VERSION "HNNBNNNYNNNNNNNNNNNNNNNNNNNNNNNNNNNNNNNNNN/4/%%%/4/'%**4NNN///"

NS_ :

BS_:

BU_: BAP_Tester BCM1 Gateway Gateway_PAG Klima_MSB Lift_VA VAS_L VAS_R

BO_ 1648 Motor_18: 8 Gateway
 SG_ MO_max_Ladedruck : 0|6@1+ (0.1,0) [0.0|6.3] "Unit_Bar"  Vector__XXX
 SG_ MO_ANC_Kennfeld_Anf : 6|2@1+ (1.0,0.0) [0.0|3] ""  Vector__XXX
 SG_ MO_Bremslicht_Reku : 8|1@1+ (1.0,0.0) [0.0|1] ""  Vector__XXX
 SG_ MO_StartStopp_PopUp : 9|2@1+ (1.0,0.0) [0.0|3] ""  Vector__XXX
 SG_ MO1_Sperr_Info_WFS : 11|1@1+ (1.0,0.0) [0.0|1] ""  Vector__XXX
 SG_ MO1_Freigabe_Info_WFS : 12|1@1+ (1.0,0.0) [0.0|1] ""  Vector__XXX
 SG_ MO_EPCL : 13|3@1+ (1.0,0.0) [0.0|7] ""  Vector__XXX
 SG_ MO_Zylabsch_Texte_02 : 16|4@1+ (1.0,0.0) [0.0|15] ""  Vector__XXX
 SG_ MO_Fahrzeugtyp : 20|3@1+ (1.0,0.0) [0.0|7] ""  Vector__XXX
 SG_ MO_NMAX_Schaltanzeige : 23|9@1+ (25,0) [0|12775] "Unit_MinutInver"  Vector__XXX
 SG_ MO_Abstellzeit : 32|8@1+ (8,0) [0|2024] "Unit_Minut"  BCM1,Klima_MSB
 SG_ MO_Abstellzeit_Status : 40|2@1+ (1.0,0.0) [0.0|3] ""  BCM1,Klima_MSB
 SG_ MO1_Freigabe_Verfallsinfo_WFS : 42|1@1+ (1.0,0.0) [0.0|1] ""  Vector__XXX
 SG_ MO_Hybrid_StartStopp_LED : 43|2@1+ (1.0,0.0) [0.0|3] ""  BCM1
 SG_ MO_Fehler_Zylabsch : 45|2@1+ (1.0,0.0) [0.0|3] ""  Vector__XXX
 SG_ MO_Anzahl_Abgesch_Zyl : 47|3@1+ (1.0,0.0) [0.0|7] ""  Vector__XXX
 SG_ MO_Zylabsch_Texte : 50|2@1+ (1.0,0.0) [0.0|3] ""  Vector__XXX
 SG_ MO_Ethanol_BS_Texte : 52|3@1+ (1.0,0.0) [0.0|7] ""  Vector__XXX
 SG_ MO_Drehzahl_Warnung : 55|1@1+ (1.0,0.0) [0.0|1] ""  Vector__XXX
 SG_ MO_obere_Drehzahlgrenze : 56|8@1+ (50,0) [50|12750] "Unit_MinutInver"  Vector__XXX

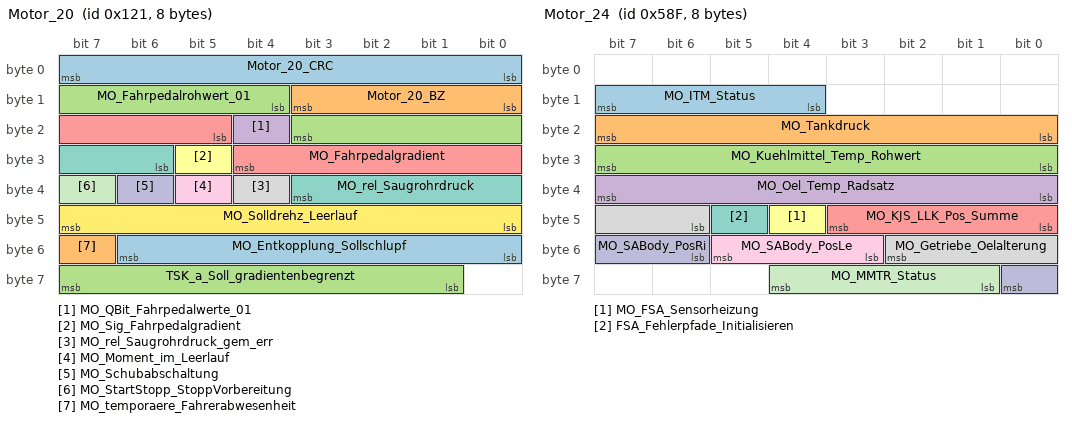
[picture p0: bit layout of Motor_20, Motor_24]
BO_ 289 Motor_20: 8 Gateway
 SG_ Motor_20_CRC : 0|8@1+ (1,0) [0|255] ""  Vector__XXX
 SG_ Motor_20_BZ : 8|4@1+ (1,0) [0|15] ""  Vector__XXX
 SG_ MO_Fahrpedalrohwert_01 : 12|8@1+ (0.4,0) [0.0|101.6] "Unit_PerCent"  BCM1
 SG_ MO_QBit_Fahrpedalwerte_01 : 20|1@1+ (1.0,0.0) [0.0|1] ""  Vector__XXX
 SG_ MO_Fahrpedalgradient : 21|8@1+ (25,0) [0|6350] "Unit_PerCentPerSecon"  Vector__XXX
 SG_ MO_Sig_Fahrpedalgradient : 29|1@1+ (1.0,0.0) [0.0|1] ""  Vector__XXX
 SG_ MO_rel_Saugrohrdruck : 30|6@1+ (18,0) [0|1116] "Unit_MilliBar"  Vector__XXX
 SG_ MO_rel_Saugrohrdruck_gem_err : 36|1@1+ (1.0,0.0) [0.0|1] ""  Vector__XXX
 SG_ MO_Moment_im_Leerlauf : 37|1@1+ (1.0,0.0) [0.0|1] ""  Vector__XXX
 SG_ MO_Schubabschaltung : 38|1@1+ (1.0,0.0) [0.0|1] ""  Vector__XXX
 SG_ MO_StartStopp_StoppVorbereitung : 39|1@1+ (1.0,0.0) [0.0|1] ""  Vector__XXX
 SG_ MO_Solldrehz_Leerlauf : 40|8@1+ (10,0) [0|2540] "Unit_MinutInver"  Vector__XXX
 SG_ MO_Entkopplung_Sollschlupf : 48|7@1+ (20,0) [0|2480] "Unit_MinutInver"  Vector__XXX
 SG_ MO_temporaere_Fahrerabwesenheit : 55|1@1+ (1.0,0.0) [0.0|1] ""  Vector__XXX
 SG_ TSK_a_Soll_gradientenbegrenzt : 57|7@1+ (0.1,-7.2) [-7.2|5.4] "Unit_MeterPerSeconSquar"  Vector__XXX

BO_ 1423 Motor_24: 8 Gateway
 SG_ MO_ITM_Status : 12|4@1+ (1.0,0.0) [0.0|15] ""  BCM1,Klima_MSB
 SG_ MO_Tankdruck : 16|8@1+ (2,-250) [-250|256] "Unit_MilliBar"  Vector__XXX
 SG_ MO_Kuehlmittel_Temp_Rohwert : 24|8@1+ (0.75,-48) [-48.00|141.75] "Unit_DegreCelsi"  Vector__XXX
 SG_ MO_Oel_Temp_Radsatz : 32|8@1+ (1,-60) [-60|193] "Unit_DegreCelsi"  Vector__XXX
 SG_ MO_KJS_LLK_Pos_Summe : 40|4@1+ (10,0) [0|100] "Unit_PerCent"  Vector__XXX
 SG_ MO_FSA_Sensorheizung : 44|1@1+ (1.0,0.0) [0.0|1] ""  BCM1
 SG_ FSA_Fehlerpfade_Initialisieren : 45|1@1+ (1.0,0.0) [0.0|1] ""  BCM1
 SG_ MO_Getriebe_Oelalterung : 46|5@1+ (5,0) [0|100] "Unit_PerCent"  Vector__XXX
 SG_ MO_SABody_PosLe : 51|3@1+ (20,-20) [0|100] "Unit_PerCent"  Vector__XXX
 SG_ MO_SABody_PosRi : 54|3@1+ (20,-20) [0|100] "Unit_PerCent"  Vector__XXX
 SG_ MO_MMTR_Status : 57|4@1+ (1.0,0.0) [0.0|15] ""  Klima_MSB

BO_ 967 Motor_26: 8 Gateway
 SG_ MO_Kuehlerluefter_MUX M  : 0|1@1+ (1.0,0.0) [0.0|1] ""  BCM1,Klima_MSB
 SG_ MO_Kuehlerluefter_1 m0  : 1|7@1+ (1,0) [0|100] "Unit_PerCent"  BCM1,Klima_MSB
 SG_ MO_Kuehlerluefter_2 m1  : 1|7@1+ (1,0) [0|100] "Unit_PerCent"  BCM1,Klima_MSB
 SG_ MO_EFLEX_Lampe : 8|2@1+ (1.0,0.0) [0.0|3] ""  Vector__XXX
 SG_ MO_KJS_nicht_bereit : 10|1@1+ (1.0,0.0) [0.0|1] ""  Vector__XXX
 SG_ MO_ITM_Warnung_Pumpe : 11|1@1+ (1.0,0.0) [0.0|1] ""  Vector__XXX
 SG_ WIV_Anzeige_aktiv : 12|1@1+ (1.0,0.0) [0.0|1] ""  Vector__XXX
 SG_ WIV_Oelmin_Warn : 13|1@1+ (1.0,0.0) [0.0|1] ""  Vector__XXX
 SG_ WIV_Sensorfehler : 14|1@1+ (1.0,0.0) [0.0|1] ""  Vector__XXX
 SG_ WIV_Schieflage : 15|1@1+ (1.0,0.0) [0.0|1] ""  Vector__XXX
 SG_ WIV_Oelstand : 16|4@1+ (12.5,0) [0.0|100.0] "Unit_PerCent"  Vector__XXX
 SG_ MO_Zustand_HWP : 20|2@1+ (1.0,0.0) [0.0|3] ""  Vector__XXX
 SG_ OLEV_Systemstoerung : 22|1@1+ (1.0,0.0) [0.0|1] ""  Vector__XXX
 SG_ MO_Oelwarnung_max : 23|1@1+ (1.0,0.0) [0.0|1] ""  Vector__XXX
 SG_ WIV_Oelsystem_aktiv : 24|1@1+ (1.0,0.0) [0.0|1] ""  Vector__XXX
 SG_ WIV_nicht_betriebswarm : 25|1@1+ (1.0,0.0) [0.0|1] ""  Vector__XXX
 SG_ WIV_Ueberfuell_Warn : 26|1@1+ (1.0,0.0) [0.0|1] ""  Vector__XXX
 SG_ WIV_laufender_Motor : 27|1@1+ (1.0,0.0) [0.0|1] ""  Vector__XXX
 SG_ MO_E_Warnungen : 28|4@1+ (1.0,0.0) [0.0|15] ""  Vector__XXX
 SG_ MO_Text_Motorstart : 32|4@1+ (1.0,0.0) [0.0|15] ""  Vector__XXX
 SG_ MO_E_Texte : 36|4@1+ (1.0,0.0) [0.0|15] ""  Vector__XXX
 SG_ WIV_Oeldyn_avl : 40|1@1+ (1.0,0.0) [0.0|1] ""  Vector__XXX
 SG_ MO_Text_Partikelfil_Reg : 41|1@1+ (1,0) [0|1] ""  Vector__XXX
 SG_ OLEV_Oelstand_nicht_vorhanden : 42|1@1+ (1.0,0.0) [0.0|1] ""  Vector__XXX
 SG_ WIV_Oelmenge : 43|5@1+ (125,0) [0|3875] "Unit_MilliLiter"  Vector__XXX
 SG_ MO_Systemlampe : 48|1@1+ (1.0,0.0) [0.0|1] ""  Vector__XXX
 SG_ MO_OBD2_Lampe : 49|1@1+ (1.0,0.0) [0.0|1] ""  Vector__XXX
 SG_ MO_Heissleuchte : 50|1@1+ (1.0,0.0) [0.0|1] ""  Vector__XXX
 SG_ MO_Partikel_Lampe : 51|1@1+ (1.0,0.0) [0.0|1] ""  Vector__XXX
 SG_ MO_RedFahrleistung_Lampe : 52|1@1+ (1.0,0.0) [0.0|1] ""  Vector__XXX
 SG_ WIV_Oelstand_nicht_vorhanden : 53|1@1+ (1.0,0.0) [0.0|1] ""  Vector__XXX
 SG_ WIV_nachfuellanzeige_ein : 54|1@1+ (1.0,0.0) [0.0|1] ""  Vector__XXX
 SG_ WIV_Ueberfuell_deaktiv : 55|1@1+ (1.0,0.0) [0.0|1] ""  Vector__XXX
 SG_ WIV_Unterfuell_Warn : 56|1@1+ (1.0,0.0) [0.0|1] ""  Vector__XXX
 SG_ MO_Tankdeckel_Lampe : 57|1@1+ (1.0,0.0) [0.0|1] ""  Vector__XXX
 SG_ MO_Text_Tankdeckelwarn : 58|1@1+ (1.0,0.0) [0.0|1] ""  Vector__XXX
 SG_ MO_Vorglueh_Lampe : 59|1@1+ (1.0,0.0) [0.0|1] ""  Vector__XXX
 SG_ WIV_Oeldr_Warn_Motor : 60|1@1+ (1.0,0.0) [0.0|1] ""  Vector__XXX
 SG_ MO_E_Mode : 61|3@1+ (1.0,0.0) [0.0|7] ""  Vector__XXX

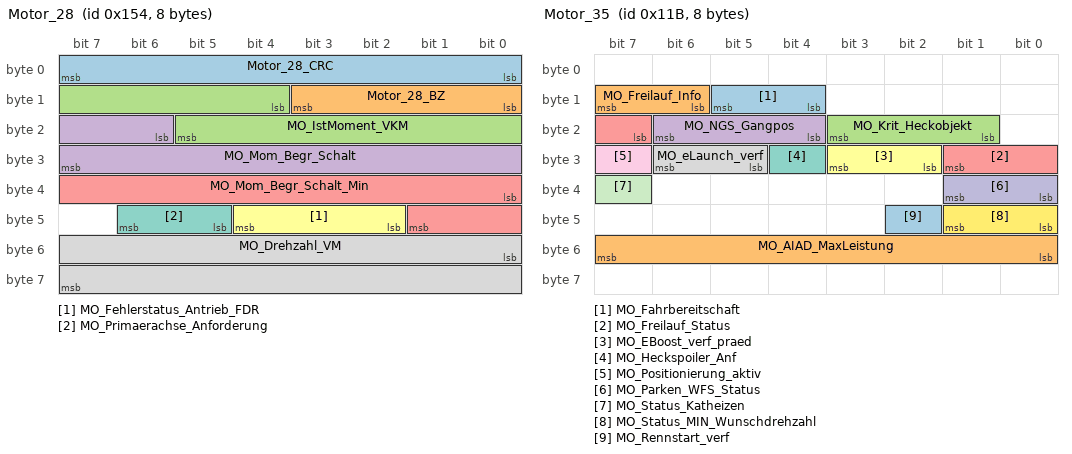
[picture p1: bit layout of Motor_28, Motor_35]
BO_ 340 Motor_28: 8 Gateway
 SG_ Motor_28_CRC : 0|8@1+ (1,0) [0|255] ""  Vector__XXX
 SG_ Motor_28_BZ : 8|4@1+ (1,0) [0|15] ""  Vector__XXX
 SG_ MO_IstMoment_VKM : 12|10@1+ (1,-509) [-509|509] ""  Vector__XXX
 SG_ MO_Mom_Begr_Schalt : 22|10@1+ (1,-509) [-509|509] ""  Vector__XXX
 SG_ MO_Mom_Begr_Schalt_Min : 32|10@1+ (1,-509) [-509|509] ""  Vector__XXX
 SG_ MO_Fehlerstatus_Antrieb_FDR : 42|3@1+ (1.0,0.0) [0.0|7] ""  Vector__XXX
 SG_ MO_Primaerachse_Anforderung : 45|2@1+ (1.0,0.0) [0.0|3] ""  Vector__XXX
 SG_ MO_Drehzahl_VM : 48|16@1+ (0.25,0) [0.00|16383.00] "Unit_MinutInver"  BCM1,Klima_MSB

BO_ 283 Motor_35: 8 Gateway
 SG_ MO_Fahrbereitschaft : 12|2@1+ (1.0,0.0) [0.0|3] ""  BCM1
 SG_ MO_Freilauf_Info : 14|2@1+ (1.0,0.0) [0.0|3] ""  Vector__XXX
 SG_ MO_Krit_Heckobjekt : 17|3@1+ (1.0,0.0) [0.0|7] ""  Vector__XXX
 SG_ MO_NGS_Gangpos : 20|3@1+ (1.0,0.0) [0.0|7] ""  Vector__XXX
 SG_ MO_Freilauf_Status : 23|3@1+ (1.0,0.0) [0.0|7] ""  Vector__XXX
 SG_ MO_EBoost_verf_praed : 26|2@1+ (1.0,0.0) [0.0|3] ""  Vector__XXX
 SG_ MO_Heckspoiler_Anf : 28|1@1+ (1.0,0.0) [0.0|1] ""  Vector__XXX
 SG_ MO_eLaunch_verf : 29|2@1+ (1.0,0.0) [0.0|3] ""  Vector__XXX
 SG_ MO_Positionierung_aktiv : 31|1@1+ (1.0,0.0) [0.0|1] ""  Vector__XXX
 SG_ MO_Parken_WFS_Status : 32|2@1+ (1.0,0.0) [0.0|3] ""  Vector__XXX
 SG_ MO_Status_Katheizen : 39|1@1+ (1.0,0.0) [0.0|1] ""  Vector__XXX
 SG_ MO_Status_MIN_Wunschdrehzahl : 40|2@1+ (1.0,0.0) [0.0|3] ""  Vector__XXX
 SG_ MO_Rennstart_verf : 42|1@1+ (1.0,0.0) [0.0|1] ""  Vector__XXX
 SG_ MO_AIAD_MaxLeistung : 48|8@1+ (100,0) [0|25400] "Unit_Watt"  Vector__XXX

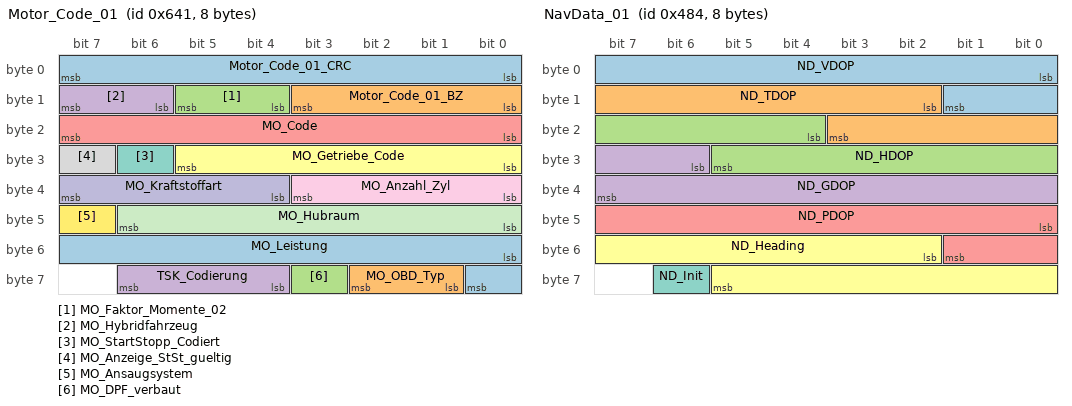
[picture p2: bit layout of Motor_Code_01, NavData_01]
BO_ 1601 Motor_Code_01: 8 Gateway
 SG_ Motor_Code_01_CRC : 0|8@1+ (1,0) [0|255] ""  BCM1
 SG_ Motor_Code_01_BZ : 8|4@1+ (1,0) [0|15] ""  BCM1
 SG_ MO_Faktor_Momente_02 : 12|2@1+ (1,0) [1|3] "Unit_NewtoMeter"  BCM1
 SG_ MO_Hybridfahrzeug : 14|2@1+ (1.0,0.0) [0.0|3] ""  BCM1
 SG_ MO_Code : 16|8@1+ (1,0) [0|255] ""  BCM1,Klima_MSB
 SG_ MO_Getriebe_Code : 24|6@1+ (1.0,0.0) [0.0|63] ""  BCM1,Klima_MSB
 SG_ MO_StartStopp_Codiert : 30|1@1+ (1.0,0.0) [0.0|1] ""  Lift_VA
 SG_ MO_Anzeige_StSt_gueltig : 31|1@1+ (1.0,0.0) [0.0|1] ""  Vector__XXX
 SG_ MO_Anzahl_Zyl : 32|4@1+ (1.0,0.0) [0.0|15] ""  Vector__XXX
 SG_ MO_Kraftstoffart : 36|4@1+ (1.0,0.0) [0.0|15] ""  BCM1
 SG_ MO_Hubraum : 40|7@1+ (0.1,0) [0.0|12.7] "Unit_Liter"  Vector__XXX
 SG_ MO_Ansaugsystem : 47|1@1+ (1.0,0.0) [0.0|1] ""  Vector__XXX
 SG_ MO_Leistung : 48|9@1+ (1,0) [0|511] "Unit_KiloWatt"  Vector__XXX
 SG_ MO_OBD_Typ : 57|2@1+ (1.0,0.0) [0.0|3] ""  BCM1
 SG_ MO_DPF_verbaut : 59|1@1+ (1.0,0.0) [0.0|1] ""  Vector__XXX
 SG_ TSK_Codierung : 60|3@1+ (1.0,0.0) [0.0|7] ""  Vector__XXX

BO_ 394 Motor_Hybrid_11: 8 Gateway
 SG_ MO_Ablaufstatus : 12|4@1+ (1.0,0.0) [0.0|15] ""  Vector__XXX
 SG_ MO_Ablaufstrg_Betriebszustand : 16|3@1+ (1.0,0.0) [0.0|7] ""  Vector__XXX
 SG_ MO_Ablaufstrg_Zustand_VKM_Ist : 19|1@1+ (1.0,0.0) [0.0|1] ""  Vector__XXX
 SG_ MO_Ablaufstrg_Kraftschluss_Ist : 20|1@1+ (1.0,0.0) [0.0|1] ""  Vector__XXX
 SG_ MO_Ablaufstrg_Zustand_K0_Ist : 21|1@1+ (1.0,0.0) [0.0|1] ""  Vector__XXX
 SG_ MO_Ablaufstrg_Kraftschluss2_Ist : 22|1@1+ (1.0,0.0) [0.0|1] ""  Vector__XXX
 SG_ MO_HYB_LowSpeedModus : 23|1@1+ (1.0,0.0) [0.0|1] ""  Vector__XXX
 SG_ MO_Ablaufstrg_Zustand_VKM_Ziel : 24|1@1+ (1.0,0.0) [0.0|1] ""  Vector__XXX
 SG_ MO_Ablaufstrg_Kraftschluss_Ziel : 25|1@1+ (1.0,0.0) [0.0|1] ""  Vector__XXX
 SG_ MO_Ablaufstrg_Zustand_K0_Ziel : 26|1@1+ (1.0,0.0) [0.0|1] ""  Vector__XXX
 SG_ MO_Ablaufstrg_Kraftschluss2_Ziel : 27|1@1+ (1.0,0.0) [0.0|1] ""  Vector__XXX
 SG_ MO_HYB_Stoppmodus : 28|1@1+ (1.0,0.0) [0.0|1] ""  Vector__XXX
 SG_ MO_Auth_Aufforderung_WFS : 29|1@1+ (1.0,0.0) [0.0|1] ""  Vector__XXX
 SG_ MO_Start_Dynamik : 30|3@1+ (1.0,0.0) [0.0|7] ""  Vector__XXX
 SG_ MO_Start_Art : 33|3@1+ (1.0,0.0) [0.0|7] ""  BCM1,Klima_MSB
 SG_ MO_Abstellposition_02 : 36|8@1+ (2,0) [0|508] "Unit_DegreOfArc"  Vector__XXX
 SG_ MO_Mom_Freiheit_Sekundaerachse : 44|1@1+ (1.0,0.0) [0.0|1] ""  Vector__XXX
 SG_ MO_Nachlaufzeit_Kuehlerluefter : 45|6@1+ (15,0) [0|945] "Unit_Secon"  Vector__XXX
 SG_ MO_Tankklappensteuerung : 51|2@1+ (1.0,0.0) [0.0|3] ""  Vector__XXX
 SG_ MO_HYB_E_Faktor : 53|4@1+ (1.0,0.0) [0.0|15] ""  Vector__XXX
 SG_ MO_HYB_EMode_Info : 57|2@1+ (1.0,0.0) [0.0|3] ""  Vector__XXX
 SG_ MO_HYB_Adaption_aktiv : 59|1@1+ (1.0,0.0) [0.0|1] ""  Vector__XXX

BO_ 1156 NavData_01: 8 Gateway
 SG_ ND_VDOP : 0|10@1+ (0.025,0) [0.000|25.000] ""  Vector__XXX
 SG_ ND_TDOP : 10|10@1+ (0.025,0) [0.000|25.000] ""  Vector__XXX
 SG_ ND_HDOP : 20|10@1+ (0.025,0) [0.000|25.000] ""  Vector__XXX
 SG_ ND_GDOP : 30|10@1+ (0.025,0) [0.000|25.000] ""  Vector__XXX
 SG_ ND_PDOP : 40|10@1+ (0.025,0) [0.000|25.000] ""  Vector__XXX
 SG_ ND_Heading : 50|12@1+ (0.1,0) [0.0|359.9] "Unit_DegreOfArc"  BCM1,Klima_MSB
 SG_ ND_Init : 62|1@1+ (1.0,0.0) [0.0|1] ""  BCM1

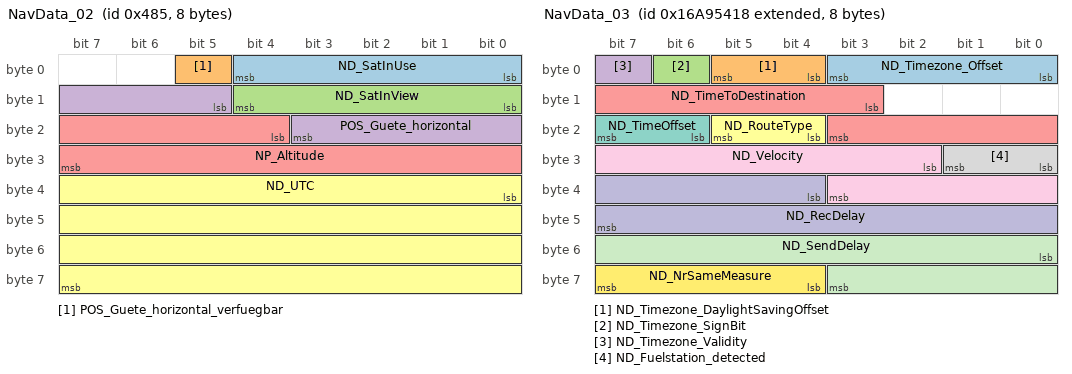
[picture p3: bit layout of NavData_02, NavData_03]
BO_ 1157 NavData_02: 8 Gateway
 SG_ ND_SatInUse : 0|5@1+ (1,0) [0|29] ""  Vector__XXX
 SG_ POS_Guete_horizontal_verfuegbar : 5|1@1+ (1.0,0.0) [0.0|1] ""  Vector__XXX
 SG_ ND_SatInView : 8|5@1+ (1,0) [0|29] ""  Vector__XXX
 SG_ POS_Guete_horizontal : 13|7@1+ (2,0) [0|246] "Unit_Meter"  Vector__XXX
 SG_ NP_Altitude : 20|12@1+ (2,-500) [-500|7686] "Unit_Meter"  BCM1,Klima_MSB
 SG_ ND_UTC : 32|32@1+ (1,0) [0|4294967293] "Unit_Secon"  BCM1

BO_ 2527679512 NavData_03: 8 Gateway
 SG_ ND_Timezone_Offset : 0|4@1+ (1,0) [0|12] "Unit_Hours"  Klima_MSB
 SG_ ND_Timezone_DaylightSavingOffset : 4|2@1+ (30,0) [0|60] "Unit_Minut"  Klima_MSB
 SG_ ND_Timezone_SignBit : 6|1@1+ (1.0,0.0) [0.0|1] ""  Klima_MSB
 SG_ ND_Timezone_Validity : 7|1@1+ (1.0,0.0) [0.0|1] ""  Klima_MSB
 SG_ ND_TimeToDestination : 11|9@1+ (1,0) [0|509] "Unit_Minut"  Vector__XXX
 SG_ ND_RouteType : 20|2@1+ (1.0,0.0) [0.0|3] ""  Vector__XXX
 SG_ ND_TimeOffset : 22|2@1+ (1.0,0.0) [0.0|3] ""  Vector__XXX
 SG_ ND_Fuelstation_detected : 24|2@1+ (1.0,0.0) [0.0|3] ""  Vector__XXX
 SG_ ND_Velocity : 26|10@1+ (0.1,0) [0.0|102.1] "Unit_MeterPerSecon"  Vector__XXX
 SG_ ND_RecDelay : 36|12@1+ (1,0) [0|4093] "Unit_MilliSecon"  Vector__XXX
 SG_ ND_SendDelay : 48|12@1+ (1,0) [0|4093] "Unit_MilliSecon"  Vector__XXX
 SG_ ND_NrSameMeasure : 60|4@1+ (1,0) [0|8] ""  Vector__XXX

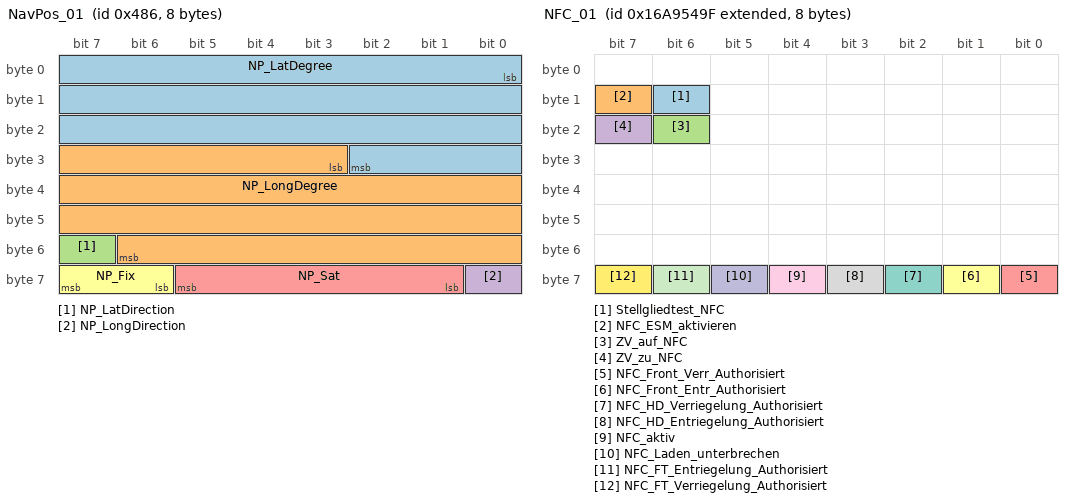
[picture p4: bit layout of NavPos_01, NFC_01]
BO_ 1158 NavPos_01: 8 Gateway
 SG_ NP_LatDegree : 0|27@1+ (0.000001,0) [0.000000|90.000000] "Unit_DegreOfArc"  BCM1,Klima_MSB
 SG_ NP_LongDegree : 27|28@1+ (0.000001,0) [0.000000|180.000000] "Unit_DegreOfArc"  BCM1,Klima_MSB
 SG_ NP_LatDirection : 55|1@1+ (1.0,0.0) [0.0|1] ""  BCM1,Klima_MSB
 SG_ NP_LongDirection : 56|1@1+ (1.0,0.0) [0.0|1] ""  BCM1,Klima_MSB
 SG_ NP_Sat : 57|5@1+ (1,0) [0|29] ""  Vector__XXX
 SG_ NP_Fix : 62|2@1+ (1.0,0.0) [0.0|3] ""  Vector__XXX

BO_ 2589283496 NavPos_02_Map_Matched: 8 Gateway
 SG_ POS_MUX M  : 0|2@1+ (1.0,0.0) [0.0|3] ""  Klima_MSB
 SG_ POS_ODD_EVEN : 2|1@1+ (1.0,0.0) [0.0|1] ""  Vector__XXX
 SG_ POS_PosStati m0  : 3|4@1+ (1.0,0.0) [0.0|15] ""  Klima_MSB
 SG_ POS_Heading m1  : 4|12@1+ (0.1,0) [0.0|409.5] "Unit_DegreOfArc"  Klima_MSB
 SG_ POS_LatDirection m0  : 7|1@1+ (1.0,0.0) [0.0|1] ""  Klima_MSB
 SG_ POS_LatDegree m0  : 8|27@1+ (0.000001,0) [0.000000|90.000000] "Unit_DegreOfArc"  Klima_MSB
 SG_ POS_Last_GPS_Sync m1  : 16|14@1+ (1,0) [0|16383] "Unit_Secon"  Vector__XXX
 SG_ POS_Heading_Trust m1  : 30|2@1+ (1.0,0.0) [0.0|3] ""  Klima_MSB
 SG_ POS_UTC_REF m1  : 32|32@1+ (1,0) [0|4294967295] "Unit_Secon"  Klima_MSB
 SG_ POS_LongDirection m0  : 35|1@1+ (1.0,0.0) [0.0|1] ""  Klima_MSB
 SG_ POS_LongDegree m0  : 36|28@1+ (0.000001,0) [0.000000|180.000000] "Unit_DegreOfArc"  Klima_MSB

BO_ 2527679647 NFC_01: 8 Gateway
 SG_ Stellgliedtest_NFC : 14|1@1+ (1.0,0.0) [0.0|1] ""  Vector__XXX
 SG_ NFC_ESM_aktivieren : 15|1@1+ (1.0,0.0) [0.0|1] ""  Vector__XXX
 SG_ ZV_auf_NFC : 22|1@1+ (1.0,0.0) [0.0|1] ""  BCM1
 SG_ ZV_zu_NFC : 23|1@1+ (1.0,0.0) [0.0|1] ""  BCM1
 SG_ NFC_Front_Verr_Authorisiert : 56|1@1+ (1.0,0.0) [0.0|1] ""  BCM1
 SG_ NFC_Front_Entr_Authorisiert : 57|1@1+ (1.0,0.0) [0.0|1] ""  BCM1
 SG_ NFC_HD_Verriegelung_Authorisiert : 58|1@1+ (1.0,0.0) [0.0|1] ""  Vector__XXX
 SG_ NFC_HD_Entriegelung_Authorisiert : 59|1@1+ (1.0,0.0) [0.0|1] ""  Vector__XXX
 SG_ NFC_aktiv : 60|1@1+ (1.0,0.0) [0.0|1] ""  Vector__XXX
 SG_ NFC_Laden_unterbrechen : 61|1@1+ (1.0,0.0) [0.0|1] ""  Vector__XXX
 SG_ NFC_FT_Entriegelung_Authorisiert : 62|1@1+ (1.0,0.0) [0.0|1] ""  Vector__XXX
 SG_ NFC_FT_Verriegelung_Authorisiert : 63|1@1+ (1.0,0.0) [0.0|1] ""  Vector__XXX

BO_ 1696 NightVision_01: 8 Gateway
 SG_ NV_aktiv : 12|1@1+ (1.0,0.0) [0.0|1] ""  Vector__XXX
 SG_ NV_Texte : 13|3@1+ (1.0,0.0) [0.0|7] ""  Vector__XXX
 SG_ NV_Gong : 16|2@1+ (1.0,0.0) [0.0|3] ""  Vector__XXX
 SG_ NV_Symbol : 18|1@1+ (1.0,0.0) [0.0|1] ""  BCM1
 SG_ NV_Hinweise : 19|2@1+ (1.0,0.0) [0.0|3] ""  Vector__XXX
 SG_ NV_Piktogramm_aktiv : 21|1@1+ (1.0,0.0) [0.0|1] ""  Vector__XXX
 SG_ NV_Akustik_deaktiviert_Icon : 22|1@1+ (1.0,0.0) [0.0|1] ""  Vector__XXX
 SG_ NV_FGM_deaktiviert_Icon : 23|1@1+ (1.0,0.0) [0.0|1] ""  Vector__XXX
 SG_ NV_Markierungslicht_links : 24|1@1+ (1.0,0.0) [0.0|1] ""  Vector__XXX
 SG_ NV_Markierungslicht_rechts : 25|1@1+ (1.0,0.0) [0.0|1] ""  Vector__XXX
 SG_ NV_Symbol_Tierwarnung : 26|1@1+ (1.0,0.0) [0.0|1] ""  BCM1
 SG_ NV_Anf_Prefill : 27|1@1+ (1.0,0.0) [0.0|1] ""  Vector__XXX
 SG_ NV_HBA_Parameter : 28|2@1+ (1.0,0.0) [0.0|3] ""  Vector__XXX
 SG_ NV_LED_Leiste : 30|2@1+ (1.0,0.0) [0.0|3] ""  Vector__XXX
 SG_ NV_PreSense_Status : 32|2@1+ (1.0,0.0) [0.0|3] ""  Vector__XXX
 SG_ NV_PreSense_Modus_System : 34|1@1+ (1.0,0.0) [0.0|1] ""  Vector__XXX
 SG_ NV_PreSense_Modus_Warnung : 35|3@1+ (1.0,0.0) [0.0|7] ""  Vector__XXX
 SG_ NV_FAS_Fkt_Status : 38|2@1+ (1.0,0.0) [0.0|3] ""  Vector__XXX
 SG_ NV_Akt_Status_MMI : 40|2@1+ (1.0,0.0) [0.0|3] ""  Vector__XXX
 SG_ NV_AnforderungBildaufschaltung : 42|1@1+ (1.0,0.0) [0.0|1] ""  Vector__XXX

BO_ 2600468494 NMH_BCM1: 8 BCM1
 SG_ NM_BCM1_SNI : 0|8@1+ (1.0,0.0) [0.0|255] ""  Gateway,Gateway_PAG,Klima_MSB,Lift_VA,VAS_L,VAS_R
 SG_ NM_BCM1_CBV_AWB : 12|1@1+ (1.0,0.0) [0.0|1] ""  Gateway,Gateway_PAG
 SG_ NM_BCM1_CBV_CRI : 14|1@1+ (1.0,0.0) [0.0|1] ""  Gateway,Gateway_PAG,Klima_MSB,Lift_VA,VAS_L,VAS_R
 SG_ NM_BCM1_NM_State : 16|6@1+ (1.0,0.0) [0.0|63] ""  Vector__XXX
 SG_ NM_BCM1_Car_Wakeup : 22|1@1+ (1.0,0.0) [0.0|1] ""  Gateway,Gateway_PAG
 SG_ NM_BCM1_UDS_CC : 23|1@1+ (1.0,0.0) [0.0|1] ""  Vector__XXX
 SG_ NM_BCM1_NM_aktiv_KL15 : 24|1@1+ (1.0,0.0) [0.0|1] ""  Vector__XXX
 SG_ NM_BCM1_NM_aktiv_Diagnose : 25|1@1+ (1.0,0.0) [0.0|1] ""  Vector__XXX
 SG_ NM_BCM1_NM_aktiv_Tmin : 26|1@1+ (1.0,0.0) [0.0|1] ""  Vector__XXX
 SG_ NM_BCM1_NM_aktiv_Notlaufblinken : 27|1@1+ (1.0,0.0) [0.0|1] ""  Vector__XXX
 SG_ NM_BCM1_NM_aktiv_ComingHome : 28|1@1+ (1.0,0.0) [0.0|1] ""  Vector__XXX
 SG_ NM_BCM1_NM_aktiv_LeavingHome : 29|1@1+ (1.0,0.0) [0.0|1] ""  Vector__XXX
 SG_ NM_BCM1_NM_aktiv_Taster_Schalter : 30|1@1+ (1.0,0.0) [0.0|1] ""  Vector__XXX
 SG_ NM_BCM1_NM_aktiv_LIM : 31|1@1+ (1.0,0.0) [0.0|1] ""  Vector__XXX
 SG_ NM_BCM1_NM_aktiv_Innenlicht_Dim : 32|1@1+ (1.0,0.0) [0.0|1] ""  Vector__XXX
 SG_ NM_BCM1_NM_aktiv_Aussenlicht : 33|1@1+ (1.0,0.0) [0.0|1] ""  Vector__XXX
 SG_ NM_BCM1_NM_aktiv_Klimatisierung : 34|1@1+ (1.0,0.0) [0.0|1] ""  Vector__XXX
 SG_ NM_BCM1_CAB : 40|24@1+ (1.0,0.0) [0.0|16777215] ""  Gateway,Gateway_PAG,Klima_MSB,Lift_VA,VAS_L,VAS_R

BO_ 2600468496 NMH_Gateway: 8 Gateway
 SG_ NM_Gateway_SNI : 0|8@1+ (1.0,0.0) [0.0|255] ""  BCM1,Klima_MSB,Lift_VA,VAS_L,VAS_R
 SG_ NM_Gateway_CBV_AWB : 12|1@1+ (1.0,0.0) [0.0|1] ""  Vector__XXX
 SG_ NM_Gateway_CBV_CRI : 14|1@1+ (1.0,0.0) [0.0|1] ""  BCM1,Klima_MSB,Lift_VA,VAS_L,VAS_R
 SG_ NM_Gateway_NM_State : 16|6@1+ (1.0,0.0) [0.0|63] ""  Vector__XXX
 SG_ NM_Gateway_Car_Wakeup : 22|1@1+ (1.0,0.0) [0.0|1] ""  Vector__XXX
 SG_ NM_Gateway_UDS_CC : 23|1@1+ (1.0,0.0) [0.0|1] ""  Vector__XXX
 SG_ NM_Gateway_NM_aktiv_KL15 : 24|1@1+ (1.0,0.0) [0.0|1] ""  Vector__XXX
 SG_ NM_Gateway_NM_aktiv_Diagnose : 25|1@1+ (1.0,0.0) [0.0|1] ""  Vector__XXX
 SG_ NM_Gateway_NM_aktiv_Tmin : 26|1@1+ (1.0,0.0) [0.0|1] ""  Vector__XXX
 SG_ NM_Gateway_NM_aktiv_CWU : 27|1@1+ (1.0,0.0) [0.0|1] ""  Vector__XXX
 SG_ NM_Gateway_NM_aktiv_FC : 28|1@1+ (1.0,0.0) [0.0|1] ""  Vector__XXX
 SG_ NM_Gateway_NM_aktiv_Connect : 29|1@1+ (1.0,0.0) [0.0|1] ""  Vector__XXX
 SG_ NM_Gateway_NM_aktiv_EM : 30|1@1+ (1.0,0.0) [0.0|1] ""  Vector__XXX
 SG_ NM_Gateway_NM_aktiv_OBDC : 31|1@1+ (1.0,0.0) [0.0|1] ""  Vector__XXX
 SG_ NM_Gateway_NM_aktiv_Buskopplung : 32|1@1+ (1.0,0.0) [0.0|1] ""  Vector__XXX
 SG_ NM_Gateway_NM_aktiv_LIN2 : 33|1@1+ (1.0,0.0) [0.0|1] ""  Vector__XXX
 SG_ NM_Gateway_NM_aktiv_Fremdladung : 34|1@1+ (1.0,0.0) [0.0|1] ""  Vector__XXX
 SG_ NM_Gateway_CAB : 40|24@1+ (1.0,0.0) [0.0|16777215] ""  BCM1,Klima_MSB,Lift_VA,VAS_L,VAS_R

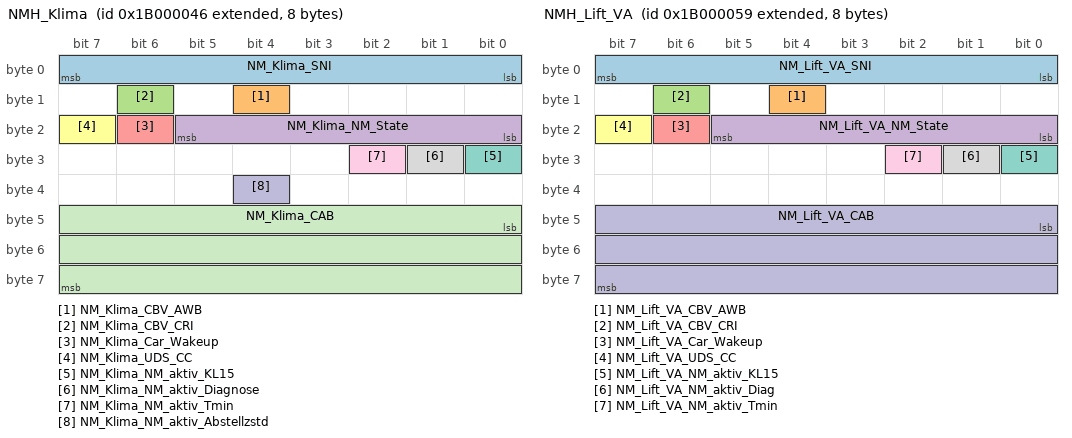
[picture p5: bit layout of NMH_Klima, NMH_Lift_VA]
BO_ 2600468550 NMH_Klima: 8 Klima_MSB
 SG_ NM_Klima_SNI : 0|8@1+ (1.0,0.0) [0.0|255] ""  BCM1,Gateway,Gateway_PAG,Klima_MSB,Lift_VA,VAS_L,VAS_R
 SG_ NM_Klima_CBV_AWB : 12|1@1+ (1.0,0.0) [0.0|1] ""  Gateway,Gateway_PAG
 SG_ NM_Klima_CBV_CRI : 14|1@1+ (1.0,0.0) [0.0|1] ""  BCM1,Gateway,Gateway_PAG,Klima_MSB,Lift_VA,VAS_L,VAS_R
 SG_ NM_Klima_NM_State : 16|6@1+ (1.0,0.0) [0.0|63] ""  Vector__XXX
 SG_ NM_Klima_Car_Wakeup : 22|1@1+ (1.0,0.0) [0.0|1] ""  Gateway,Gateway_PAG
 SG_ NM_Klima_UDS_CC : 23|1@1+ (1.0,0.0) [0.0|1] ""  Vector__XXX
 SG_ NM_Klima_NM_aktiv_KL15 : 24|1@1+ (1.0,0.0) [0.0|1] ""  Vector__XXX
 SG_ NM_Klima_NM_aktiv_Diagnose : 25|1@1+ (1.0,0.0) [0.0|1] ""  Vector__XXX
 SG_ NM_Klima_NM_aktiv_Tmin : 26|1@1+ (1.0,0.0) [0.0|1] ""  Vector__XXX
 SG_ NM_Klima_NM_aktiv_Abstellzstd : 36|1@1+ (1.0,0.0) [0.0|1] ""  Vector__XXX
 SG_ NM_Klima_CAB : 40|24@1+ (1.0,0.0) [0.0|16777215] ""  BCM1,Gateway,Gateway_PAG,Klima_MSB,Lift_VA,VAS_L,VAS_R

BO_ 2600468569 NMH_Lift_VA: 8 Lift_VA
 SG_ NM_Lift_VA_SNI : 0|8@1+ (1.0,0.0) [0.0|255] ""  BCM1,Gateway,Gateway_PAG,Klima_MSB,VAS_L,VAS_R
 SG_ NM_Lift_VA_CBV_AWB : 12|1@1+ (1.0,0.0) [0.0|1] ""  Vector__XXX
 SG_ NM_Lift_VA_CBV_CRI : 14|1@1+ (1.0,0.0) [0.0|1] ""  BCM1,Gateway,Gateway_PAG,Klima_MSB,VAS_L,VAS_R
 SG_ NM_Lift_VA_NM_State : 16|6@1+ (1.0,0.0) [0.0|63] ""  Vector__XXX
 SG_ NM_Lift_VA_Car_Wakeup : 22|1@1+ (1.0,0.0) [0.0|1] ""  Vector__XXX
 SG_ NM_Lift_VA_UDS_CC : 23|1@1+ (1.0,0.0) [0.0|1] ""  Vector__XXX
 SG_ NM_Lift_VA_NM_aktiv_KL15 : 24|1@1+ (1.0,0.0) [0.0|1] ""  Vector__XXX
 SG_ NM_Lift_VA_NM_aktiv_Diag : 25|1@1+ (1.0,0.0) [0.0|1] ""  Vector__XXX
 SG_ NM_Lift_VA_NM_aktiv_Tmin : 26|1@1+ (1.0,0.0) [0.0|1] ""  Vector__XXX
 SG_ NM_Lift_VA_CAB : 40|24@1+ (1.0,0.0) [0.0|16777215] ""  BCM1,Gateway,Gateway_PAG,Klima_MSB,VAS_L,VAS_R

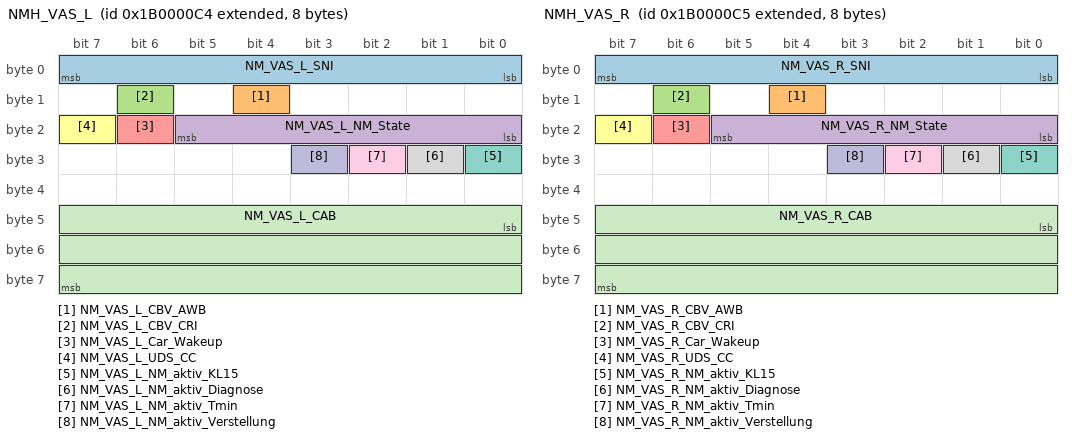
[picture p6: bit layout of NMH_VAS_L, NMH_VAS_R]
BO_ 2600468676 NMH_VAS_L: 8 VAS_L
 SG_ NM_VAS_L_SNI : 0|8@1+ (1.0,0.0) [0.0|255] ""  BCM1,Gateway,Gateway_PAG,Klima_MSB,Lift_VA,VAS_R
 SG_ NM_VAS_L_CBV_AWB : 12|1@1+ (1.0,0.0) [0.0|1] ""  Gateway,Gateway_PAG
 SG_ NM_VAS_L_CBV_CRI : 14|1@1+ (1.0,0.0) [0.0|1] ""  BCM1,Gateway,Gateway_PAG,Klima_MSB,Lift_VA,VAS_R
 SG_ NM_VAS_L_NM_State : 16|6@1+ (1.0,0.0) [0.0|63] ""  Vector__XXX
 SG_ NM_VAS_L_Car_Wakeup : 22|1@1+ (1.0,0.0) [0.0|1] ""  Gateway,Gateway_PAG
 SG_ NM_VAS_L_UDS_CC : 23|1@1+ (1.0,0.0) [0.0|1] ""  Vector__XXX
 SG_ NM_VAS_L_NM_aktiv_KL15 : 24|1@1+ (1.0,0.0) [0.0|1] ""  Vector__XXX
 SG_ NM_VAS_L_NM_aktiv_Diagnose : 25|1@1+ (1.0,0.0) [0.0|1] ""  Vector__XXX
 SG_ NM_VAS_L_NM_aktiv_Tmin : 26|1@1+ (1.0,0.0) [0.0|1] ""  Vector__XXX
 SG_ NM_VAS_L_NM_aktiv_Verstellung : 27|1@1+ (1.0,0.0) [0.0|1] ""  Vector__XXX
 SG_ NM_VAS_L_CAB : 40|24@1+ (1.0,0.0) [0.0|16777215] ""  BCM1,Gateway,Gateway_PAG,Klima_MSB,Lift_VA,VAS_R

BO_ 2600468677 NMH_VAS_R: 8 VAS_R
 SG_ NM_VAS_R_SNI : 0|8@1+ (1.0,0.0) [0.0|255] ""  BCM1,Gateway,Gateway_PAG,Klima_MSB,Lift_VA,VAS_L
 SG_ NM_VAS_R_CBV_AWB : 12|1@1+ (1.0,0.0) [0.0|1] ""  Gateway,Gateway_PAG
 SG_ NM_VAS_R_CBV_CRI : 14|1@1+ (1.0,0.0) [0.0|1] ""  BCM1,Gateway,Gateway_PAG,Klima_MSB,Lift_VA,VAS_L
 SG_ NM_VAS_R_NM_State : 16|6@1+ (1.0,0.0) [0.0|63] ""  Vector__XXX
 SG_ NM_VAS_R_Car_Wakeup : 22|1@1+ (1.0,0.0) [0.0|1] ""  Gateway,Gateway_PAG
 SG_ NM_VAS_R_UDS_CC : 23|1@1+ (1.0,0.0) [0.0|1] ""  Vector__XXX
 SG_ NM_VAS_R_NM_aktiv_KL15 : 24|1@1+ (1.0,0.0) [0.0|1] ""  Vector__XXX
 SG_ NM_VAS_R_NM_aktiv_Diagnose : 25|1@1+ (1.0,0.0) [0.0|1] ""  Vector__XXX
 SG_ NM_VAS_R_NM_aktiv_Tmin : 26|1@1+ (1.0,0.0) [0.0|1] ""  Vector__XXX
 SG_ NM_VAS_R_NM_aktiv_Verstellung : 27|1@1+ (1.0,0.0) [0.0|1] ""  Vector__XXX
 SG_ NM_VAS_R_CAB : 40|24@1+ (1.0,0.0) [0.0|16777215] ""  BCM1,Gateway,Gateway_PAG,Klima_MSB,Lift_VA,VAS_L

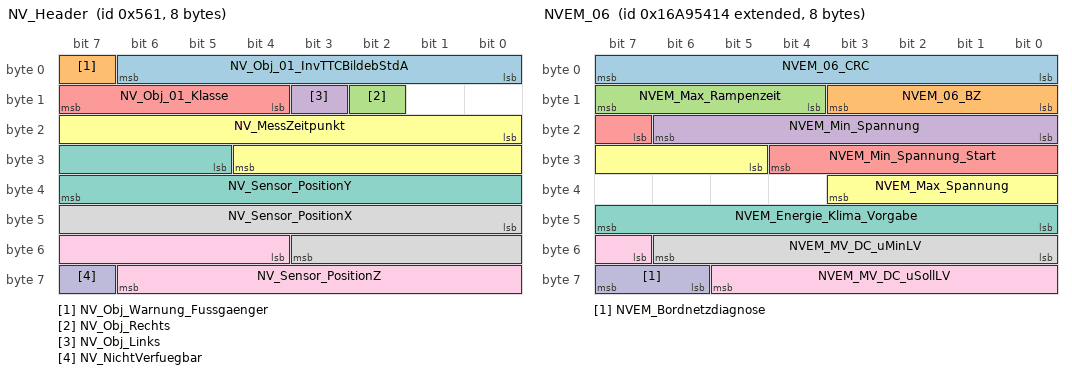
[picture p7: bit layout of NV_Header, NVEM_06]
BO_ 1377 NV_Header: 8 Gateway
 SG_ NV_Obj_01_InvTTCBildebStdA : 0|7@1+ (0.0625,0) [0.0000|7.8750] "Unit_Hertz"  Vector__XXX
 SG_ NV_Obj_Warnung_Fussgaenger : 7|1@1+ (1.0,0.0) [0.0|1] ""  Vector__XXX
 SG_ NV_Obj_Rechts : 10|1@1+ (1.0,0.0) [0.0|1] ""  BCM1
 SG_ NV_Obj_Links : 11|1@1+ (1.0,0.0) [0.0|1] ""  BCM1
 SG_ NV_Obj_01_Klasse : 12|4@1+ (1.0,0.0) [0.0|15] ""  BCM1
 SG_ NV_MessZeitpunkt : 16|13@1+ (0.001,0) [0.000|8.190] "Unit_Secon"  Vector__XXX
 SG_ NV_Sensor_PositionY : 29|11@1+ (0.001,-1) [-1.000|1.046] "Unit_Meter"  Vector__XXX
 SG_ NV_Sensor_PositionX : 40|12@1+ (0.001,1) [1.000|5.094] "Unit_Meter"  Vector__XXX
 SG_ NV_Sensor_PositionZ : 52|11@1+ (0.001,0) [0.000|2.046] "Unit_Meter"  Vector__XXX
 SG_ NV_NichtVerfuegbar : 63|1@1+ (1.0,0.0) [0.0|1] ""  Vector__XXX

BO_ 1635 NVEM_02: 8 Gateway
 SG_ BEM_02_Abschaltstufen : 0|3@1+ (1.0,0.0) [0.0|7] ""  BCM1,Klima_MSB,Lift_VA,VAS_L,VAS_R
 SG_ BEM_STH_Zielzeit : 3|4@1+ (5,0) [0|60] "Unit_Minut"  BCM1,Klima_MSB
 SG_ BEM_MMI_Vorwarnung : 7|1@1+ (1.0,0.0) [0.0|1] ""  Vector__XXX
 SG_ NVEM_Anf_SD_schalten : 15|1@1+ (1.0,0.0) [0.0|1] ""  BCM1
 SG_ BEM_Generatordiagnose : 16|2@1+ (1.0,0.0) [0.0|3] ""  Vector__XXX
 SG_ BEM_Red_Innengeblaese : 18|2@1+ (1.0,0.0) [0.0|3] ""  BCM1,Klima_MSB
 SG_ BEM_STH_Einschaltverbot : 20|1@1+ (1.0,0.0) [0.0|1] ""  BCM1,Klima_MSB
 SG_ BEM_HL_Regelung_Status : 21|3@1+ (1.0,0.0) [0.0|7] ""  BCM1,Klima_MSB,Lift_VA
 SG_ BEM_Ladezustand : 24|4@1+ (10,0) [0|100] "Unit_PerCent"  Vector__XXX
 SG_ BEM_Batteriediagnose : 28|3@1+ (1.0,0.0) [0.0|7] ""  Vector__XXX
 SG_ MIB_Stromsparmodus : 31|1@1+ (1.0,0.0) [0.0|1] ""  Vector__XXX
 SG_ BEM_REK_aktiv : 37|1@1+ (1.0,0.0) [0.0|1] ""  Vector__XXX
 SG_ NVEM_Last_Anf : 38|2@1+ (1.0,0.0) [0.0|3] ""  Vector__XXX
 SG_ BEM_UBDM : 40|8@1+ (0.05,5) [5.05|17.70] "Unit_Volt"  Klima_MSB
 SG_ BEM_UGenSoll : 48|6@1+ (0.1,10.6) [10.6|16.0] "Unit_Volt"  Vector__XXX
 SG_ BEM_Anf_KL15_schalten : 54|2@1+ (1.0,0.0) [0.0|3] ""  Vector__XXX
 SG_ NVEM_Batterie_Service : 56|2@1+ (1.0,0.0) [0.0|3] ""  Vector__XXX
 SG_ NVEM_Freigabe_OnlineUpdate : 58|1@1+ (1.0,0.0) [0.0|1] ""  Vector__XXX
 SG_ NVEM_Freigabe_ORU4 : 59|2@1+ (1.0,0.0) [0.0|3] ""  Vector__XXX

BO_ 2527679508 NVEM_06: 8 Gateway
 SG_ NVEM_06_CRC : 0|8@1+ (1,0) [0|255] ""  Vector__XXX
 SG_ NVEM_06_BZ : 8|4@1+ (1,0) [0|15] ""  Vector__XXX
 SG_ NVEM_Max_Rampenzeit : 12|4@1+ (1.0,0.0) [0.0|15] ""  Vector__XXX
 SG_ NVEM_Min_Spannung : 16|7@1+ (0.05,10.6) [10.60|16.00] "Unit_Volt"  Vector__XXX
 SG_ NVEM_Min_Spannung_Start : 23|6@1+ (0.1,7) [7.0|13.1] "Unit_Volt"  Vector__XXX
 SG_ NVEM_Max_Spannung : 29|7@1+ (0.05,10.6) [10.60|16.00] "Unit_Volt"  Vector__XXX
 SG_ NVEM_Energie_Klima_Vorgabe : 40|8@1+ (10,0) [0|2530] "Unit_WattHour"  BCM1,Klima_MSB
 SG_ NVEM_MV_DC_uMinLV : 48|7@1+ (0.1,3.5) [3.5|16.0] "Unit_Volt"  Vector__XXX
 SG_ NVEM_MV_DC_uSollLV : 55|7@1+ (0.05,10.6) [10.60|16.00] "Unit_Volt"  Vector__XXX
 SG_ NVEM_Bordnetzdiagnose : 62|2@1+ (1.0,0.0) [0.0|3] ""  Vector__XXX

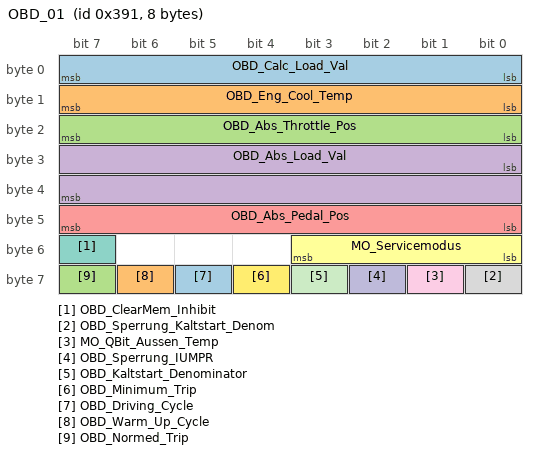
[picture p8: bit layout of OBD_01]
BO_ 913 OBD_01: 8 Gateway
 SG_ OBD_Calc_Load_Val : 0|8@1+ (0.39215686274509803,0) [0E-17|99.99999999999999765] "Unit_PerCent"  Vector__XXX
 SG_ OBD_Eng_Cool_Temp : 8|8@1+ (1,-40) [-40|215] "Unit_DegreCelsi"  Vector__XXX
 SG_ OBD_Abs_Throttle_Pos : 16|8@1+ (0.39215686274509803,0) [0E-17|99.99999999999999765] "Unit_PerCent"  Vector__XXX
 SG_ OBD_Abs_Load_Val : 24|16@1+ (0.39215686274509803,0) [0E-17|25699.99999999999939605] "Unit_PerCent"  Vector__XXX
 SG_ OBD_Abs_Pedal_Pos : 40|8@1+ (0.39215686274509803,0) [0E-17|99.99999999999999765] "Unit_PerCent"  Vector__XXX
 SG_ MO_Servicemodus : 48|4@1+ (1.0,0.0) [0.0|15] ""  Vector__XXX
 SG_ OBD_ClearMem_Inhibit : 55|1@1+ (1.0,0.0) [0.0|1] ""  Vector__XXX
 SG_ OBD_Sperrung_Kaltstart_Denom : 56|1@1+ (1.0,0.0) [0.0|1] ""  Vector__XXX
 SG_ MO_QBit_Aussen_Temp : 57|1@1+ (1.0,0.0) [0.0|1] ""  Vector__XXX
 SG_ OBD_Sperrung_IUMPR : 58|1@1+ (1.0,0.0) [0.0|1] ""  Vector__XXX
 SG_ OBD_Kaltstart_Denominator : 59|1@1+ (1.0,0.0) [0.0|1] ""  Vector__XXX
 SG_ OBD_Minimum_Trip : 60|1@1+ (1.0,0.0) [0.0|1] ""  Vector__XXX
 SG_ OBD_Driving_Cycle : 61|1@1+ (1.0,0.0) [0.0|1] ""  Vector__XXX
 SG_ OBD_Warm_Up_Cycle : 62|1@1+ (1.0,0.0) [0.0|1] ""  Lift_VA
 SG_ OBD_Normed_Trip : 63|1@1+ (1.0,0.0) [0.0|1] ""  Vector__XXX

BO_ 2549875214 OBDC_BCM1_Req: 8 Gateway
 SG_ OBDC_BCM1_Req_Data : 0|64@1+ (1.0,0.0) [0.0|18446744073709551615] ""  BCM1

BO_ 2550006286 OBDC_BCM1_Resp: 8 BCM1
 SG_ OBDC_BCM1_Resp_Data : 0|64@1+ (1.0,0.0) [0.0|18446744073709551615] ""  Gateway,Gateway_PAG

BO_ 2549875352 OBDC_DMD_L_Req: 8 Gateway
 SG_ OBDC_DMD_L_Req_Data : 0|64@1+ (1.0,0.0) [0.0|18446744073709551615] ""  BCM1

BO_ 2550006424 OBDC_DMD_L_Resp: 8 BCM1
 SG_ OBDC_DMD_L_Resp_Data : 0|64@1+ (1.0,0.0) [0.0|18446744073709551615] ""  Gateway

BO_ 2549875353 OBDC_DMD_R_Req: 8 Gateway
 SG_ OBDC_DMD_R_Req_Data : 0|64@1+ (1.0,0.0) [0.0|18446744073709551615] ""  BCM1

BO_ 2550006425 OBDC_DMD_R_Resp: 8 BCM1
 SG_ OBDC_DMD_R_Resp_Data : 0|64@1+ (1.0,0.0) [0.0|18446744073709551615] ""  Gateway

BO_ 2549940736 OBDC_Funktionaler_Req_All: 8 Gateway
 SG_ OBDC_Funktionaler_Req_All_Data : 0|64@1+ (1.0,0.0) [0.0|18446744073709551615] ""  BCM1,Klima_MSB,Lift_VA,VAS_L,VAS_R

BO_ 2549875270 OBDC_Klima_Req: 8 Gateway
 SG_ OBDC_Klima_Req_Data : 0|64@1+ (1.0,0.0) [0.0|18446744073709551615] ""  Klima_MSB

BO_ 2550006342 OBDC_Klima_Resp: 8 Klima_MSB
 SG_ OBDC_Klima_Resp_Data : 0|64@1+ (1.0,0.0) [0.0|18446744073709551615] ""  Gateway,Gateway_PAG

BO_ 2549875330 OBDC_LCM_L_Req: 8 Gateway
 SG_ OBDC_LCM_L_Req_Data : 0|64@1+ (1.0,0.0) [0.0|18446744073709551615] ""  BCM1

BO_ 2550006402 OBDC_LCM_L_Resp: 8 BCM1
 SG_ OBDC_LCM_L_Resp_Data : 0|64@1+ (1.0,0.0) [0.0|18446744073709551615] ""  Gateway,Gateway_PAG

BO_ 2549875331 OBDC_LCM_R_Req: 8 Gateway
 SG_ OBDC_LCM_R_Req_Data : 0|64@1+ (1.0,0.0) [0.0|18446744073709551615] ""  BCM1

BO_ 2550006403 OBDC_LCM_R_Resp: 8 BCM1
 SG_ OBDC_LCM_R_Resp_Data : 0|64@1+ (1.0,0.0) [0.0|18446744073709551615] ""  Gateway,Gateway_PAG

BO_TX_BU_ 1648 :Gateway,Gateway_PAG;
BO_TX_BU_ 289 :Gateway,Gateway_PAG;
BO_TX_BU_ 1423 :Gateway,Gateway_PAG;
BO_TX_BU_ 967 :Gateway,Gateway_PAG;
BO_TX_BU_ 340 :Gateway,Gateway_PAG;
BO_TX_BU_ 283 :Gateway,Gateway_PAG;
BO_TX_BU_ 1601 :Gateway,Gateway_PAG;
BO_TX_BU_ 394 :Gateway,Gateway_PAG;
BO_TX_BU_ 1156 :Gateway,Gateway_PAG;
BO_TX_BU_ 1157 :Gateway,Gateway_PAG;
BO_TX_BU_ 2527679512 :Gateway,Gateway_PAG;
BO_TX_BU_ 1158 :Gateway,Gateway_PAG;
BO_TX_BU_ 2589283496 :Gateway,Gateway_PAG;
BO_TX_BU_ 2527679647 :Gateway,Gateway_PAG;
BO_TX_BU_ 1696 :Gateway,Gateway_PAG;
BO_TX_BU_ 2600468496 :Gateway,Gateway_PAG;
BO_TX_BU_ 1377 :Gateway,Gateway_PAG;
BO_TX_BU_ 1635 :Gateway,Gateway_PAG;
BO_TX_BU_ 2527679508 :Gateway,Gateway_PAG;
BO_TX_BU_ 913 :Gateway,Gateway_PAG;
BO_TX_BU_ 2549875214 :Gateway,Gateway_PAG;
BO_TX_BU_ 2549940736 :Gateway,Gateway_PAG;
BO_TX_BU_ 2549875270 :Gateway,Gateway_PAG;
BO_TX_BU_ 2549875330 :Gateway,Gateway_PAG;
BO_TX_BU_ 2549875331 :Gateway,Gateway_PAG;
CM_ BO_ 1648 "Kombischnittstelle";
CM_ BO_ 1423 "CAN-Botschaft";
CM_ BO_ 967 "MQB - vorher Motor_06 / Umbenennung wg. ID-Wechsel";
CM_ BO_ 1601 "ab MQB mit CRC-8";
CM_ BO_ 1696 "MLBevo ohne KD-Bit";
CM_ BO_ 1635 "DLC=8 ab D4 gültig";
CM_ BO_ 2549940736 "VDC funktionaler Request auf CANHS";

CM_ SG_ 1648 MO1_Freigabe_Info_WFS "WFS-Freigabeinformation";
CM_ SG_ 1648 MO1_Freigabe_Verfallsinfo_WFS "WFS-Freigabeverfallsinformation";
CM_ SG_ 1648 MO1_Sperr_Info_WFS "WFS-Sperrinformation";
CM_ SG_ 1648 MO_Abstellzeit "Abstelldauer nach letztem KL15 aus

Hinweis: 
Ehemaliger Fehlerwert 0xFF wird senderseitig nicht unterstützt. 
Diesen Wert aus Kompatibilitätsgründen nicht neu belegen!";
CM_ SG_ 1648 MO_Abstellzeit_Status "Statusinformation zur Abstellzeit
0: Die dem Status zugeordnete Variable konnte noch nicht berechnet werden. 
1: Die dem Status zugehörige Variable wurde korrekt berechnet. 
2: Der Wert der zugehörigen Variablen ist nur ein Minimalwert. 
3: Der Wert d";
CM_ SG_ 1648 MO_ANC_Kennfeld_Anf "Anforderung ANC Kennfeldumschaltung";
CM_ SG_ 1648 MO_Anzahl_Abgesch_Zyl "Gibt die Anzahl der abgeschalteten Zylinder an. In Übergangszuständen wird der Zielbetriebszustand angezeigt.";
CM_ SG_ 1648 MO_Bremslicht_Reku "Bremslicht (ggf. bei Rekuperation durch E-Motor) wird angesteuert";
CM_ SG_ 1648 MO_Drehzahl_Warnung "Warnhinweis zum Kombi im Fall einer fehlerbehafteten Drehzahlbegrenzung";
CM_ SG_ 1648 MO_EPCL "Die Anforderung der EPC-Lampe vom MSG ans Kombi soll durch das Bus-Signal MO_EPCL gemäß folgender Logik erfolgen:
MO_EPCL = 0 dez -> EPC Lampe aus, kein Text
MO_EPCL = 1 dez -> gelbe EPC-Symbolik, Text „Antrieb: Störung! Bitte Service aufsuchen“
MO_EPC";
CM_ SG_ 1648 MO_Ethanol_BS_Texte "Ethanol Brennstoff-Texte im Kombi

0 = kein Text
1 = E85 Warm_Up
2 = FlexFuel Warnung 3.Stufe (Too cold for ethanol)
3 = Warmfahrempfehlung MQB / FlexFuel Warnung 1.Stufe (Refuel with gasoline)
4 = FlexFuel Warnung 2. Stufe (Refuel with gasoline)
5";
CM_ SG_ 1648 MO_Fahrzeugtyp "Unterscheidet die Fahrzeugtypen bzgl. der Antriebsart";
CM_ SG_ 1648 MO_Fehler_Zylabsch "Fehlerstatus der Funktion Zylinderabschaltung ";
CM_ SG_ 1648 MO_Hybrid_StartStopp_LED "Ansteuerung der Funktions-LED der Hybrid Taste bzw. Start/Stop Deaktivierungstaste.
Der Start/Stopp-Master (derzeit im MSG) (oder ein künftiger Hybrid-Master) soll die Ansteuerung senden.";
CM_ SG_ 1648 MO_max_Ladedruck "maximal möglicher Ladedruck (zur Anpassung des Anzeigebereichs bei absoluter Ladedruckanzeige)";
CM_ SG_ 1648 MO_NMAX_Schaltanzeige "Maximaldrehzahl für Schaltanzeige";
CM_ SG_ 1648 MO_obere_Drehzahlgrenze "obere Drehzahlgrenze des Motors";
CM_ SG_ 1648 MO_StartStopp_PopUp "Das Signal zeigt an, ob der StSt-Status mittels Deaktivierungstaster geändert wurde. Ein Wechsel auf die Werte 01 oder 10 löst im Kombi ein entsprechendes PopUp aus. Bei einem Statuswechsel durch andere Signalquellen (z.B. Charisma, fehlerbedingte Abschal";
CM_ SG_ 1648 MO_Zylabsch_Texte "Zylinderabschaltung mode in Kombi, fuer Zylinderabschaltung";
CM_ SG_ 1648 MO_Zylabsch_Texte_02 "ZAS-Anzeige für den Fahrer im Kombi
0: kein ZAS (generell keinerlei ZAS-Anzeigen)  (Init für nicht ZAS-Motor)
1: ZAS im Vollmotorbetrieb  (Init für ZAS-Motor)
2: ZAS im Abschaltbetrieb: 1 Zyl aktiv
3: ZAS im Abschaltbetrieb: 2 Zyl aktiv
4: ZAS im Abs";

CM_ SG_ 289 MO_Entkopplung_Sollschlupf "MSG fordert von GSG an, das Anfahrelement (Fahr-/Wandlerkupplung) zu entkoppeln; das GSG soll die gesendete Drehzahl als Schlupf einstellen und ggf. die Regler-Parameter umschalten, damit Rucke aus dem Antrieb nicht im Fahrzeug spürbar werden; nutzbar z.B";
CM_ SG_ 289 MO_Fahrpedalgradient "Das Motorsteuergerät besitzt 2 analoge Fahrpedalsignale. Das Signal des ersten Kanals wird alle 4ms abgetastet. Um Bitschwankungen des A/D-Wandler herauszufiltern wird das Signal entjittert. Anschließend wird der Gradient berechnet. Entsprechend der Zyklu";
CM_ SG_ 289 MO_Fahrpedalrohwert_01 "AUDI D4: Zykluszeit: 10ms (siehe Zykluszeit schnell/Cycletime Fast)

Stellung des Fahrpedales (Rohwert, ohne Überlagerung durch GRA-Eingriffe etc.)

Die Funktionen zur Berechung des Fahrpedalrohwerts laufen im 10ms Raster. Der Fahrpedalwert berechnet ";
CM_ SG_ 289 MO_Moment_im_Leerlauf "Fahrerwunschmoment ist minimal: keine Momentenanforderung durch Fahrpedal, ACC oder GRA+; (Das Signal ist unabhängig von Momentenerhöhungen durch Leerlaufregler oder MSR).

AUDI D4: Zykluszeit: 10ms (siehe Zykluszeit schnell/Cycletime Fast)

Achtung:";
CM_ SG_ 289 MO_QBit_Fahrpedalwerte_01 "AUDI D4: Zykluszeit: 10ms (siehe Zykluszeit schnell/Cycletime Fast)

QBit für beide Fahrpedalwerte des Motors (Fahrpedalrohsignal für ESP, EPB, ACC; Fahrpedalwert für Getriebe)

Achtung:
Reduktion der Zykluszeit Motor_03 auf 10ms geplant.
Projektabh";
CM_ SG_ 289 MO_rel_Saugrohrdruck "Der Wert gibt an, um wieviel mbar der Saugrohrdruck unterhalb des Umgebungsdrucks liegt. Überdruck im Saugrohr wird nicht ausgegeben.
0: Saugrohrdruck=Umgebungsdruck";
CM_ SG_ 289 MO_rel_Saugrohrdruck_gem_err "0: mind. eine Modellrechnung wird zur Berechnung des relativen Saugdrucks herangezogen
1: Relativer Saugrohrdruck wird ausschließlich über Messgrößen bestimmt";
CM_ SG_ 289 MO_Schubabschaltung "ESP plausibilisiert Unterdrucksensor nur bei aktiver Schubabschaltung

MLBevo:
Signal wird nur in MLBevo Projekten mit PDKII Getriebe bedient. In allen anderen MLBevo Projekten wird das Signal mit '0' bedient
PDKII berücksichtigt Verzugszeiten, die in";
CM_ SG_ 289 MO_Sig_Fahrpedalgradient "Kennzeichnet das Vorzeichen des Signal 'Fahrpedalgradient'. Die Ausgabe erfolgt nur parallel statisch mit gesendetem Signal: 'Steuerungsbit Fahrpedalgradient' ";
CM_ SG_ 289 MO_Solldrehz_Leerlauf "Leerlaufsolldrehzahl, die im Motor eingestellt ist (Bei Parallelhybrid im E-Fahr-Betrieb Leerlaufsolldrehzahl der E-Maschine). Der Motor paßt aufgrund der Anforderung von anderen Steuergeräten seine Leerlaufsolldrehzahl an, bspw. Kat-Heizen, Anforderung v";
CM_ SG_ 289 MO_StartStopp_StoppVorbereitung "Zeigt allen aktiven Start-/Stoppteilnehmern einen möglichen Motorstopp im Anhaltevorgang an (Empfänger notwendige Vorbereitungen treffen)
Es liegen keine Vetos vor.";
CM_ SG_ 289 MO_temporaere_Fahrerabwesenheit "Das Signal dient zur Signalisierung einer temporären Abwesenheit des Fahrers. In dieser Zeit ist es ihm möglich, sich durch gewisse ¿ im Verlassenskonzept definierte ¿ Fahreraktionen im aktuellen Fahrzyklus zurückzumelden.
Das Signal wird gesetzt, sobald";
CM_ SG_ 289 Motor_20_BZ "Botschaft asynchron geroutet. Zählerwert kann springen.";
CM_ SG_ 289 Motor_20_CRC "Für MLB:
'Berechnung siehe Lastenheft 'Kommunikationsabsicherung für FlexRay und CAN''

Ab MQB und MLBevo:
'Berechnung siehe Lastenheft 'End-to-End Kommunikationsabsicherung'

Endwerte siehe Begleitdokument 'S-PDU Kennungsfolgen'";
CM_ SG_ 289 TSK_a_Soll_gradientenbegrenzt "TSK Sollbeschleunigung für Fahrerassistenzsysteme mit aktiver Längsführung (GRA, ACC, IPA...). Der Wert stellt den ruckbegrenzten Sollwert der TSK-Regelung dar und ist Basis der TSK-Antriebs- und Bremsmomentenvorsteuerung.";

CM_ SG_ 1423 FSA_Fehlerpfade_Initialisieren "Aktivierung der Fehlerpfad-Initialisierung  beim FSP Löschen ueber Mode04";
CM_ SG_ 1423 MO_FSA_Sensorheizung "Aktivierung Sensorheizung FSA";
CM_ SG_ 1423 MO_Getriebe_Oelalterung "Prozentualer Alterungswert Getriebeöl";
CM_ SG_ 1423 MO_ITM_Status "Statusinformationen an TME-Steuergerät bzgl. Thermomanagement";
CM_ SG_ 1423 MO_KJS_LLK_Pos_Summe "Aerodynamisch wirksamer Gesamtöffnungswinkel aller Kühlerlüfter- und LLK-Jalousiesteller.

Pos_Frontendverschl_ungenau = 15 zeigt eine Fehlfunktion bzw. unbekannte Position einer oder mehrere Jalousiesteller an.";
CM_ SG_ 1423 MO_Kuehlmittel_Temp_Rohwert "Rohwert Kuehlmitteltemperatur
Das Signal wird derzeit von Diesel-Projekten nicht bedient.";
CM_ SG_ 1423 MO_MMTR_Status "Status des Antriebs zur Funktion Make me track ready";
CM_ SG_ 1423 MO_Oel_Temp_Radsatz "Öltemperatur in PDK Radsatz ";
CM_ SG_ 1423 MO_SABody_PosLe "Öffnungswinkel der Linke Front Diffusor 
(0%= geschlossen, 100% =volle Kühlung)";
CM_ SG_ 1423 MO_SABody_PosRi "Öffnungswinkel der Rechte Front Diffusor 
(0%= geschlossen, 100% =volle Kühlung)";
CM_ SG_ 1423 MO_Tankdruck "Tank Über-/Unterdruck wird für Ansteuerintensität der Treibstoffpumpe der Standheizung benötigt.";

CM_ SG_ 967 MO_E_Mode "Anforderung der E-Mode Statusanzeige";
CM_ SG_ 967 MO_E_Texte "Anforderung von Hinweistexten des E-Systems separat für HEV/BEV bzw. erweiterbar für PHEV";
CM_ SG_ 967 MO_E_Warnungen "Anforderung von Warnanzeigen des E-Systems separat für HEV/BEV bzw. erweiterbar für PHEV";
CM_ SG_ 967 MO_EFLEX_Lampe "Um ein Starten mit E100 zu ermöglichen, wird Kraftstoff ggf. vorgeheizt. Das Signal dient der Anzeige des Heizungsstatus.

Heizung aus -> Lampe aus
Heizung ein -> Lampe ein
Heizung ein und Startversuch -> Lampe blinkend
Heizung nicht möglich -> Lampe";
CM_ SG_ 967 MO_Heissleuchte "Ansteuerung der Kühlwassertemperatur-Heißleuchte (Sensor nur noch am Motorsteuergerät): Temperaturschaltschwellen mit Hysterese (bei VW D1/Colorado Kombi derzeit noch nicht genutzt).";
CM_ SG_ 967 MO_ITM_Warnung_Pumpe "Textanzeige: 'Motor sofort abstellen, geschaltete Wasserpumpe defekt / klemmt'";
CM_ SG_ 967 MO_KJS_nicht_bereit "Dieses Signal zeigen einen Fehler der Kühlerjalousie mit unbekannter Stellung der Lamellen. ";
CM_ SG_ 967 MO_Kuehlerluefter_1 "Ansteuertastverhaeltnis (PWM) der Kuehlerluefterendstufe 1";
CM_ SG_ 967 MO_Kuehlerluefter_2 "Ansteuertastverhaeltnis (PWM) der Kuehlerluefterendstufe 2";
CM_ SG_ 967 MO_Kuehlerluefter_MUX "Multiplexer für das Signal 'MO_Kuehlerlüfter'";
CM_ SG_ 967 MO_OBD2_Lampe "OBD bzw. MIL-Lampe wird vom Motorsteuergerät angesteuert, die Information im Signal GE_OBD_Status wird vom Motorsteuergerät an das Kombi weitergereicht";
CM_ SG_ 967 MO_Oelwarnung_max "Ölstandswarnung mit der Aufforderung zum Ölwechsel.
Hintergrund: Bei Kraftstoffeintrag (B20) ins Öl verbleibt der RME-Anteil irreversibel im Öl.";
CM_ SG_ 967 MO_Partikel_Lampe "Partikelfilter-Lampe wird eingeschaltet";
CM_ SG_ 967 MO_RedFahrleistung_Lampe "Ansteuerung der Turtle-Mode Lampe für E-Traktion Fahrzeuge";
CM_ SG_ 967 MO_Systemlampe "EGas Systemlampe (EPC) oder Vorglühlampe im Kombi, Kombi steuert immer gleiche
LED an, nur über Ziffernblatt wird die EPC von der Vorglühlampe differenziert";
CM_ SG_ 967 MO_Tankdeckel_Lampe "Ansteuerung Tankdeckel-Warnlampe Kombiinstrument (nur Ottomotoren) z.Zt. Vorhalt VW";
CM_ SG_ 967 MO_Text_Motorstart "Anzeigetexte für Start/Stopp und Motor-Start
0xB Fehler_Kupplungsschalter nur für PAG-MLB";
CM_ SG_ 967 MO_Text_Partikelfil_Reg "Über dieses Bit im Kombi wird ein Klartextanzeige erzeugt werden: 'Partikelfilter benötigt Regeneration'.
";
CM_ SG_ 967 MO_Text_Tankdeckelwarn "Textbit der Tankdeckelwarnung, z.Zt. Vorhalt VW";
CM_ SG_ 967 MO_Vorglueh_Lampe "Vorglühlampe im Kombi, Kombi steuert immer gleiche LED an. 
Mit Einführung des Einheits-Kombis sind getrennte Signalwege für Vorglühlampe und EPCL notwendig.";
CM_ SG_ 967 MO_Zustand_HWP "Rückmeldung des  Ansteuerzustand der Hauptwasserpumpe an das Klima-SG .
Der Zustand 'HWP fördert' wird übermittelt, wenn die Schaufeln der Hauptwasserpumpe frei drehen können und die Motordrehzahl und damit die Wasserpumpendrehzahl größer als Null ist. B";
CM_ SG_ 967 OLEV_Oelstand_nicht_vorhanden "Kein aktueller Ölstand vorhanden";
CM_ SG_ 967 OLEV_Systemstoerung "Systemstörung im Ölsystem";
CM_ SG_ 967 WIV_Anzeige_aktiv "Peilstabsanzeigefunktion aktiv";
CM_ SG_ 967 WIV_laufender_Motor "Messung bei laufendem Motor nicht möglich";
CM_ SG_ 967 WIV_nachfuellanzeige_ein "Steuert das Aufblenden der Nachfüllanzeige im Kombi, nach Klemme 15 ein und geöffneter Motorhaube";
CM_ SG_ 967 WIV_nicht_betriebswarm "Motor nicht betriebswarm, Messung ungenau";
CM_ SG_ 967 WIV_Oeldr_Warn_Motor "Löst im Kombiinstrument die rote Prio1-Öldruckwarnung (inkl. 3xBeep) aus.
nur MLB: die Warnauslösung erfolgt nur bei gleichzeitig gesetztem 'WIV_Enable_Oeldr_Motor'";
CM_ SG_ 967 WIV_Oeldyn_avl "Ölstand aus dynamischer Messung vorhanden";
CM_ SG_ 967 WIV_Oelmenge "Ölmenge zwischen Min und Max";
CM_ SG_ 967 WIV_Oelmin_Warn "Signal gibt an wenn der Ölstand die Min-Schwelle unterschritten hat";
CM_ SG_ 967 WIV_Oelstand "8 Segmente zur Balkenanzeige des Ölstands";
CM_ SG_ 967 WIV_Oelstand_nicht_vorhanden "Kein aktueller Ölstand vorhanden";
CM_ SG_ 967 WIV_Oelsystem_aktiv "Gesamtölsystem aktiv (entspricht Ölsensor verbaut) und das Ölstand-Untermenu im MMI aktiv";
CM_ SG_ 967 WIV_Schieflage "Fahrzeug steht nicht waagerecht, Messung ungenau";
CM_ SG_ 967 WIV_Sensorfehler "Ölstand/Öltemperatursensor (TOG) defekt";
CM_ SG_ 967 WIV_Ueberfuell_deaktiv "Unterdrückung der Warnung im Kombi die durch Signal WIV_Ueberfuel_Warn ausgelöst wird";
CM_ SG_ 967 WIV_Ueberfuell_Warn "Ölstand hat die Überfüllschwelle überschritten";
CM_ SG_ 967 WIV_Unterfuell_Warn "Ölstand hat die Unterfüllschwelle unterschritten";

CM_ SG_ 340 MO_Drehzahl_VM "Motordrehzahl des Verbrennungsmotors

für OBD freeze frame

Hinweis: 
Ehemaliger Fehlerwert 0xFFFF wird senderseitig nicht unterstützt. 
Diesen Wert aus Kompatibilitätsgründen nicht neu belegen!";
CM_ SG_ 340 MO_Fehlerstatus_Antrieb_FDR "Fehlerstatus Antrieb - FDR";
CM_ SG_ 340 MO_IstMoment_VKM "Ist-Moment des Verbrennungsmotors

einheitenloser Wert! MO_Faktor_Momente_02 in Motor_Code_01 berücksichtigen!";
CM_ SG_ 340 MO_Mom_Begr_Schalt "Einheitenloser Wert! Faktor in MO_Faktor_Momente (CAN V6.x) bzw. MO_Faktor_Momente_02 (CAN V7.x/8.x) in Motor_Code_01 beachten!

Bei aktueller Drehzahl kurzfristig (ca. 100..200 ms) für momentenerhöhende Getriebeeingriffe max. zur Verfügung stehendes Ge";
CM_ SG_ 340 MO_Mom_Begr_Schalt_Min "Bei aktueller Drehzahl im nächsten Task (im VKM Umsetzung zur nächsten möglichen Verbrennung) minmal stellbares Moment (Summe aus Verbrennungsmotor und E-Motor) aufgrund Momenten-Reduzierungs-Anforderung durch reduzierenden Getriebeeingriff.
Berücksichti";
CM_ SG_ 340 MO_Primaerachse_Anforderung "Das Signal dient der Steuerung der Primärachse. 

Anforderung zum Öffnen/Schließen der Getriebekupplungen und damit An-/Abkuppeln der Primärachse. 
Wird in MHEV-Projekten keine explizite Anforderung gesendet (Wert 0), ist die Freilaufsteuerung aus 'MO_";
CM_ SG_ 340 Motor_28_BZ "Botschaft asynchron geroutet. Zählerwert kann springen.";
CM_ SG_ 340 Motor_28_CRC "Für MLB:
'Berechnung siehe Lastenheft 'Kommunikationsabsicherung für FlexRay und CAN''

Ab MQB und MLBevo:
'Berechnung siehe Lastenheft 'End-to-End Kommunikationsabsicherung''

Endwerte siehe Begleitdokument 'S-PDU Kennungsfolgen'";

CM_ SG_ 283 MO_AIAD_MaxLeistung "Maximal zulässige Leistung, die das PDCC einzustellen hat.";
CM_ SG_ 283 MO_EBoost_verf_praed "Zeigt an, ob für eine im Projekt definierte Zeit (max. 10s) E-Boost in Höhe von EM1_maxPred_Moment verfügbar sein wird.

0 - Init_oder_nicht_verfügbar
1 - EBoost_kurzzeit_verfügbar (~3Sek.)
2 - EBoost_langzeit_verfügbar (~10Sek)";
CM_ SG_ 283 MO_eLaunch_verf "Zeigt an, ob aus Antriebssicht E-Launch verfügbar ist.";
CM_ SG_ 283 MO_Fahrbereitschaft "Das Signal MO_Fahrbereitschaft zeigt in mehreren Stufen an, ob der Motor in einem anfahrbereiten Zustand ist.";
CM_ SG_ 283 MO_Freilauf_Info "Freilauf Informationssignal vom Motorsteuergerät zum Getriebesteuergerät. Das Motorsteuergerät kann über dieses Signal den Freilauf freigeben, verhindern bzw. explizit anfordern.";
CM_ SG_ 283 MO_Freilauf_Status "Freilauf-Status-Signal vom Frailauf-Master an aktive Freilauf-Teilnehmer. In diesem Signal zeigt der Freilauf-Master an, welchen aktuellen Status die Freilauf-Betriebsstrategie hat.";
CM_ SG_ 283 MO_Heckspoiler_Anf "Anforderung den Heckspoiler zur Ladeluft- bzw. Motorraumkühlung auszufahren.";
CM_ SG_ 283 MO_Krit_Heckobjekt "Beschreibt die Kritikalität des hinter einem in der Spur fahrenden Fahrzeuges";
CM_ SG_ 283 MO_NGS_Gangpos "Gang- bzw. Neutralinformation des erweiterten Neutralgangsensors. Bedingt durch den eingeschränkten Erfassungssbereich des Sensors sind die Ganginformationen als eingelegt bzw. fast eingelegt/vorausgewählt zu interpretieren (nur Handschalter)";
CM_ SG_ 283 MO_Parken_WFS_Status "Gesammelte Rückmeldung des Limitierungsstatus aller EM in einem vom ZFAS angeforderten Parkvorgang.";
CM_ SG_ 283 MO_Positionierung_aktiv "Zeigt an, dass die Motorpositionierung mit Hilfe des Riemenstartergenerator momentan aktiv ist.";
CM_ SG_ 283 MO_Rennstart_verf "Zeigt an, ob aus Antriebssicht ein Rennstart verfügbar ist.";
CM_ SG_ 283 MO_Status_Katheizen "Status des Katheizen.

0 = Katheizen nicht aktiv
1 = Katheizen aktiv";
CM_ SG_ 283 MO_Status_MIN_Wunschdrehzahl "In 2.0 TFSI Motorprojekten EA888 Gen3 und EA888 EVO4 im MLBevo (AU536 und AU49x, in allen anderen Projekten ist das Signal nicht zu implementieren) wird das Bus Signal MO_MIN_Wunschdrehzahl verwendet, um durch eine damit angepasste Gangwahl des Getriebes ";

CM_ SG_ 1601 MO_Ansaugsystem "Art des Ansaugsystems des Verbrennungsmotors";
CM_ SG_ 1601 MO_Anzahl_Zyl "Zylinderzahl des Verbrennungsmotors";
CM_ SG_ 1601 MO_Anzeige_StSt_gueltig "Zeigt die Gültigkeit der neuen StSt-Anzeigesignale an, MO_Anzeige_StSt_Text und  MO_Anzeige_Symbol. Mo_Text_Motorstart 1..5 sind zu ignorieren.";
CM_ SG_ 1601 MO_Code "Motorcodierinformation Version 16 (Details siehe Anhang)";
CM_ SG_ 1601 MO_DPF_verbaut "Verbauinformation Diesel-Partikel-Filter
";
CM_ SG_ 1601 MO_Faktor_Momente_02 "Dieses Signal schaltet den Wertebereich aller Momente vom Motor, Getriebe, TSK, Bremse ... um! Die Momente besitzen somit einen variablen Wertebereich, weil sich durch den Faktor die Momente sowohl in Auflösung als auch Maximalwerten ändert.

0x0 nicht ";
CM_ SG_ 1601 MO_Getriebe_Code "Getriebecodierung des Motors";
CM_ SG_ 1601 MO_Hubraum "Hubraum des Verbrennungsmotors";
CM_ SG_ 1601 MO_Hybridfahrzeug "Anhand dieses Signals plausibilisiert die Lenkhilfe das Bit Fahrbereitschaft.

Im Projekt Cayenne PHEV (und ggf. auch VW526 PHEV) ist aus Gründen der Abwärtskompatibilität der Wert '2' zu senden.";
CM_ SG_ 1601 MO_Kraftstoffart "Primärkraftstoff zum Antrieb des Fahrzeugs";
CM_ SG_ 1601 MO_Leistung "Nennleistung des Verbrennungsmotors

Im reinen E-Fahrzeug (BEV): Ausgabe der elektrischen Systemleistung";
CM_ SG_ 1601 MO_OBD_Typ "Abgastyp OBD
Hinweis: In Fahrzeugen mit dem Zielmarkt China und einer Zertifizierung ab China 6 muss auf dem Signal 'MO_OBD_Typ' der Wert 'US_OBD' gesendet werden.";
CM_ SG_ 1601 MO_StartStopp_Codiert "Funktion StartStopp im aktuellen Klemmenzyklus verbaut";
CM_ SG_ 1601 Motor_Code_01_CRC "Für MLB:
'Berechnung siehe Lastenheft 'Kommunikationsabsicherung für FlexRay und CAN''

Ab MQB und MLBevo:
'Berechnung siehe Lastenheft 'End-to-End Kommunikationsabsicherung''

Endwerte siehe Begleitdokument 'S-PDU Kennungsfolgen'";
CM_ SG_ 1601 TSK_Codierung "Information über den plausibilisierten Codierungszustand des Triebstrangskoordinators auf ACC oder GRA.";

CM_ SG_ 394 MO_Ablaufstatus "aktueller Status bezüglich der Ausführung des Sollzustand

detaillierte Beschreibung der einzelnen Übergänge ist in der aktuellsten Version des Lastenhefts 'Funktionslastenheft Betriebsartenkoordination bei elektrifizierten Fahrzeugen_Vxx' zu entnehmen";
CM_ SG_ 394 MO_Ablaufstrg_Betriebszustand "Istzustand Betriebsbereitschaft

1 = Betriebsbereitschaft bedeutet: Alle Komponenten sind betriebsbereit. Fahrzeug kann kein Vortriebsmoment erzeugen.

2 = Fahrbetrieb bedeutet: Fahrzeug kann Vortriebsmoment erzeugen.";
CM_ SG_ 394 MO_Ablaufstrg_Kraftschluss2_Ist "Istzustand des Kraftschlusses der Sekundärachse in der Hybridablaufsteuerung (z.B. el. Hinterachse im B9 eQuattro).
Dieses Signal entspricht nicht einem physikalischen Zustand, sondern den Istzustand der Ablaufsteuerung.

Das Signal darf nur ausgwertet";
CM_ SG_ 394 MO_Ablaufstrg_Kraftschluss2_Ziel "Zielstatus des Kraftschlusses der Sekundärachse in der Hybridablaufsteuerung (z.B. el. Hinterachse im B9 eQuattro).
Mit dem Bit soll das Getriebe Kraftschluss herstellen oder den Kraftschluss unterbrechen.

Das Signal darf nur ausgwertet werden, wenn '";
CM_ SG_ 394 MO_Ablaufstrg_Kraftschluss_Ist "Istzustand des Kraftschlusses in der Hybridablaufsteuerung.
Dieses Signal entspricht nicht einem physikalischen Zustand, sondern den Istzustand der Ablaufsteuerung.

Das Signal darf nur ausgwertet werden, wenn 'MO_Ablaufstrg_Betriebszustand' eine Betri";
CM_ SG_ 394 MO_Ablaufstrg_Kraftschluss_Ziel "Zielstatus des Kraftschlusses in der Hybridablaufsteuerung.
Mit dem Bit soll das Getriebe Kraftschluss herstellen oder den Kraftschluss unterbrechen.

Das Signal darf nur ausgwertet werden, wenn 'MO_Ablaufstrg_Betriebszustand' eine Betriebsbereitschaft";
CM_ SG_ 394 MO_Ablaufstrg_Zustand_K0_Ist "Iststatus der K0 Kupplung in der Hybridablaufsteuerung.
Dieses Signal entspricht nicht einem physikalischen Zustand, sondern den Istzustand der Ablaufsteuerung.

Das Signal darf nur ausgwertet werden, wenn 'MO_Ablaufstrg_Betriebszustand' eine Betriebsb";
CM_ SG_ 394 MO_Ablaufstrg_Zustand_K0_Ziel "Zielstatus der K0 Kupplung in der Hybridablaufsteuerung
K0 Steuerung im Motorsteuergerät:
- Infobit an das Getriebe, dass K0 jetzt geschlossen wird
K0 Steuerung durch anderes Steuergerät:
- Bit um dem anderen SG mitzuteilen, dass dieses die K0 schlies";
CM_ SG_ 394 MO_Ablaufstrg_Zustand_VKM_Ist "Istzustand VKM
Dieses Signal entspricht nicht einem physikalischen Zustand, sondern den Istzustand der Ablaufsteuerung.

Das Signal darf nur ausgewertet werden, wenn 'MO_Ablaufstrg_Betriebszustand' eine Betriebsbereitschaft signalisiert.";
CM_ SG_ 394 MO_Ablaufstrg_Zustand_VKM_Ziel "Zielzustand VKM
Dieses Signal entspricht nicht einem physikalischen Zustand, sondern den Zielzustand der Ablaufsteuerung.

Das Signal darf nur ausgewertet werden, wenn 'MO_Ablaufstrg_Betriebszustand' eine Betriebsbereitschaft signalisiert.";
CM_ SG_ 394 MO_Abstellposition_02 "Winkelabstand (in °KW) des sog. Zielzylinders von seinem ZOT (bspw. nötig um Startmoment bei Schleppstart zu berechnen)

255 = Abstellposition kann nicht genau bestimmt werden (bspw. Rückdrehen des Motors)";
CM_ SG_ 394 MO_Auth_Aufforderung_WFS "WFS-Anforderung für Hybridumfänge";
CM_ SG_ 394 MO_HYB_Adaption_aktiv "Motor fordert Sondermaßnahmen vom Getriebe PDK2 (gültig nur für Hybridprojekte)
Das Signal wird im PDKII dazu verwendet, die Fahrkupplungen bei einem Momentenadaptionswunsch der K0-Trennkupplung nicht zu befüllen";
CM_ SG_ 394 MO_HYB_E_Faktor "Signed Nibble, verwendet vom GSG zur Interpolation zwischen VMKennfeld und dem Rekuperations-Grenzkennfeld (negative Werte des E-Faktors) bzw. dem Boost-Grenzkennfeld (positive Werte des E-Faktors).
0000 = VM-Kennfeld (keine Interpolation)
0001..0111 = ";
CM_ SG_ 394 MO_HYB_EMode_Info "Hybrid-Mode der Motorsteuerung zur Beeinflussung der Schaltkennfelder im Getriebe. Nicht-Hybridfahrzeuge senden den Initwert.";
CM_ SG_ 394 MO_HYB_LowSpeedModus "MSG legt fest:
0 = klassisches Ausrollen/Anfahren mit N_mot >= N_Leerlauf_VM
1 = elektr. Ausrollen/Anfahren mit geschl. Triebstrang mit N_mot < N_Leerlauf_VM";
CM_ SG_ 394 MO_HYB_Stoppmodus "Hybridsteuerung zeigt an, auf welche Weise gestoppt werden soll.";
CM_ SG_ 394 MO_Mom_Freiheit_Sekundaerachse "Signalisiert die Momentenfreiheit der Sekundärachse und ist damit Voraussetzung für das Abkoppeln.";
CM_ SG_ 394 MO_Nachlaufzeit_Kuehlerluefter "Nachlaufzeit Kühlerlüfter MSG für Verwendung im TME SG";
CM_ SG_ 394 MO_Start_Art "Beschreibt Art des Starts näher 

Schlupfstart kann entweder Momentenvorhalt oder Impulsstart sein oder eine Kombination aus beidem.";
CM_ SG_ 394 MO_Start_Dynamik "Zeigt die Start-Variante bzw. Start-Dynamik eines VKM-Starts an";
CM_ SG_ 394 MO_Tankklappensteuerung "Ansteuerungsanforderung der Tankklappe";

CM_ SG_ 1156 ND_GDOP "geometric dilution of precision (Gesamtgenauigkeit, 3D und Zeit) 
";
CM_ SG_ 1156 ND_HDOP "horizontal dilution of precision (Horizontalrichtung, 2D)
";
CM_ SG_ 1156 ND_Heading "Fahrtrichtung";
CM_ SG_ 1156 ND_Init "Initialisierung";
CM_ SG_ 1156 ND_PDOP "positional dilution of precision (Positionsgenauigkeit, 3D) 
";
CM_ SG_ 1156 ND_TDOP "time dilution of precision (Zeitgenauigkeit)
";
CM_ SG_ 1156 ND_VDOP "vertical dilution of precision (Vertikalrichtung, 1D)
";

CM_ SG_ 1157 ND_SatInUse "Anzahl der zur Berechnung verwendeten Satelliten";
CM_ SG_ 1157 ND_SatInView "Anzahl der sichtbaren Satelliten";
CM_ SG_ 1157 ND_UTC "UTC-Zeit, verstrichene Sekunden seit 01.01.1970 00:00
0xFFFFFFFE = Init
0xFFFFFFFF = Fehler bei Berechnung der UTC-Time";
CM_ SG_ 1157 NP_Altitude "Hoehe ueber NN
0xFFF = Fehler bei der Berechnung der Höhe über NN";
CM_ SG_ 1157 POS_Guete_horizontal "Horizontale Genauigkeit der Position in der Botschaft NavPos_02_MapMatched (Signale
POS_LatDegree, POS_LongDegree)

Abhängig vom Signal
POS_Guete_horizontal_verfuegbar";
CM_ SG_ 1157 POS_Guete_horizontal_verfuegbar "Bei gesetztem Bit wird das Signal POS_Guete_horizontal befüllt und ist verfügbar.";

CM_ SG_ 2527679512 ND_Fuelstation_detected "Signal gibt an ob eine Tankstelle erkannt wurde";
CM_ SG_ 2527679512 ND_NrSameMeasure "GPS Anzahl der gleichen Messungen";
CM_ SG_ 2527679512 ND_RecDelay "Für MLBevo:
Zeit in ms zwischen zwei Interruptauslösungen des GPS Receiver.

Für MLBevoGen2:
Zeit in ms zwischen UTC-Sekunde und Messzeitpunkt des GPS Receiver.";
CM_ SG_ 2527679512 ND_RouteType "Routentyp.";
CM_ SG_ 2527679512 ND_SendDelay "Zeit in ms zwischen Interruptauslösung GPS Receiver (Beginn der Messung) und Senden auf den CAN Bus.";
CM_ SG_ 2527679512 ND_TimeOffset "Offset zu ND_TimeToDestination.";
CM_ SG_ 2527679512 ND_TimeToDestination "Zeit in min bis zum Erreichen des Ziel. Wird ausgegeben bei aktiver Routenführung oder bei gelernter Route (MPR).";
CM_ SG_ 2527679512 ND_Timezone_DaylightSavingOffset "Offest der Sommerzeit/Winterzeit
 
0 = kein Offset ; 
1 = 0,5h;  
2 = 1h";
CM_ SG_ 2527679512 ND_Timezone_Offset "Aktuelle Zeitzonen-Offset des Fahrzeugs.
Vorzeichen und Gültigkeit beachten";
CM_ SG_ 2527679512 ND_Timezone_SignBit "Vorzeichen des Zeitzonenoffsets.";
CM_ SG_ 2527679512 ND_Timezone_Validity "Gültigkeit des Zeitzonensignals.";
CM_ SG_ 2527679512 ND_Velocity "GPS Geschwindigkeit";

CM_ SG_ 1158 NP_LatDegree "Latitude (Nord-Süd Wert)";
CM_ SG_ 1158 NP_LatDirection "Hemisphäre Nord/Süd";
CM_ SG_ 1158 NP_LongDegree "Longitude (Ost-West Wert)";
CM_ SG_ 1158 NP_LongDirection "Hemisphäre Ost/West";
CM_ SG_ 1158 NP_Sat "Nummer der verwendeten Sateliten beim letzten Fix";

CM_ SG_ 2589283496 POS_Heading "Heading of current position
MUX(1)";
CM_ SG_ 2589283496 POS_Heading_Trust "Vertrauenswert Heading 
MUX(1) ";
CM_ SG_ 2589283496 POS_Last_GPS_Sync "Letztes bekannte GPS Sync in [s]
MUX(1)";
CM_ SG_ 2589283496 POS_LatDegree "latitude - position data of navigation
MUX(0)";
CM_ SG_ 2589283496 POS_LatDirection "latitude direction nav position
MUX(0)";
CM_ SG_ 2589283496 POS_LongDegree "long - position data of navigation
MUX(0)";
CM_ SG_ 2589283496 POS_LongDirection "longitude direction nav position
MUX(0)";
CM_ SG_ 2589283496 POS_MUX "Multiplex-Signal zum schalten des Signals der Positionen von der Navigation.
MUX(0/1)";
CM_ SG_ 2589283496 POS_ODD_EVEN "Synchronisation der MUX Pos Signale
MUX(0/1)";
CM_ SG_ 2589283496 POS_PosStati "Aktueller Status der Navgation:
MUX(0)
0   init
1   no nav available (ready_4_nav)
2   no map available (sd_removed, not_enabled)
3   nav booting
4   nav error
5   nav calibrating
6   nav no gps resync since 1h
7   nav offroad  parkgarage ramp of";
CM_ SG_ 2589283496 POS_UTC_REF "Zeitstempel der Nav
MUX(1)

UTC-Zeit, verstrichene Sekunden seit 01.01.1970 00:00
0xFFFFFFFE = Init
0xFFFFFFFF = Fehler bei Berechnung der UTC-Time

Signal wird nur bei aktiver Navigation-Funktion zyklisch gesendet.";

CM_ SG_ 2527679647 NFC_aktiv "NFC-Gerät erkannt";
CM_ SG_ 2527679647 NFC_ESM_aktivieren "Energiesparmodus aktivieren, da z.B. Batterie kritisch";
CM_ SG_ 2527679647 NFC_Front_Entr_Authorisiert "Erkennung / Authorisierung NFC-Handy Front";
CM_ SG_ 2527679647 NFC_Front_Verr_Authorisiert "Erkennung / Authorisierung NFC-Handy Front";
CM_ SG_ 2527679647 NFC_FT_Entriegelung_Authorisiert "Erkennung / Authorisierung NFC-Handy FT";
CM_ SG_ 2527679647 NFC_FT_Verriegelung_Authorisiert "Authorisierung Verriegelungssensor NFC-Handy FT";
CM_ SG_ 2527679647 NFC_HD_Entriegelung_Authorisiert "Erkennung / Authorisierung NFC-Handy Heck";
CM_ SG_ 2527679647 NFC_HD_Verriegelung_Authorisiert "Autorisierung der Schließanforderung über NFC-Handy";
CM_ SG_ 2527679647 NFC_Laden_unterbrechen "Kommunikation zur Phonebox, das Laden zu unterbrechen";
CM_ SG_ 2527679647 Stellgliedtest_NFC "Applikationssignal um NFC Stellgliedtest abzubilden";
CM_ SG_ 2527679647 ZV_auf_NFC "ZV Schliessstelle";
CM_ SG_ 2527679647 ZV_zu_NFC "ZV Schliessstelle";

CM_ SG_ 1696 NV_Akt_Status_MMI "Zustand des Nightvison Systems im MMI: Warnalgo & NV-Reiter Ein/Aus

";
CM_ SG_ 1696 NV_aktiv "Nightvision aktiviert (liefert Bild)";
CM_ SG_ 1696 NV_Akustik_deaktiviert_Icon "Ansteuerungssignal für das  Akustik-deaktiviert-Icon";
CM_ SG_ 1696 NV_Anf_Prefill "Anforderung an ESP, dass die Prefill-Funktion aktiviert werden soll.";
CM_ SG_ 1696 NV_AnforderungBildaufschaltung "Automatische Bildaufschaltung im Warnfall";
CM_ SG_ 1696 NV_FAS_Fkt_Status "Signal für FAS Profile-Master";
CM_ SG_ 1696 NV_FGM_deaktiviert_Icon "Ansteuerungssignal für das  Fussgängermarkierung-deaktiviert-Icon";
CM_ SG_ 1696 NV_Gong "Das Signal löst einen Gong des NightVision-Systems im Kombidisplay aus";
CM_ SG_ 1696 NV_HBA_Parameter "Anforderung an ESP, welcher HBA-Parametersatz verwendet werden soll. Die Festlegung der Empfindlichkeitsschwellen der verschiedenen Parametersätze erfolgt mit der Applikation des Gesamtsystems ESP/ACC bzw. des HBA.
Nur Audi B8: Umsetzung der Anforderung ";
CM_ SG_ 1696 NV_Hinweise "Das Signal dient dazu Hinweistexte in das NightVision Bild im Kombiinstrument einzublenden.Die Anzeigedauer der Hinweistexte ist Signalgesteuert. D.h., sie werden angezeigt bis das CAN-Signal s_NV_Texte seinen Wert ändert.";
CM_ SG_ 1696 NV_LED_Leiste "Ansteuerung_LED_Warnleiste";
CM_ SG_ 1696 NV_Markierungslicht_links "Das Signal steuert die Aktivierung des Markierungslicht links bei Fußgängerwarnung";
CM_ SG_ 1696 NV_Markierungslicht_rechts "Das Signal steuert die Aktivierung des Markierungslicht rechts bei Fußgängerwarnung";
CM_ SG_ 1696 NV_Piktogramm_aktiv "Signal sagt, dass das Piktogramm im NightVision-Reiter geändert werden soll";
CM_ SG_ 1696 NV_PreSense_Modus_System "Signal zur Realisierung der BAP-Kommunikation für PreSense";
CM_ SG_ 1696 NV_PreSense_Modus_Warnung "Signal zur Realisierung der BAP-Kommunikation für PreSense";
CM_ SG_ 1696 NV_PreSense_Status "Signal zur Realisierung der BAP-Kommunikation für PreSense";
CM_ SG_ 1696 NV_Symbol "Wenn das NV-System einen Fußgänger findet, fordert es mit dem Signal das HUD auf, ein Symbol zu zeigen";
CM_ SG_ 1696 NV_Symbol_Tierwarnung "Signal zur Anforderung einer Symbolanzeige für Tierwarnung.";
CM_ SG_ 1696 NV_Texte "Angeforderte Textmeldung";

CM_ SG_ 2600468494 NM_BCM1_CAB "CAB = Clusteraktivbits";
CM_ SG_ 2600468494 NM_BCM1_Car_Wakeup "Car Wakeup (Gateway wertet aus)

MQB: 
-Kl.58xd, Kl.58xs, Kl.58xt eingeschaltet oder ausgeschaltet oder Dimmungssignal wurde vom Kunden geändert (nicht vom Fototransistor)
-S-Kontakt wurde ein- oder ausgeschaltet
-Remotestartbetrieb
-Tankklappe wurd";
CM_ SG_ 2600468494 NM_BCM1_CBV_AWB "Das Signal ist zu setzen, wenn das SG aktiv den Bus geweckt hat
0 = Passiver_WakeUp = SG hat das Netzwerk nicht aktiv geweckt
1 = Akitiver_WakeUp = SG hat das Netzwerk aktiv geweckt";
CM_ SG_ 2600468494 NM_BCM1_CBV_CRI "Das Signal ist dauerhaft gesetzt, wenn das NM-Layout Cluster- Anforderungen enthält";
CM_ SG_ 2600468494 NM_BCM1_NM_aktiv_Aussenlicht "Funktionsnachlauf Außenlicht (inkl. Blinken, Warnblinken, Lichthupe)";
CM_ SG_ 2600468494 NM_BCM1_NM_aktiv_ComingHome "ComingHome aktiv, max. 120s";
CM_ SG_ 2600468494 NM_BCM1_NM_aktiv_Diagnose "Diagnose befindet sich nach VW80124 in einer NonDefaultDiagnostic-Session, z.B. ExtendedDiagnostic-Session";
CM_ SG_ 2600468494 NM_BCM1_NM_aktiv_Innenlicht_Dim "Innenlicht, 58xst_xt_xd, 58xt_Ende, Vers.Kl.30G";
CM_ SG_ 2600468494 NM_BCM1_NM_aktiv_KL15 "Steuergerät hat KL15-EIN erkannt";
CM_ SG_ 2600468494 NM_BCM1_NM_aktiv_Klimatisierung "Aktiv aufgrund Klimatisierung";
CM_ SG_ 2600468494 NM_BCM1_NM_aktiv_LeavingHome "LeavingHome aktiv, max. 60s
Annaeherungslicht";
CM_ SG_ 2600468494 NM_BCM1_NM_aktiv_LIM "Aktiv aufgrund Lichtinnenmodul";
CM_ SG_ 2600468494 NM_BCM1_NM_aktiv_Notlaufblinken "Notlaufblinken bei Ausfall BCM2";
CM_ SG_ 2600468494 NM_BCM1_NM_aktiv_Taster_Schalter "Warnblink-Taster, Scheinwerferdiebstahlueberwachung, Display-Taster, Valet-Taster, Motorhaubenkontakt, SPR";
CM_ SG_ 2600468494 NM_BCM1_NM_aktiv_Tmin "Mindestaktivzeit ist noch nicht abgelaufen (bei jedem Weckereignis wird die Mindestaktivzeit neu gestartet)";
CM_ SG_ 2600468494 NM_BCM1_NM_State "1 = Zustand Repeat Message (<-- Bus-Sleep Mode)
2 = Zustand Repeat Message (<-- Prepare Bus-Sleep Mode)
4 = Zustand Normal Operation (<-- Repeat Message)
8 = Zustand Normal Operation (<-- Ready Sleep)";
CM_ SG_ 2600468494 NM_BCM1_SNI "Source Node-Identifier (SNI) identifiziert den Sender der NM-Botschaft (Knotenadresse) eindeutig im Fahrzeug";
CM_ SG_ 2600468494 NM_BCM1_UDS_CC "Funktionseinschränkung aufgrund aktivem UDS-Communication Control, siehe VW80124";

CM_ SG_ 2600468496 NM_Gateway_CAB "CAB = Clusteraktivbits";
CM_ SG_ 2600468496 NM_Gateway_Car_Wakeup "Car Wakeup (Subbusmaster wertet aus)

MQB: 
-Diagnose- oder Komponentenschutzmaster-Funktion weckt den schlafenden Subbus (z.B. MOST)

E3_Volumen:
- Diagnose aktiv -aktive Diagnosekommunikation am OBD-Stecker

MQBw_Baseline:
- Diagnose aktiv -akt";
CM_ SG_ 2600468496 NM_Gateway_CBV_AWB "Das Signal ist zu setzen, wenn das SG aktiv den Bus geweckt hat
0 = Passiver_WakeUp = SG hat das Netzwerk nicht aktiv geweckt
1 = Akitiver_WakeUp = SG hat das Netzwerk aktiv geweckt";
CM_ SG_ 2600468496 NM_Gateway_CBV_CRI "Das Signal ist dauerhaft gesetzt, wenn das NM-Layout Cluster- Anforderungen enthält";
CM_ SG_ 2600468496 NM_Gateway_NM_aktiv_Buskopplung "Nachlauf aufgrund Kopplung zweier Busse. z.B. K-CAN und K2-CAN";
CM_ SG_ 2600468496 NM_Gateway_NM_aktiv_Connect "Nachlauf aufgrund Connect";
CM_ SG_ 2600468496 NM_Gateway_NM_aktiv_CWU "Nachlauf aufgrund CWU Anforderung";
CM_ SG_ 2600468496 NM_Gateway_NM_aktiv_Diagnose "Diagnose befindet sich nach VW80124 in einer NonDefaultDiagnostic-Session, z.B. ExtendedDiagnostic-Session";
CM_ SG_ 2600468496 NM_Gateway_NM_aktiv_EM "Nachlauf aufgrund Energiemanagement";
CM_ SG_ 2600468496 NM_Gateway_NM_aktiv_FC "Nachlauf aufgrund Funktionscluster Anforderung";
CM_ SG_ 2600468496 NM_Gateway_NM_aktiv_Fremdladung "Nachlauf aufgrund Fremdladung";
CM_ SG_ 2600468496 NM_Gateway_NM_aktiv_KL15 "Steuergerät hat KL15-EIN erkannt";
CM_ SG_ 2600468496 NM_Gateway_NM_aktiv_LIN2 "Bus aktiv aufgrund aktivem LIN2 (Hupe betätigt)";
CM_ SG_ 2600468496 NM_Gateway_NM_aktiv_OBDC "Nachlauf aufgrund OBDC";
CM_ SG_ 2600468496 NM_Gateway_NM_aktiv_Tmin "Mindestaktivzeit ist noch nicht abgelaufen (bei jedem Weckereignis wird die Mindestaktivzeit neu gestartet)";
CM_ SG_ 2600468496 NM_Gateway_NM_State "1 = Zustand Repeat Message (<-- Bus-Sleep Mode)
2 = Zustand Repeat Message (<-- Prepare Bus-Sleep Mode)
4 = Zustand Normal Operation (<-- Repeat Message)
8 = Zustand Normal Operation (<-- Ready Sleep)";
CM_ SG_ 2600468496 NM_Gateway_SNI "Source Node-Identifier (SNI) identifiziert den Sender der NM-Botschaft (Knotenadresse) eindeutig im Fahrzeug";
CM_ SG_ 2600468496 NM_Gateway_UDS_CC "Funktionseinschränkung aufgrund aktivem UDS-Communication Control, siehe VW80124";

CM_ SG_ 2600468550 NM_Klima_CAB "CAB = Clusteraktivbits";
CM_ SG_ 2600468550 NM_Klima_Car_Wakeup "Car Wakeup (Gateway wertet aus)
MQB: STH einschalten (Zielzeitlogik), Standheizbetrieb angefordert (Sofortheiztaste gedrückt, Ein- und Ausschalten), Restwärmefunktion angefordert, Umentscheidung STL nach STH, Ablauf max Betriebsdauer

MLBevo: STH einsc";
CM_ SG_ 2600468550 NM_Klima_CBV_AWB "Das Signal ist zu setzen, wenn das SG aktiv den Bus geweckt hat";
CM_ SG_ 2600468550 NM_Klima_CBV_CRI "Das Signal ist dauerhaft gesetzt, wenn das NM-Layout dem neuen NM-Layout für Teilnetzbetrieb entspricht";
CM_ SG_ 2600468550 NM_Klima_NM_aktiv_Abstellzstd "Abstellzustand für Klima herstellen. Definierte Beendigung der Funktionen nach KL15 AUS";
CM_ SG_ 2600468550 NM_Klima_NM_aktiv_Diagnose "Diagnose befindet sich nach VW80124 in einer NonDefaultDiagnostic-Session, z.B. ExtendedDiagnostic-Session";
CM_ SG_ 2600468550 NM_Klima_NM_aktiv_KL15 "Steuergerät hat KL15-EIN erkannt";
CM_ SG_ 2600468550 NM_Klima_NM_aktiv_Tmin "Mindestaktivzeit ist noch nicht abgelaufen (bei jedem Weckereignis wird die Mindestaktivzeit neu gestartet)";
CM_ SG_ 2600468550 NM_Klima_NM_State "1 = Zustand Repeat Message (<-- Bus-Sleep Mode)
2 = Zustand Repeat Message (<-- Prepare Bus-Sleep Mode)
4 = Zustand Normal Operation (<-- Repeat Message)
8 = Zustand Normal Operation (<-- Ready Sleep)";
CM_ SG_ 2600468550 NM_Klima_SNI "Source Node-Identifier (SNI) identifiziert den Sender der NM-Botschaft (Knotenadresse) eindeutig im Fahrzeug";
CM_ SG_ 2600468550 NM_Klima_UDS_CC "Funktionseinschränkung aufgrund aktivem UDS-Communication Control; siehe VW80124";

CM_ SG_ 2600468569 NM_Lift_VA_CAB "CAB = Clusteraktivbits";
CM_ SG_ 2600468569 NM_Lift_VA_Car_Wakeup "Car Wakeup (Gateway wertet aus)
MQB: Kl.58xd, Kl.58xs, Kl.58xt eingeschaltet oder ausgeschaltet oder Dimmungssignal wurde vom Kunden geändert (nicht vom Fototransistor); S-Kontakt wurde ein- oder ausgeschaltet; Remotestartbetrieb; Tankklappe wurde geschl";
CM_ SG_ 2600468569 NM_Lift_VA_CBV_AWB "Das Signal ist zu setzen, wenn das SG aktiv den Bus geweckt hat";
CM_ SG_ 2600468569 NM_Lift_VA_CBV_CRI "Das Signal ist dauerhaft gesetzt, wenn das NM-Layout dem neuen NM-Layout für Teilnetzbetrieb entspricht";
CM_ SG_ 2600468569 NM_Lift_VA_NM_aktiv_Diag "Diagnose befindet sich nach VW80124 in einer NonDefaultDiagnostic-Session, z.B. ExtendedDiagnostic-Session";
CM_ SG_ 2600468569 NM_Lift_VA_NM_aktiv_KL15 "Steuergerät hat KL15-EIN erkannt";
CM_ SG_ 2600468569 NM_Lift_VA_NM_aktiv_Tmin "Mindestaktivzeit ist noch nicht abgelaufen (bei jedem Weckereignis wird die Mindestaktivzeit neu gestartet)";
CM_ SG_ 2600468569 NM_Lift_VA_NM_State "1 = Zustand Repeat Message (<-- Bus-Sleep Mode)
2 = Zustand Repeat Message (<-- Prepare Bus-Sleep Mode)
4 = Zustand Normal Operation (<-- Repeat Message)
8 = Zustand Normal Operation (<-- Ready Sleep)";
CM_ SG_ 2600468569 NM_Lift_VA_SNI "Source Node-Identifier (SNI) identifiziert den Sender der NM-Botschaft (Knotenadresse) eindeutig im Fahrzeug";
CM_ SG_ 2600468569 NM_Lift_VA_UDS_CC "Funktionseinschränkung aufgrund aktivem UDS-Communication Control; siehe VW80124";

CM_ SG_ 2600468676 NM_VAS_L_CAB "CAB = Clusteraktivbits";
CM_ SG_ 2600468676 NM_VAS_L_Car_Wakeup "Car Wakeup (Gateway wertet aus)";
CM_ SG_ 2600468676 NM_VAS_L_CBV_AWB "Das Signal ist zu setzen, wenn das SG aktiv den Bus geweckt hat
0 = Passiver_WakeUp = SG hat das Netzwerk nicht aktiv geweckt
1 = Akitiver_WakeUp = SG hat das Netzwerk aktiv geweckt";
CM_ SG_ 2600468676 NM_VAS_L_CBV_CRI "Das Signal ist dauerhaft gesetzt, wenn das NM-Layout dem neuen NM-Layout für Teilnetzbetrieb entspricht";
CM_ SG_ 2600468676 NM_VAS_L_NM_aktiv_Diagnose "Diagnose befindet sich nach VW80124 in einer NonDefaultDiagnostic-Session, z.B. ExtendedDiagnostic-Session";
CM_ SG_ 2600468676 NM_VAS_L_NM_aktiv_KL15 "Steuergerät hat KL15-EIN erkannt";
CM_ SG_ 2600468676 NM_VAS_L_NM_aktiv_Tmin "Mindestaktivzeit ist noch nicht abgelaufen (bei jedem Weckereignis wird die Mindestaktivzeit neu gestartet)";
CM_ SG_ 2600468676 NM_VAS_L_NM_aktiv_Verstellung "Verstellung im Display des VAS";
CM_ SG_ 2600468676 NM_VAS_L_NM_State "1 = Zustand Repeat Message (<-- Bus-Sleep Mode) 
2 = Zustand Repeat Message (<-- Prepare Bus-Sleep Mode) 
4 = Zustand Normal Operation (<-- Repeat Message) 
8 = Zustand Normal Operation (<-- Ready Sleep) 
16 = Zustand Repeat Message (<-- Ready Sleep) ";
CM_ SG_ 2600468676 NM_VAS_L_SNI "Source Node-Identifier (SNI) identifiziert den Sender der NM-Botschaft (Knotenadresse) eindeutig im Fahrzeug";
CM_ SG_ 2600468676 NM_VAS_L_UDS_CC "Funktionseinschränkung aufgrund aktivem UDS-Communication Control; siehe VW80124";

CM_ SG_ 2600468677 NM_VAS_R_CAB "CAB = Clusteraktivbits";
CM_ SG_ 2600468677 NM_VAS_R_Car_Wakeup "Car Wakeup (Gateway wertet aus)";
CM_ SG_ 2600468677 NM_VAS_R_CBV_AWB "Das Signal ist zu setzen, wenn das SG aktiv den Bus geweckt hat
0 = Passiver_WakeUp = SG hat das Netzwerk nicht aktiv geweckt
1 = Akitiver_WakeUp = SG hat das Netzwerk aktiv geweckt";
CM_ SG_ 2600468677 NM_VAS_R_CBV_CRI "Das Signal ist dauerhaft gesetzt, wenn das NM-Layout dem neuen NM-Layout für Teilnetzbetrieb entspricht";
CM_ SG_ 2600468677 NM_VAS_R_NM_aktiv_Diagnose "Diagnose befindet sich nach VW80124 in einer NonDefaultDiagnostic-Session, z.B. ExtendedDiagnostic-Session";
CM_ SG_ 2600468677 NM_VAS_R_NM_aktiv_KL15 "Steuergerät hat KL15-EIN erkannt";
CM_ SG_ 2600468677 NM_VAS_R_NM_aktiv_Tmin "Mindestaktivzeit ist noch nicht abgelaufen (bei jedem Weckereignis wird die Mindestaktivzeit neu gestartet)";
CM_ SG_ 2600468677 NM_VAS_R_NM_aktiv_Verstellung "Verstellung im Display des VAS (nur Rechtslenker)";
CM_ SG_ 2600468677 NM_VAS_R_NM_State "1 = Zustand Repeat Message (<-- Bus-Sleep Mode) 
2 = Zustand Repeat Message (<-- Prepare Bus-Sleep Mode) 
4 = Zustand Normal Operation (<-- Repeat Message) 
8 = Zustand Normal Operation (<-- Ready Sleep) 
16 = Zustand Repeat Message (<-- Ready Sleep) ";
CM_ SG_ 2600468677 NM_VAS_R_SNI "Source Node-Identifier (SNI) identifiziert den Sender der NM-Botschaft (Knotenadresse) eindeutig im Fahrzeug";
CM_ SG_ 2600468677 NM_VAS_R_UDS_CC "Funktionseinschränkung aufgrund aktivem UDS-Communication Control; siehe VW80124";

CM_ SG_ 1377 NV_MessZeitpunkt "Messzeitpunkt der Objekte und der Ergebnisse anderer Wahrnehmungsmodule
Bei Nightvision: Aufnahmezeitpunkt des zugehörigen Bildes";
CM_ SG_ 1377 NV_NichtVerfuegbar "Verfuegbarkeit Nightvision";
CM_ SG_ 1377 NV_Obj_01_InvTTCBildebStdA "Standardabweichung zu NV_Obj_01_InvTTCBildeb";
CM_ SG_ 1377 NV_Obj_01_Klasse "Klasse des Objekts";
CM_ SG_ 1377 NV_Obj_Links "Objekt für Markierungslicht in Fahrtrichtung links";
CM_ SG_ 1377 NV_Obj_Rechts "Objekt für Markierungslicht in Fahrtrichtung rechts";
CM_ SG_ 1377 NV_Obj_Warnung_Fussgaenger "Warnung auf NV_Obj_01 im Fahrzeug signalisiert";
CM_ SG_ 1377 NV_Sensor_PositionX "Position der Kamera in USK-Koordinaten
x-Koordinate des Fokussierpunktes der Kamera-Optik";
CM_ SG_ 1377 NV_Sensor_PositionY "Position der Kamera in USK-Koordinaten
y-Koordinate des Fokussierpunktes der Kamera-Optik";
CM_ SG_ 1377 NV_Sensor_PositionZ "Position der Kamera in USK-Koordinaten
z-Koordinate des Fokussierpunktes der Kamera-Optik";

CM_ SG_ 1635 BEM_02_Abschaltstufen "Abschaltstufen des Ruhestrommanagements (Initialisierungswert aus EEprom)

Stufe 0 (keine Einschraenkungen)
Stufe 1 (Abschaltung Hochstromverbraucher)
Stufe 2 (Infotainmentabschaltung)
Stufe 3 (Wake-Up-Sperre)

Für den Transport- und Ruhestrommessm";
CM_ SG_ 1635 BEM_Anf_KL15_schalten "Abschaltempfehlung bzw. Verhinderung der automatischen Abschaltung Kl15 durch das BCM";
CM_ SG_ 1635 BEM_Batteriediagnose "Anzeige von Textwarnungen";
CM_ SG_ 1635 BEM_Generatordiagnose "Ansteuerung Generatorwarnleuchte im Kombi
";
CM_ SG_ 1635 BEM_HL_Regelung_Status "Status Regelung Heizleistung
";
CM_ SG_ 1635 BEM_Ladezustand "Ladezustand der Niedervoltbatterie
";
CM_ SG_ 1635 BEM_MMI_Vorwarnung "Anzeige Vorwarnung MMI-Abschaltung (Initialisierungswert aus EEprom)
";
CM_ SG_ 1635 BEM_Red_Innengeblaese "Reduzierung Innengebläse
";
CM_ SG_ 1635 BEM_REK_aktiv "Rekuperationsfreigabe vom Energiemanagement
0x0 = keine Rekuperationsfreigabe
0x1 = Rekuperationsfreigabe";
CM_ SG_ 1635 BEM_STH_Einschaltverbot "Einschränkung Standheizung/-lüftung durch BEM: Setzt der BEM das Bit, dann darf die Standheizung nicht mehr einschalten
(Die Standheizung muss aber nicht abschalten, sondern darf weiterbrennen)
(Initialisierungswert aus EEprom)
";
CM_ SG_ 1635 BEM_STH_Zielzeit "Maximal mögliche Zeit für den Standheizungsbetrieb, um die Startfähigkeit nicht zu gefährden";
CM_ SG_ 1635 BEM_UBDM "Batteriespannung, gemessen vom Batteriedatenmodul";
CM_ SG_ 1635 BEM_UGenSoll "Sollspannungsvorgabe an den Generator, beinhaltet temperaturoptimierte Batterieladung und Rekuperation";
CM_ SG_ 1635 MIB_Stromsparmodus "Signal beschreibt die Aktivierung für den Stromsparmodus beim MIB.
Bei AUS (= 0) gibt es keine weitere Anforderung an die MIB-Komponenten.
Bei EIN (= 1) werden alle MIB Komponenten in einen Stromsparmodus versetzt.";
CM_ SG_ 1635 NVEM_Anf_SD_schalten "Anforderung Nachlauf für den Steckdosenbetrieb
Initialisierungswert aus EEprom";
CM_ SG_ 1635 NVEM_Batterie_Service "Anforderung einer Batterie-Service - Anzeige / Anforderung an die Werkstatt über MOD";
CM_ SG_ 1635 NVEM_Freigabe_OnlineUpdate "Freigabe für Online-Update durch Energiemanagement";
CM_ SG_ 1635 NVEM_Freigabe_ORU4 "Bestätigung oder Ablehnung eines konkreten, angefragten Online Updates durch das Energiemanagements";
CM_ SG_ 1635 NVEM_Last_Anf "Das NVEM fordert für die Batteriediagnose einen Lastimpuls vom Fahrzeug an, der durch kontrollierte Verbraucherzuschaltungen (z. B. Aktivierung Heckscheibenheizung) generiert wird";

CM_ SG_ 2527679508 NVEM_06_BZ "4bit Botschaftszähler, wird mit jeder Sendebotschaft inkrementiert";
CM_ SG_ 2527679508 NVEM_06_CRC "Für MLB:
'Berechnung siehe Lastenheft 'Kommunikationsabsicherung für FlexRay und CAN''

Ab MQB und MLBevo:
'Berechnung siehe Lastenheft 'End-to-End Kommunikationsabsicherung''

Endwerte siehe Begleitdokument 'S-PDU Kennungsfolgen'";
CM_ SG_ 2527679508 NVEM_Bordnetzdiagnose "Wird vom NVEM im NV-Netz ein Bordnetz-Fehler erkannt, so soll dies zu einer mehrstufigen Anzeige führen.";
CM_ SG_ 2527679508 NVEM_Energie_Klima_Vorgabe "NVEM-Energievorgabe für Klima-Vorkonditionierung";
CM_ SG_ 2527679508 NVEM_Max_Rampenzeit "Vorgabe der max. Rampenzeit für den Generatorbetrieb des 12V-RSG (RSG-Ansteuerung durch Motor-SG)";
CM_ SG_ 2527679508 NVEM_Max_Spannung "Mild_Hybrid: erlaubte Maximalspannung 12V - Netz
";
CM_ SG_ 2527679508 NVEM_Min_Spannung "Mild_Hybrid: erforderliche Mindestspannung 12V - Netz";
CM_ SG_ 2527679508 NVEM_Min_Spannung_Start "Minimale einzuhaltende Spannung im RSG Wiederstart";
CM_ SG_ 2527679508 NVEM_MV_DC_uMinLV "Abregelgrenze: minimal erlaubte Bordnetzspannung im Hochsetzbetrieb vom 12V-Bordnetz ins 48V-Netz";
CM_ SG_ 2527679508 NVEM_MV_DC_uSollLV "Sollwert für die 12V-Bordnetzspannung im Tiefsetzbetrieb vom 48V-Netz ins 12V-Bordnetz";

CM_ SG_ 913 MO_QBit_Aussen_Temp "QBit der Aussentemperatur. Gesetzt bei Ersatzwert, Init oder Fehler.";
CM_ SG_ 913 MO_Servicemodus "Ausgabe aktiver Service-Mode";
CM_ SG_ 913 OBD_Abs_Load_Val "Absolute Load Value

Übertragung von Meßgrößen an das Getriebesteuergerät für Freeze Frame Abspeicherung bei Getriebefehlern

PID $43 Absolute Load Value; 0 .. 25700%  mit 100/255 %/bit";
CM_ SG_ 913 OBD_Abs_Pedal_Pos "Absolute Pedal Position

Übertragung von Meßgrößen an das Getriebesteuergerät für Freeze Frame Abspeicherung bei Getriebefehlern

PID $49 Accelerator Pedal Position D; 0 .. 100% mit 100/255 %/bit";
CM_ SG_ 913 OBD_Abs_Throttle_Pos "Absolute Throttle Position

Übertragung von Meßgrößen an das Getriebesteuergerät für Freeze Frame Abspeicherung bei Getriebefehlern

PID $11 Absolute Throttle Position; 0 .. 100% mit 100/255 %/bit";
CM_ SG_ 913 OBD_Calc_Load_Val "Calculated Load Value

Übertragung von Meßgrößen an das Getriebesteuergerät für Freeze Frame Abspeicherung bei Getriebefehlern

PID $04 Calculated Load Value; 0 .. 100% mit 100/255 % per bit
";
CM_ SG_ 913 OBD_ClearMem_Inhibit "Bei FSP_Loeschen_zulässig müssen alle OBD-ECUs im Gesamtfahrzeug einen Service 04hex Request (Ereignisspeicher löschen) korrekt ausführen. 

In MLB-, MLBevo-, MQB-Fahrzeugkonzepten muss der MIL-Master/Motorsteuergerät bei Kl.15 ein, projektabhängig, kon";
CM_ SG_ 913 OBD_Driving_Cycle "Signalisierung Driving Cycle Qualifizierung - Trigger Ignition Cycle Counter";
CM_ SG_ 913 OBD_Eng_Cool_Temp "Engine Coolant Temperature

Übertragung von Meßgrößen an das Getriebesteuergerät für Freeze Frame Abspeicherung bei Getriebefehlern

PID $05 Engine Coolant Temperature; -40 .. +215°C mit 1°C/bit und 40°C Offset";
CM_ SG_ 913 OBD_Kaltstart_Denominator "Bestimmte Diagnosen werden nur unter Kaltstartbedingungen durchgeführt, der entsprechende Denominator bei IUMPR-pflichtigen Systemen wird anhand dieses vom MSG gebildeten Signals inkrementiert. (Entspricht EVAP-Denominator)";
CM_ SG_ 913 OBD_Minimum_Trip "Grundlage OBD-Gesetz CCR 1968.2 (d)(4.3) Denominator Specifications
Bildung des General Denominator 'Normed Trip':
 600 sec. (kumulativ) Zeit nach Motorstart
 300 sec. (kumulativ) mit Fahrzeuggeschwindigkeit > 25 mph (40 km/h)
 30 sec. (kontinuierlich";
CM_ SG_ 913 OBD_Normed_Trip "Gesetzlich definierte 'Normed Condition' erfüllt, 'General Denominator' darf erhöht werden";
CM_ SG_ 913 OBD_Sperrung_IUMPR "Wenn der General Denominator auf Grund eines Fehlers in den Eingangsgrößen gesperrt wird, wird diese Information über Bussystem als OBD-Statusinformation OBD_Sperrung_IUMPR für andere OBD-Steuergeräte bereitgestellt. 

Das MSG (MIL-Master) setzt dieses ";
CM_ SG_ 913 OBD_Sperrung_Kaltstart_Denom "Information vom MIL Master, dass die Bildung des EVAP Denominators  im Motor nicht möglich ist und damit der noECM-Denominator gesperrt werden darf.";
CM_ SG_ 913 OBD_Warm_Up_Cycle "Mit dem Warm-Up-Cycle wird der zentrale Verlernzähler vom Gateway inkrementiert";

CM_ SG_ 2549875352 OBDC_DMD_L_Req_Data "Request FID- zu NA- Kommunikation zw. OnboardDiagnoseClient und Knoten";

CM_ SG_ 2550006424 OBDC_DMD_L_Resp_Data "Response FID- zu NA- Kommunikation zw. OnboardDiagnoseClient und Knoten";

CM_ SG_ 2549875353 OBDC_DMD_R_Req_Data "Request FID- zu NA- Kommunikation zw. OnboardDiagnoseClient und Knoten";

CM_ SG_ 2550006425 OBDC_DMD_R_Resp_Data "Response FID- zu NA- Kommunikation zw. OnboardDiagnoseClient und Knoten";

CM_ SG_ 2549940736 OBDC_Funktionaler_Req_All_Data "VDC funktionaler Request auf CANHS";
BA_DEF_REL_ BU_SG_REL_  "GenSigTimeoutTime" INT 0 65535;
BA_DEF_ BO_  "DiagRequest" ENUM "No", "Yes";
BA_DEF_ BO_  "DiagResponse" ENUM "No", "Yes";
BA_DEF_ BO_  "DiagState" ENUM "No", "Yes";
BA_DEF_ BO_  "GenMsgChkConstant" HEX 0 4095;
BA_DEF_ BO_  "GenMsgCycleTime" INT 0 65535;
BA_DEF_ BO_  "GenMsgCycleTimeFast" INT 0 65535;
BA_DEF_ BO_  "GenMsgDelayTime" INT 0 100000;
BA_DEF_ BO_  "GenMsgILSupport" ENUM "No", "Yes";
BA_DEF_ BO_  "GenMsgNrOfRepetition" INT 0 100;
BA_DEF_ BO_  "GenMsgPDUConstants" STRING;
BA_DEF_ BO_  "GenMsgSendType" ENUM "Cyclic", "not_used", "not_used", "not_used", "not_used", "not_used", "not_used", "IfActive", "NoMsgSendType";
BA_DEF_ BO_  "GenMsgStartDelayTime" INT 0 100000;
BA_DEF_ BO_  "NmMessage" ENUM "No", "Yes";
BA_DEF_ BO_  "NmhMessage" ENUM "No", "Yes";
BA_DEF_ BO_  "MsgType" ENUM "Application", "NM ", "NMH", "TP2.0", "ISO-TP ", "BAP", "EID", "KS", "XCP_PRE_CONFIGURED", "XCP_RUNTIME_CONFIGURED";
BA_DEF_ BO_  "VAGTP20_API" HEX 0 255;
BA_DEF_ BO_  "VAGTP20_DynConnection" ENUM "No", "Yes";
BA_DEF_ BO_  "VAGTP20_DynSetup" ENUM "No", "Yes";
BA_DEF_ BO_  "VAGTP20_StatConnection" ENUM "No", "Yes";
BA_DEF_ SG_  "GenSigActiveRepetitions" INT -2147483648 2147483647;
BA_DEF_ SG_  "GenSigInactiveValue" INT -2147483648 2147483647;
BA_DEF_ SG_  "GenSigSendType" ENUM "Cyclic", "OnWrite", "OnWriteWithRepetition", "OnChange", "OnChangeWithRepetition", "IfActive", "IfActiveWithRepetition", "NoSigSendType", "OnChangeAndIfActive", "OnChangeAndIfActiveWithRepetition";
BA_DEF_ SG_  "GenSigStartValue" INT -2147483648 2147483647;
BA_DEF_ SG_  "NWM-WakeupAllowed" ENUM "No", "Yes";
BA_DEF_ SG_  "GenSigFuncType" ENUM "NoFunction", "MsgCounter", "CRC-8", "XOR", "XOR-2", "DatedBit", "SW-Kl15", "CHK", "Constant", "Protocol", "CRC-8-SAE_J1850", "CRC-32", "DataLength", "DataID", "MsgCounter16", "SOK-Signatur", "Cluster";
BA_DEF_ SG_  "GenSigSwitchedByIgnition" ENUM "No", "Yes";
BA_DEF_ SG_  "Fehlerwert" HEX 0 2147483647;
BA_DEF_ SG_  "GenSigMissingSourceValue" HEX 0 2147483647;
BA_DEF_DEF_REL_  "GenSigTimeoutTime" 0;
BA_DEF_DEF_  "DiagRequest" "No";
BA_DEF_DEF_  "DiagResponse" "No";
BA_DEF_DEF_  "DiagState" "No";
BA_DEF_DEF_  "GenMsgChkConstant" 0;
BA_DEF_DEF_  "GenMsgCycleTime" 0;
BA_DEF_DEF_  "GenMsgCycleTimeFast" 0;
BA_DEF_DEF_  "GenMsgDelayTime" 0;
BA_DEF_DEF_  "GenMsgILSupport" "No";
BA_DEF_DEF_  "GenMsgNrOfRepetition" 0;
BA_DEF_DEF_  "GenMsgPDUConstants" "";
BA_DEF_DEF_  "GenMsgSendType" "NoMsgSendType";
BA_DEF_DEF_  "GenMsgStartDelayTime" 0;
BA_DEF_DEF_  "NmMessage" "No";
BA_DEF_DEF_  "NmhMessage" "No";
BA_DEF_DEF_  "MsgType" "Application";
BA_DEF_DEF_  "VAGTP20_API" 0;
BA_DEF_DEF_  "VAGTP20_DynConnection" "No";
BA_DEF_DEF_  "VAGTP20_DynSetup" "No";
BA_DEF_DEF_  "VAGTP20_StatConnection" "No";
BA_DEF_DEF_  "GenSigActiveRepetitions" 0;
BA_DEF_DEF_  "GenSigInactiveValue" 0;
BA_DEF_DEF_  "GenSigSendType" "NoSigSendType";
BA_DEF_DEF_  "GenSigStartValue" 0;
BA_DEF_DEF_  "NWM-WakeupAllowed" "No";
BA_DEF_DEF_  "GenSigFuncType" "NoFunction";
BA_DEF_DEF_  "GenSigSwitchedByIgnition" "Yes";
BA_DEF_DEF_  "Fehlerwert" 0;
BA_DEF_DEF_  "GenSigMissingSourceValue" 0;
BA_ "GenMsgCycleTime" BO_ 1648 500;
BA_ "GenMsgDelayTime" BO_ 1648 20;
BA_ "GenMsgILSupport" BO_ 1648 1;
BA_ "GenMsgSendType" BO_ 1648 0;
BA_ "GenMsgCycleTime" BO_ 289 40;
BA_ "GenMsgILSupport" BO_ 289 1;
BA_ "GenMsgPDUConstants" BO_ 289 "0xe9,0x65,0xae,0x6b,0x7b,0x35,0xe5,0x5f,0x4e,0xc7,0x86,0xa2,0xbb,0xdd,0xeb,0xb4";
BA_ "GenMsgSendType" BO_ 289 0;
BA_ "GenMsgCycleTime" BO_ 1423 320;
BA_ "GenMsgILSupport" BO_ 1423 1;
BA_ "GenMsgSendType" BO_ 1423 0;
BA_ "GenMsgCycleTime" BO_ 967 80;
BA_ "GenMsgILSupport" BO_ 967 1;
BA_ "GenMsgSendType" BO_ 967 0;
BA_ "GenMsgCycleTime" BO_ 340 200;
BA_ "GenMsgILSupport" BO_ 340 1;
BA_ "GenMsgPDUConstants" BO_ 340 "0x21,0x93,0x4a,0x04,0x5c,0x18,0xe0,0x69,0x14,0xce,0x26,0x8f,0x5e,0xb1,0xdf,0x53";
BA_ "GenMsgSendType" BO_ 340 0;
BA_ "GenMsgCycleTime" BO_ 283 500;
BA_ "GenMsgDelayTime" BO_ 283 10;
BA_ "GenMsgILSupport" BO_ 283 1;
BA_ "GenMsgSendType" BO_ 283 0;
BA_ "GenMsgChkConstant" BO_ 1601 71;
BA_ "GenMsgCycleTime" BO_ 1601 960;
BA_ "GenMsgILSupport" BO_ 1601 1;
BA_ "GenMsgPDUConstants" BO_ 1601 "0x47,0x47,0x47,0x47,0x47,0x47,0x47,0x47,0x47,0x47,0x47,0x47,0x47,0x47,0x47,0x47";
BA_ "GenMsgSendType" BO_ 1601 0;
BA_ "GenMsgCycleTime" BO_ 394 200;
BA_ "GenMsgDelayTime" BO_ 394 10;
BA_ "GenMsgILSupport" BO_ 394 1;
BA_ "GenMsgSendType" BO_ 394 0;
BA_ "GenMsgCycleTime" BO_ 1156 1000;
BA_ "GenMsgILSupport" BO_ 1156 1;
BA_ "GenMsgSendType" BO_ 1156 0;
BA_ "GenMsgCycleTime" BO_ 1157 1000;
BA_ "GenMsgILSupport" BO_ 1157 1;
BA_ "GenMsgSendType" BO_ 1157 0;
BA_ "GenMsgCycleTime" BO_ 2527679512 1000;
BA_ "GenMsgILSupport" BO_ 2527679512 1;
BA_ "GenMsgSendType" BO_ 2527679512 0;
BA_ "GenMsgCycleTime" BO_ 1158 1000;
BA_ "GenMsgILSupport" BO_ 1158 1;
BA_ "GenMsgSendType" BO_ 1158 0;
BA_ "GenMsgCycleTime" BO_ 2589283496 500;
BA_ "GenMsgILSupport" BO_ 2589283496 1;
BA_ "GenMsgSendType" BO_ 2589283496 0;
BA_ "GenMsgCycleTime" BO_ 2527679647 200;
BA_ "GenMsgILSupport" BO_ 2527679647 1;
BA_ "GenMsgSendType" BO_ 2527679647 0;
BA_ "GenMsgCycleTime" BO_ 1696 200;
BA_ "GenMsgDelayTime" BO_ 1696 20;
BA_ "GenMsgILSupport" BO_ 1696 1;
BA_ "GenMsgSendType" BO_ 1696 0;
BA_ "GenMsgCycleTime" BO_ 2600468494 200;
BA_ "GenMsgCycleTimeFast" BO_ 2600468494 10;
BA_ "GenMsgNrOfRepetition" BO_ 2600468494 3;
BA_ "GenMsgSendType" BO_ 2600468494 7;
BA_ "NmhMessage" BO_ 2600468494 1;
BA_ "MsgType" BO_ 2600468494 2;
BA_ "GenMsgCycleTime" BO_ 2600468496 200;
BA_ "GenMsgCycleTimeFast" BO_ 2600468496 10;
BA_ "GenMsgNrOfRepetition" BO_ 2600468496 3;
BA_ "GenMsgSendType" BO_ 2600468496 7;
BA_ "NmhMessage" BO_ 2600468496 1;
BA_ "MsgType" BO_ 2600468496 2;
BA_ "GenMsgCycleTime" BO_ 2600468550 200;
BA_ "GenMsgCycleTimeFast" BO_ 2600468550 10;
BA_ "GenMsgNrOfRepetition" BO_ 2600468550 3;
BA_ "GenMsgSendType" BO_ 2600468550 7;
BA_ "NmhMessage" BO_ 2600468550 1;
BA_ "MsgType" BO_ 2600468550 2;
BA_ "GenMsgCycleTime" BO_ 2600468569 200;
BA_ "GenMsgCycleTimeFast" BO_ 2600468569 10;
BA_ "GenMsgNrOfRepetition" BO_ 2600468569 3;
BA_ "GenMsgSendType" BO_ 2600468569 7;
BA_ "NmhMessage" BO_ 2600468569 1;
BA_ "MsgType" BO_ 2600468569 2;
BA_ "GenMsgCycleTime" BO_ 2600468676 200;
BA_ "GenMsgCycleTimeFast" BO_ 2600468676 10;
BA_ "GenMsgNrOfRepetition" BO_ 2600468676 3;
BA_ "GenMsgSendType" BO_ 2600468676 7;
BA_ "NmhMessage" BO_ 2600468676 1;
BA_ "MsgType" BO_ 2600468676 2;
BA_ "GenMsgCycleTime" BO_ 2600468677 200;
BA_ "GenMsgCycleTimeFast" BO_ 2600468677 10;
BA_ "GenMsgNrOfRepetition" BO_ 2600468677 3;
BA_ "GenMsgSendType" BO_ 2600468677 7;
BA_ "NmhMessage" BO_ 2600468677 1;
BA_ "MsgType" BO_ 2600468677 2;
BA_ "GenMsgCycleTime" BO_ 1377 200;
BA_ "GenMsgDelayTime" BO_ 1377 40;
BA_ "GenMsgILSupport" BO_ 1377 1;
BA_ "GenMsgSendType" BO_ 1377 0;
BA_ "GenMsgCycleTime" BO_ 1635 100;
BA_ "GenMsgILSupport" BO_ 1635 1;
BA_ "GenMsgPDUConstants" BO_ 1635 "0x7d,0xba,0x97,0x94,0x5a,0x4a,0xeb,0xd4,0x6c,0x28,0x54,0x81,0xc7,0x1c,0x25,0x2a";
BA_ "GenMsgSendType" BO_ 1635 0;
BA_ "GenMsgStartDelayTime" BO_ 1635 10;
BA_ "GenMsgCycleTime" BO_ 2527679508 100;
BA_ "GenMsgDelayTime" BO_ 2527679508 80;
BA_ "GenMsgILSupport" BO_ 2527679508 1;
BA_ "GenMsgPDUConstants" BO_ 2527679508 "0xa3,0xed,0x65,0xcf,0xc5,0x26,0x54,0x1a,0x99,0x3c,0x01,0x84,0xf4,0x46,0x9c,0x28";
BA_ "GenMsgSendType" BO_ 2527679508 0;
BA_ "GenMsgStartDelayTime" BO_ 2527679508 10;
BA_ "GenMsgCycleTime" BO_ 913 80;
BA_ "GenMsgILSupport" BO_ 913 1;
BA_ "GenMsgSendType" BO_ 913 0;
BA_ "DiagRequest" BO_ 2549875214 1;
BA_ "MsgType" BO_ 2549875214 4;
BA_ "DiagResponse" BO_ 2550006286 1;
BA_ "MsgType" BO_ 2550006286 4;
BA_ "DiagRequest" BO_ 2549875352 1;
BA_ "MsgType" BO_ 2549875352 4;
BA_ "DiagResponse" BO_ 2550006424 1;
BA_ "MsgType" BO_ 2550006424 4;
BA_ "DiagRequest" BO_ 2549875353 1;
BA_ "MsgType" BO_ 2549875353 4;
BA_ "DiagResponse" BO_ 2550006425 1;
BA_ "MsgType" BO_ 2550006425 4;
BA_ "DiagState" BO_ 2549940736 1;
BA_ "MsgType" BO_ 2549940736 4;
BA_ "DiagRequest" BO_ 2549875270 1;
BA_ "MsgType" BO_ 2549875270 4;
BA_ "DiagResponse" BO_ 2550006342 1;
BA_ "MsgType" BO_ 2550006342 4;
BA_ "DiagRequest" BO_ 2549875330 1;
BA_ "MsgType" BO_ 2549875330 4;
BA_ "DiagResponse" BO_ 2550006402 1;
BA_ "MsgType" BO_ 2550006402 4;
BA_ "DiagRequest" BO_ 2549875331 1;
BA_ "MsgType" BO_ 2549875331 4;
BA_ "DiagResponse" BO_ 2550006403 1;
BA_ "MsgType" BO_ 2550006403 4;
BA_ "GenSigSendType" SG_ 1648 MO1_Freigabe_Info_WFS 3;
BA_ "GenSigSwitchedByIgnition" SG_ 1648 MO1_Freigabe_Info_WFS 0;
BA_ "GenSigSendType" SG_ 1648 MO1_Freigabe_Verfallsinfo_WFS 3;
BA_ "GenSigSwitchedByIgnition" SG_ 1648 MO1_Freigabe_Verfallsinfo_WFS 0;
BA_ "GenSigSendType" SG_ 1648 MO1_Sperr_Info_WFS 3;
BA_ "GenSigSwitchedByIgnition" SG_ 1648 MO1_Sperr_Info_WFS 0;
BA_ "GenSigSendType" SG_ 1648 MO_Abstellzeit 0;
BA_ "GenSigStartValue" SG_ 1648 MO_Abstellzeit 254;
BA_ "GenSigSwitchedByIgnition" SG_ 1648 MO_Abstellzeit 0;
BA_ "GenSigSendType" SG_ 1648 MO_Abstellzeit_Status 0;
BA_ "GenSigSwitchedByIgnition" SG_ 1648 MO_Abstellzeit_Status 0;
BA_ "GenSigSendType" SG_ 1648 MO_ANC_Kennfeld_Anf 3;
BA_ "GenSigSwitchedByIgnition" SG_ 1648 MO_ANC_Kennfeld_Anf 0;
BA_ "GenSigSendType" SG_ 1648 MO_Anzahl_Abgesch_Zyl 3;
BA_ "GenSigSwitchedByIgnition" SG_ 1648 MO_Anzahl_Abgesch_Zyl 0;
BA_ "GenSigSendType" SG_ 1648 MO_Bremslicht_Reku 3;
BA_ "GenSigSwitchedByIgnition" SG_ 1648 MO_Bremslicht_Reku 0;
BA_ "GenSigSendType" SG_ 1648 MO_Drehzahl_Warnung 0;
BA_ "GenSigSwitchedByIgnition" SG_ 1648 MO_Drehzahl_Warnung 0;
BA_ "GenSigSendType" SG_ 1648 MO_EPCL 0;
BA_ "GenSigSwitchedByIgnition" SG_ 1648 MO_EPCL 0;
BA_ "GenSigSendType" SG_ 1648 MO_Ethanol_BS_Texte 0;
BA_ "GenSigSwitchedByIgnition" SG_ 1648 MO_Ethanol_BS_Texte 0;
BA_ "GenSigSendType" SG_ 1648 MO_Fahrzeugtyp 0;
BA_ "GenSigFuncType" SG_ 1648 MO_Fahrzeugtyp 8;
BA_ "GenSigSwitchedByIgnition" SG_ 1648 MO_Fahrzeugtyp 0;
BA_ "GenSigSendType" SG_ 1648 MO_Fehler_Zylabsch 0;
BA_ "GenSigSwitchedByIgnition" SG_ 1648 MO_Fehler_Zylabsch 0;
BA_ "GenSigSendType" SG_ 1648 MO_Hybrid_StartStopp_LED 3;
BA_ "GenSigSwitchedByIgnition" SG_ 1648 MO_Hybrid_StartStopp_LED 0;
BA_ "GenSigSendType" SG_ 1648 MO_max_Ladedruck 0;
BA_ "GenSigFuncType" SG_ 1648 MO_max_Ladedruck 8;
BA_ "GenSigSwitchedByIgnition" SG_ 1648 MO_max_Ladedruck 0;
BA_ "GenSigSendType" SG_ 1648 MO_NMAX_Schaltanzeige 3;
BA_ "GenSigSwitchedByIgnition" SG_ 1648 MO_NMAX_Schaltanzeige 0;
BA_ "GenSigSendType" SG_ 1648 MO_obere_Drehzahlgrenze 0;
BA_ "GenSigSwitchedByIgnition" SG_ 1648 MO_obere_Drehzahlgrenze 0;
BA_ "GenSigSendType" SG_ 1648 MO_StartStopp_PopUp 3;
BA_ "GenSigSwitchedByIgnition" SG_ 1648 MO_StartStopp_PopUp 0;
BA_ "GenSigSendType" SG_ 1648 MO_Zylabsch_Texte 0;
BA_ "GenSigSwitchedByIgnition" SG_ 1648 MO_Zylabsch_Texte 0;
BA_ "GenSigSendType" SG_ 1648 MO_Zylabsch_Texte_02 3;
BA_ "GenSigSwitchedByIgnition" SG_ 1648 MO_Zylabsch_Texte_02 0;
BA_ "GenSigSendType" SG_ 289 MO_Entkopplung_Sollschlupf 0;
BA_ "GenSigStartValue" SG_ 289 MO_Entkopplung_Sollschlupf 126;
BA_ "GenSigSwitchedByIgnition" SG_ 289 MO_Entkopplung_Sollschlupf 0;
BA_ "GenSigSendType" SG_ 289 MO_Fahrpedalgradient 0;
BA_ "GenSigSwitchedByIgnition" SG_ 289 MO_Fahrpedalgradient 0;
BA_ "Fehlerwert" SG_ 289 MO_Fahrpedalgradient 255;
BA_ "GenSigSendType" SG_ 289 MO_Fahrpedalrohwert_01 0;
BA_ "GenSigSwitchedByIgnition" SG_ 289 MO_Fahrpedalrohwert_01 0;
BA_ "Fehlerwert" SG_ 289 MO_Fahrpedalrohwert_01 255;
BA_ "GenSigSendType" SG_ 289 MO_Moment_im_Leerlauf 0;
BA_ "GenSigSwitchedByIgnition" SG_ 289 MO_Moment_im_Leerlauf 0;
BA_ "GenSigSendType" SG_ 289 MO_QBit_Fahrpedalwerte_01 0;
BA_ "GenSigStartValue" SG_ 289 MO_QBit_Fahrpedalwerte_01 1;
BA_ "GenSigSwitchedByIgnition" SG_ 289 MO_QBit_Fahrpedalwerte_01 0;
BA_ "GenSigSendType" SG_ 289 MO_rel_Saugrohrdruck 0;
BA_ "GenSigSwitchedByIgnition" SG_ 289 MO_rel_Saugrohrdruck 0;
BA_ "Fehlerwert" SG_ 289 MO_rel_Saugrohrdruck 63;
BA_ "GenSigSendType" SG_ 289 MO_rel_Saugrohrdruck_gem_err 0;
BA_ "GenSigSwitchedByIgnition" SG_ 289 MO_rel_Saugrohrdruck_gem_err 0;
BA_ "GenSigSendType" SG_ 289 MO_Schubabschaltung 0;
BA_ "GenSigSwitchedByIgnition" SG_ 289 MO_Schubabschaltung 0;
BA_ "GenSigSendType" SG_ 289 MO_Sig_Fahrpedalgradient 0;
BA_ "GenSigSwitchedByIgnition" SG_ 289 MO_Sig_Fahrpedalgradient 0;
BA_ "GenSigSendType" SG_ 289 MO_Solldrehz_Leerlauf 0;
BA_ "GenSigSwitchedByIgnition" SG_ 289 MO_Solldrehz_Leerlauf 0;
BA_ "GenSigSendType" SG_ 289 MO_StartStopp_StoppVorbereitung 0;
BA_ "GenSigSwitchedByIgnition" SG_ 289 MO_StartStopp_StoppVorbereitung 0;
BA_ "GenSigSendType" SG_ 289 MO_temporaere_Fahrerabwesenheit 0;
BA_ "GenSigSwitchedByIgnition" SG_ 289 MO_temporaere_Fahrerabwesenheit 0;
BA_ "GenSigSendType" SG_ 289 Motor_20_BZ 0;
BA_ "GenSigFuncType" SG_ 289 Motor_20_BZ 1;
BA_ "GenSigSwitchedByIgnition" SG_ 289 Motor_20_BZ 0;
BA_ "GenSigSendType" SG_ 289 Motor_20_CRC 0;
BA_ "GenSigFuncType" SG_ 289 Motor_20_CRC 2;
BA_ "GenSigSwitchedByIgnition" SG_ 289 Motor_20_CRC 0;
BA_ "GenSigSendType" SG_ 289 TSK_a_Soll_gradientenbegrenzt 0;
BA_ "GenSigStartValue" SG_ 289 TSK_a_Soll_gradientenbegrenzt 127;
BA_ "GenSigSwitchedByIgnition" SG_ 289 TSK_a_Soll_gradientenbegrenzt 0;
BA_ "GenSigSendType" SG_ 1423 FSA_Fehlerpfade_Initialisieren 0;
BA_ "GenSigSwitchedByIgnition" SG_ 1423 FSA_Fehlerpfade_Initialisieren 0;
BA_ "GenSigSendType" SG_ 1423 MO_FSA_Sensorheizung 0;
BA_ "GenSigSwitchedByIgnition" SG_ 1423 MO_FSA_Sensorheizung 0;
BA_ "GenSigSendType" SG_ 1423 MO_Getriebe_Oelalterung 0;
BA_ "GenSigSwitchedByIgnition" SG_ 1423 MO_Getriebe_Oelalterung 0;
BA_ "GenSigSendType" SG_ 1423 MO_ITM_Status 0;
BA_ "GenSigStartValue" SG_ 1423 MO_ITM_Status 14;
BA_ "GenSigSwitchedByIgnition" SG_ 1423 MO_ITM_Status 0;
BA_ "Fehlerwert" SG_ 1423 MO_ITM_Status 15;
BA_ "GenSigSendType" SG_ 1423 MO_KJS_LLK_Pos_Summe 0;
BA_ "GenSigStartValue" SG_ 1423 MO_KJS_LLK_Pos_Summe 14;
BA_ "GenSigSwitchedByIgnition" SG_ 1423 MO_KJS_LLK_Pos_Summe 0;
BA_ "GenSigSendType" SG_ 1423 MO_Kuehlmittel_Temp_Rohwert 0;
BA_ "GenSigStartValue" SG_ 1423 MO_Kuehlmittel_Temp_Rohwert 254;
BA_ "GenSigSwitchedByIgnition" SG_ 1423 MO_Kuehlmittel_Temp_Rohwert 0;
BA_ "Fehlerwert" SG_ 1423 MO_Kuehlmittel_Temp_Rohwert 255;
BA_ "GenSigSendType" SG_ 1423 MO_MMTR_Status 0;
BA_ "GenSigStartValue" SG_ 1423 MO_MMTR_Status 14;
BA_ "GenSigSwitchedByIgnition" SG_ 1423 MO_MMTR_Status 0;
BA_ "Fehlerwert" SG_ 1423 MO_MMTR_Status 15;
BA_ "GenSigSendType" SG_ 1423 MO_Oel_Temp_Radsatz 0;
BA_ "GenSigStartValue" SG_ 1423 MO_Oel_Temp_Radsatz 254;
BA_ "GenSigSwitchedByIgnition" SG_ 1423 MO_Oel_Temp_Radsatz 0;
BA_ "Fehlerwert" SG_ 1423 MO_Oel_Temp_Radsatz 255;
BA_ "GenSigSendType" SG_ 1423 MO_SABody_PosLe 0;
BA_ "GenSigSwitchedByIgnition" SG_ 1423 MO_SABody_PosLe 0;
BA_ "GenSigSendType" SG_ 1423 MO_SABody_PosRi 0;
BA_ "GenSigSwitchedByIgnition" SG_ 1423 MO_SABody_PosRi 0;
BA_ "GenSigSendType" SG_ 1423 MO_Tankdruck 0;
BA_ "GenSigStartValue" SG_ 1423 MO_Tankdruck 254;
BA_ "GenSigSwitchedByIgnition" SG_ 1423 MO_Tankdruck 0;
BA_ "Fehlerwert" SG_ 1423 MO_Tankdruck 255;
BA_ "GenSigSendType" SG_ 967 MO_E_Mode 0;
BA_ "GenSigSwitchedByIgnition" SG_ 967 MO_E_Mode 0;
BA_ "GenSigSendType" SG_ 967 MO_E_Texte 0;
BA_ "GenSigSwitchedByIgnition" SG_ 967 MO_E_Texte 0;
BA_ "GenSigSendType" SG_ 967 MO_E_Warnungen 0;
BA_ "GenSigSwitchedByIgnition" SG_ 967 MO_E_Warnungen 0;
BA_ "GenSigSendType" SG_ 967 MO_EFLEX_Lampe 0;
BA_ "GenSigSwitchedByIgnition" SG_ 967 MO_EFLEX_Lampe 0;
BA_ "GenSigSendType" SG_ 967 MO_Heissleuchte 0;
BA_ "GenSigSwitchedByIgnition" SG_ 967 MO_Heissleuchte 0;
BA_ "GenSigSendType" SG_ 967 MO_ITM_Warnung_Pumpe 0;
BA_ "GenSigSwitchedByIgnition" SG_ 967 MO_ITM_Warnung_Pumpe 0;
BA_ "GenSigSendType" SG_ 967 MO_KJS_nicht_bereit 0;
BA_ "GenSigSwitchedByIgnition" SG_ 967 MO_KJS_nicht_bereit 0;
BA_ "Fehlerwert" SG_ 967 MO_KJS_nicht_bereit 1;
BA_ "GenSigStartValue" SG_ 967 MO_Kuehlerluefter_1 126;
BA_ "GenSigSwitchedByIgnition" SG_ 967 MO_Kuehlerluefter_1 0;
BA_ "Fehlerwert" SG_ 967 MO_Kuehlerluefter_1 127;
BA_ "GenSigStartValue" SG_ 967 MO_Kuehlerluefter_2 126;
BA_ "GenSigSwitchedByIgnition" SG_ 967 MO_Kuehlerluefter_2 0;
BA_ "Fehlerwert" SG_ 967 MO_Kuehlerluefter_2 127;
BA_ "GenSigSendType" SG_ 967 MO_Kuehlerluefter_MUX 0;
BA_ "GenSigSwitchedByIgnition" SG_ 967 MO_Kuehlerluefter_MUX 0;
BA_ "GenSigSendType" SG_ 967 MO_OBD2_Lampe 0;
BA_ "GenSigSwitchedByIgnition" SG_ 967 MO_OBD2_Lampe 0;
BA_ "GenSigSendType" SG_ 967 MO_Oelwarnung_max 0;
BA_ "GenSigSwitchedByIgnition" SG_ 967 MO_Oelwarnung_max 0;
BA_ "GenSigSendType" SG_ 967 MO_Partikel_Lampe 0;
BA_ "GenSigSwitchedByIgnition" SG_ 967 MO_Partikel_Lampe 0;
BA_ "GenSigSendType" SG_ 967 MO_RedFahrleistung_Lampe 0;
BA_ "GenSigSwitchedByIgnition" SG_ 967 MO_RedFahrleistung_Lampe 0;
BA_ "GenSigSendType" SG_ 967 MO_Systemlampe 0;
BA_ "GenSigSwitchedByIgnition" SG_ 967 MO_Systemlampe 0;
BA_ "GenSigSendType" SG_ 967 MO_Tankdeckel_Lampe 0;
BA_ "GenSigSwitchedByIgnition" SG_ 967 MO_Tankdeckel_Lampe 0;
BA_ "GenSigSendType" SG_ 967 MO_Text_Motorstart 0;
BA_ "GenSigSwitchedByIgnition" SG_ 967 MO_Text_Motorstart 0;
BA_ "GenSigSendType" SG_ 967 MO_Text_Partikelfil_Reg 0;
BA_ "GenSigSwitchedByIgnition" SG_ 967 MO_Text_Partikelfil_Reg 0;
BA_ "GenSigSendType" SG_ 967 MO_Text_Tankdeckelwarn 0;
BA_ "GenSigSwitchedByIgnition" SG_ 967 MO_Text_Tankdeckelwarn 0;
BA_ "GenSigSendType" SG_ 967 MO_Vorglueh_Lampe 0;
BA_ "GenSigSwitchedByIgnition" SG_ 967 MO_Vorglueh_Lampe 0;
BA_ "GenSigSendType" SG_ 967 MO_Zustand_HWP 0;
BA_ "GenSigStartValue" SG_ 967 MO_Zustand_HWP 1;
BA_ "GenSigSwitchedByIgnition" SG_ 967 MO_Zustand_HWP 0;
BA_ "GenSigSendType" SG_ 967 OLEV_Oelstand_nicht_vorhanden 0;
BA_ "GenSigSwitchedByIgnition" SG_ 967 OLEV_Oelstand_nicht_vorhanden 0;
BA_ "GenSigSendType" SG_ 967 OLEV_Systemstoerung 0;
BA_ "GenSigSwitchedByIgnition" SG_ 967 OLEV_Systemstoerung 0;
BA_ "GenSigSendType" SG_ 967 WIV_Anzeige_aktiv 0;
BA_ "GenSigSwitchedByIgnition" SG_ 967 WIV_Anzeige_aktiv 0;
BA_ "GenSigSendType" SG_ 967 WIV_laufender_Motor 0;
BA_ "GenSigSwitchedByIgnition" SG_ 967 WIV_laufender_Motor 0;
BA_ "GenSigSendType" SG_ 967 WIV_nachfuellanzeige_ein 0;
BA_ "GenSigSwitchedByIgnition" SG_ 967 WIV_nachfuellanzeige_ein 0;
BA_ "GenSigSendType" SG_ 967 WIV_nicht_betriebswarm 0;
BA_ "GenSigSwitchedByIgnition" SG_ 967 WIV_nicht_betriebswarm 0;
BA_ "GenSigSendType" SG_ 967 WIV_Oeldr_Warn_Motor 0;
BA_ "GenSigSwitchedByIgnition" SG_ 967 WIV_Oeldr_Warn_Motor 0;
BA_ "GenSigSendType" SG_ 967 WIV_Oeldyn_avl 0;
BA_ "GenSigSwitchedByIgnition" SG_ 967 WIV_Oeldyn_avl 0;
BA_ "GenSigSendType" SG_ 967 WIV_Oelmenge 0;
BA_ "GenSigSwitchedByIgnition" SG_ 967 WIV_Oelmenge 0;
BA_ "GenSigSendType" SG_ 967 WIV_Oelmin_Warn 0;
BA_ "GenSigSwitchedByIgnition" SG_ 967 WIV_Oelmin_Warn 0;
BA_ "GenSigSendType" SG_ 967 WIV_Oelstand 0;
BA_ "GenSigSwitchedByIgnition" SG_ 967 WIV_Oelstand 0;
BA_ "GenSigSendType" SG_ 967 WIV_Oelstand_nicht_vorhanden 0;
BA_ "GenSigSwitchedByIgnition" SG_ 967 WIV_Oelstand_nicht_vorhanden 0;
BA_ "GenSigSendType" SG_ 967 WIV_Oelsystem_aktiv 0;
BA_ "GenSigSwitchedByIgnition" SG_ 967 WIV_Oelsystem_aktiv 0;
BA_ "GenSigSendType" SG_ 967 WIV_Schieflage 0;
BA_ "GenSigSwitchedByIgnition" SG_ 967 WIV_Schieflage 0;
BA_ "GenSigSendType" SG_ 967 WIV_Sensorfehler 0;
BA_ "GenSigSwitchedByIgnition" SG_ 967 WIV_Sensorfehler 0;
BA_ "GenSigSendType" SG_ 967 WIV_Ueberfuell_deaktiv 0;
BA_ "GenSigSwitchedByIgnition" SG_ 967 WIV_Ueberfuell_deaktiv 0;
BA_ "GenSigSendType" SG_ 967 WIV_Ueberfuell_Warn 0;
BA_ "GenSigSwitchedByIgnition" SG_ 967 WIV_Ueberfuell_Warn 0;
BA_ "GenSigSendType" SG_ 967 WIV_Unterfuell_Warn 0;
BA_ "GenSigSwitchedByIgnition" SG_ 967 WIV_Unterfuell_Warn 0;
BA_ "GenSigSendType" SG_ 340 MO_Drehzahl_VM 0;
BA_ "GenSigSwitchedByIgnition" SG_ 340 MO_Drehzahl_VM 0;
BA_ "GenSigSendType" SG_ 340 MO_Fehlerstatus_Antrieb_FDR 0;
BA_ "GenSigSendType" SG_ 340 MO_IstMoment_VKM 0;
BA_ "GenSigStartValue" SG_ 340 MO_IstMoment_VKM 1022;
BA_ "GenSigSwitchedByIgnition" SG_ 340 MO_IstMoment_VKM 0;
BA_ "GenSigSendType" SG_ 340 MO_Mom_Begr_Schalt 0;
BA_ "GenSigStartValue" SG_ 340 MO_Mom_Begr_Schalt 1022;
BA_ "GenSigSwitchedByIgnition" SG_ 340 MO_Mom_Begr_Schalt 0;
BA_ "GenSigSendType" SG_ 340 MO_Mom_Begr_Schalt_Min 0;
BA_ "GenSigStartValue" SG_ 340 MO_Mom_Begr_Schalt_Min 1022;
BA_ "GenSigSwitchedByIgnition" SG_ 340 MO_Mom_Begr_Schalt_Min 0;
BA_ "GenSigSendType" SG_ 340 MO_Primaerachse_Anforderung 0;
BA_ "GenSigSwitchedByIgnition" SG_ 340 MO_Primaerachse_Anforderung 0;
BA_ "GenSigSendType" SG_ 340 Motor_28_BZ 0;
BA_ "GenSigFuncType" SG_ 340 Motor_28_BZ 1;
BA_ "GenSigSwitchedByIgnition" SG_ 340 Motor_28_BZ 0;
BA_ "GenSigSendType" SG_ 340 Motor_28_CRC 0;
BA_ "GenSigFuncType" SG_ 340 Motor_28_CRC 2;
BA_ "GenSigSwitchedByIgnition" SG_ 340 Motor_28_CRC 0;
BA_ "GenSigSendType" SG_ 283 MO_AIAD_MaxLeistung 0;
BA_ "GenSigStartValue" SG_ 283 MO_AIAD_MaxLeistung 255;
BA_ "GenSigSwitchedByIgnition" SG_ 283 MO_AIAD_MaxLeistung 0;
BA_ "GenSigSendType" SG_ 283 MO_EBoost_verf_praed 0;
BA_ "GenSigSwitchedByIgnition" SG_ 283 MO_EBoost_verf_praed 0;
BA_ "GenSigSendType" SG_ 283 MO_eLaunch_verf 0;
BA_ "GenSigSwitchedByIgnition" SG_ 283 MO_eLaunch_verf 0;
BA_ "GenSigSendType" SG_ 283 MO_Fahrbereitschaft 3;
BA_ "GenSigSwitchedByIgnition" SG_ 283 MO_Fahrbereitschaft 0;
BA_ "GenSigSendType" SG_ 283 MO_Freilauf_Info 0;
BA_ "GenSigSwitchedByIgnition" SG_ 283 MO_Freilauf_Info 0;
BA_ "GenSigSendType" SG_ 283 MO_Freilauf_Status 3;
BA_ "GenSigSwitchedByIgnition" SG_ 283 MO_Freilauf_Status 0;
BA_ "Fehlerwert" SG_ 283 MO_Freilauf_Status 7;
BA_ "GenSigSendType" SG_ 283 MO_Heckspoiler_Anf 3;
BA_ "GenSigSwitchedByIgnition" SG_ 283 MO_Heckspoiler_Anf 0;
BA_ "GenSigSendType" SG_ 283 MO_Krit_Heckobjekt 0;
BA_ "GenSigSwitchedByIgnition" SG_ 283 MO_Krit_Heckobjekt 0;
BA_ "Fehlerwert" SG_ 283 MO_Krit_Heckobjekt 7;
BA_ "GenSigSendType" SG_ 283 MO_NGS_Gangpos 0;
BA_ "GenSigSwitchedByIgnition" SG_ 283 MO_NGS_Gangpos 0;
BA_ "Fehlerwert" SG_ 283 MO_NGS_Gangpos 7;
BA_ "GenSigSendType" SG_ 283 MO_Parken_WFS_Status 0;
BA_ "GenSigSwitchedByIgnition" SG_ 283 MO_Parken_WFS_Status 0;
BA_ "GenSigSendType" SG_ 283 MO_Positionierung_aktiv 0;
BA_ "GenSigSwitchedByIgnition" SG_ 283 MO_Positionierung_aktiv 0;
BA_ "GenSigSendType" SG_ 283 MO_Rennstart_verf 3;
BA_ "GenSigSwitchedByIgnition" SG_ 283 MO_Rennstart_verf 0;
BA_ "GenSigSendType" SG_ 283 MO_Status_Katheizen 0;
BA_ "GenSigSwitchedByIgnition" SG_ 283 MO_Status_Katheizen 0;
BA_ "GenSigSendType" SG_ 283 MO_Status_MIN_Wunschdrehzahl 3;
BA_ "GenSigSwitchedByIgnition" SG_ 283 MO_Status_MIN_Wunschdrehzahl 0;
BA_ "GenSigSendType" SG_ 1601 MO_Ansaugsystem 0;
BA_ "GenSigFuncType" SG_ 1601 MO_Ansaugsystem 8;
BA_ "GenSigSwitchedByIgnition" SG_ 1601 MO_Ansaugsystem 0;
BA_ "GenSigSendType" SG_ 1601 MO_Anzahl_Zyl 0;
BA_ "GenSigFuncType" SG_ 1601 MO_Anzahl_Zyl 8;
BA_ "GenSigSwitchedByIgnition" SG_ 1601 MO_Anzahl_Zyl 0;
BA_ "GenSigSendType" SG_ 1601 MO_Anzeige_StSt_gueltig 0;
BA_ "GenSigSwitchedByIgnition" SG_ 1601 MO_Anzeige_StSt_gueltig 0;
BA_ "GenSigSendType" SG_ 1601 MO_Code 0;
BA_ "GenSigSwitchedByIgnition" SG_ 1601 MO_Code 0;
BA_ "GenSigSendType" SG_ 1601 MO_DPF_verbaut 0;
BA_ "GenSigFuncType" SG_ 1601 MO_DPF_verbaut 8;
BA_ "GenSigSwitchedByIgnition" SG_ 1601 MO_DPF_verbaut 0;
BA_ "GenSigSendType" SG_ 1601 MO_Faktor_Momente_02 0;
BA_ "GenSigFuncType" SG_ 1601 MO_Faktor_Momente_02 8;
BA_ "GenSigSwitchedByIgnition" SG_ 1601 MO_Faktor_Momente_02 0;
BA_ "GenSigSendType" SG_ 1601 MO_Getriebe_Code 0;
BA_ "GenSigSwitchedByIgnition" SG_ 1601 MO_Getriebe_Code 0;
BA_ "GenSigSendType" SG_ 1601 MO_Hubraum 0;
BA_ "GenSigFuncType" SG_ 1601 MO_Hubraum 8;
BA_ "GenSigSwitchedByIgnition" SG_ 1601 MO_Hubraum 0;
BA_ "GenSigSendType" SG_ 1601 MO_Hybridfahrzeug 0;
BA_ "GenSigFuncType" SG_ 1601 MO_Hybridfahrzeug 8;
BA_ "GenSigSwitchedByIgnition" SG_ 1601 MO_Hybridfahrzeug 0;
BA_ "GenSigSendType" SG_ 1601 MO_Kraftstoffart 0;
BA_ "GenSigFuncType" SG_ 1601 MO_Kraftstoffart 8;
BA_ "GenSigSwitchedByIgnition" SG_ 1601 MO_Kraftstoffart 0;
BA_ "GenSigSendType" SG_ 1601 MO_Leistung 0;
BA_ "GenSigSwitchedByIgnition" SG_ 1601 MO_Leistung 0;
BA_ "GenSigSendType" SG_ 1601 MO_OBD_Typ 0;
BA_ "GenSigSwitchedByIgnition" SG_ 1601 MO_OBD_Typ 0;
BA_ "GenSigSendType" SG_ 1601 MO_StartStopp_Codiert 0;
BA_ "GenSigFuncType" SG_ 1601 MO_StartStopp_Codiert 8;
BA_ "GenSigSwitchedByIgnition" SG_ 1601 MO_StartStopp_Codiert 0;
BA_ "GenSigSendType" SG_ 1601 Motor_Code_01_BZ 0;
BA_ "GenSigFuncType" SG_ 1601 Motor_Code_01_BZ 1;
BA_ "GenSigSwitchedByIgnition" SG_ 1601 Motor_Code_01_BZ 0;
BA_ "GenSigSendType" SG_ 1601 Motor_Code_01_CRC 0;
BA_ "GenSigFuncType" SG_ 1601 Motor_Code_01_CRC 2;
BA_ "GenSigSwitchedByIgnition" SG_ 1601 Motor_Code_01_CRC 0;
BA_ "GenSigSendType" SG_ 1601 TSK_Codierung 0;
BA_ "GenSigStartValue" SG_ 1601 TSK_Codierung 7;
BA_ "GenSigSwitchedByIgnition" SG_ 1601 TSK_Codierung 0;
BA_ "GenSigSendType" SG_ 394 MO_Ablaufstatus 0;
BA_ "GenSigSwitchedByIgnition" SG_ 394 MO_Ablaufstatus 0;
BA_ "Fehlerwert" SG_ 394 MO_Ablaufstatus 15;
BA_ "GenSigSendType" SG_ 394 MO_Ablaufstrg_Betriebszustand 0;
BA_ "GenSigSwitchedByIgnition" SG_ 394 MO_Ablaufstrg_Betriebszustand 0;
BA_ "Fehlerwert" SG_ 394 MO_Ablaufstrg_Betriebszustand 7;
BA_ "GenSigSendType" SG_ 394 MO_Ablaufstrg_Kraftschluss2_Ist 0;
BA_ "GenSigSwitchedByIgnition" SG_ 394 MO_Ablaufstrg_Kraftschluss2_Ist 0;
BA_ "GenSigSendType" SG_ 394 MO_Ablaufstrg_Kraftschluss2_Ziel 0;
BA_ "GenSigSwitchedByIgnition" SG_ 394 MO_Ablaufstrg_Kraftschluss2_Ziel 0;
BA_ "GenSigSendType" SG_ 394 MO_Ablaufstrg_Kraftschluss_Ist 0;
BA_ "GenSigSwitchedByIgnition" SG_ 394 MO_Ablaufstrg_Kraftschluss_Ist 0;
BA_ "GenSigSendType" SG_ 394 MO_Ablaufstrg_Kraftschluss_Ziel 0;
BA_ "GenSigSwitchedByIgnition" SG_ 394 MO_Ablaufstrg_Kraftschluss_Ziel 0;
BA_ "GenSigSendType" SG_ 394 MO_Ablaufstrg_Zustand_K0_Ist 0;
BA_ "GenSigSwitchedByIgnition" SG_ 394 MO_Ablaufstrg_Zustand_K0_Ist 0;
BA_ "GenSigSendType" SG_ 394 MO_Ablaufstrg_Zustand_K0_Ziel 0;
BA_ "GenSigSwitchedByIgnition" SG_ 394 MO_Ablaufstrg_Zustand_K0_Ziel 0;
BA_ "GenSigSendType" SG_ 394 MO_Ablaufstrg_Zustand_VKM_Ist 0;
BA_ "GenSigSwitchedByIgnition" SG_ 394 MO_Ablaufstrg_Zustand_VKM_Ist 0;
BA_ "GenSigSendType" SG_ 394 MO_Ablaufstrg_Zustand_VKM_Ziel 0;
BA_ "GenSigSwitchedByIgnition" SG_ 394 MO_Ablaufstrg_Zustand_VKM_Ziel 0;
BA_ "GenSigSendType" SG_ 394 MO_Abstellposition_02 0;
BA_ "GenSigStartValue" SG_ 394 MO_Abstellposition_02 255;
BA_ "GenSigSwitchedByIgnition" SG_ 394 MO_Abstellposition_02 0;
BA_ "GenSigSendType" SG_ 394 MO_Auth_Aufforderung_WFS 0;
BA_ "GenSigSwitchedByIgnition" SG_ 394 MO_Auth_Aufforderung_WFS 0;
BA_ "GenSigSendType" SG_ 394 MO_HYB_Adaption_aktiv 0;
BA_ "GenSigSendType" SG_ 394 MO_HYB_E_Faktor 0;
BA_ "GenSigSwitchedByIgnition" SG_ 394 MO_HYB_E_Faktor 0;
BA_ "GenSigSendType" SG_ 394 MO_HYB_EMode_Info 0;
BA_ "GenSigSwitchedByIgnition" SG_ 394 MO_HYB_EMode_Info 0;
BA_ "GenSigSendType" SG_ 394 MO_HYB_LowSpeedModus 0;
BA_ "GenSigSwitchedByIgnition" SG_ 394 MO_HYB_LowSpeedModus 0;
BA_ "GenSigSendType" SG_ 394 MO_HYB_Stoppmodus 0;
BA_ "GenSigSendType" SG_ 394 MO_Mom_Freiheit_Sekundaerachse 0;
BA_ "GenSigSwitchedByIgnition" SG_ 394 MO_Mom_Freiheit_Sekundaerachse 0;
BA_ "GenSigSendType" SG_ 394 MO_Nachlaufzeit_Kuehlerluefter 0;
BA_ "GenSigSwitchedByIgnition" SG_ 394 MO_Nachlaufzeit_Kuehlerluefter 0;
BA_ "GenSigSendType" SG_ 394 MO_Start_Art 3;
BA_ "GenSigSwitchedByIgnition" SG_ 394 MO_Start_Art 0;
BA_ "GenSigSendType" SG_ 394 MO_Start_Dynamik 0;
BA_ "GenSigSwitchedByIgnition" SG_ 394 MO_Start_Dynamik 0;
BA_ "GenSigSendType" SG_ 394 MO_Tankklappensteuerung 3;
BA_ "GenSigSwitchedByIgnition" SG_ 394 MO_Tankklappensteuerung 0;
BA_ "GenSigSendType" SG_ 1156 ND_GDOP 0;
BA_ "GenSigStartValue" SG_ 1156 ND_GDOP 1022;
BA_ "GenSigSwitchedByIgnition" SG_ 1156 ND_GDOP 0;
BA_ "Fehlerwert" SG_ 1156 ND_GDOP 1023;
BA_ "GenSigSendType" SG_ 1156 ND_HDOP 0;
BA_ "GenSigStartValue" SG_ 1156 ND_HDOP 1022;
BA_ "GenSigSwitchedByIgnition" SG_ 1156 ND_HDOP 0;
BA_ "Fehlerwert" SG_ 1156 ND_HDOP 1023;
BA_ "GenSigSendType" SG_ 1156 ND_Heading 0;
BA_ "GenSigStartValue" SG_ 1156 ND_Heading 4094;
BA_ "GenSigSwitchedByIgnition" SG_ 1156 ND_Heading 0;
BA_ "Fehlerwert" SG_ 1156 ND_Heading 4095;
BA_ "GenSigSendType" SG_ 1156 ND_Init 0;
BA_ "GenSigSwitchedByIgnition" SG_ 1156 ND_Init 0;
BA_ "GenSigSendType" SG_ 1156 ND_PDOP 0;
BA_ "GenSigStartValue" SG_ 1156 ND_PDOP 1022;
BA_ "GenSigSwitchedByIgnition" SG_ 1156 ND_PDOP 0;
BA_ "Fehlerwert" SG_ 1156 ND_PDOP 1023;
BA_ "GenSigSendType" SG_ 1156 ND_TDOP 0;
BA_ "GenSigStartValue" SG_ 1156 ND_TDOP 1022;
BA_ "GenSigSwitchedByIgnition" SG_ 1156 ND_TDOP 0;
BA_ "Fehlerwert" SG_ 1156 ND_TDOP 1023;
BA_ "GenSigSendType" SG_ 1156 ND_VDOP 0;
BA_ "GenSigStartValue" SG_ 1156 ND_VDOP 1022;
BA_ "GenSigSwitchedByIgnition" SG_ 1156 ND_VDOP 0;
BA_ "Fehlerwert" SG_ 1156 ND_VDOP 1023;
BA_ "GenSigSendType" SG_ 1157 ND_SatInUse 0;
BA_ "GenSigStartValue" SG_ 1157 ND_SatInUse 30;
BA_ "GenSigSwitchedByIgnition" SG_ 1157 ND_SatInUse 0;
BA_ "Fehlerwert" SG_ 1157 ND_SatInUse 31;
BA_ "GenSigSendType" SG_ 1157 ND_SatInView 0;
BA_ "GenSigStartValue" SG_ 1157 ND_SatInView 30;
BA_ "GenSigSwitchedByIgnition" SG_ 1157 ND_SatInView 0;
BA_ "Fehlerwert" SG_ 1157 ND_SatInView 31;
BA_ "GenSigSendType" SG_ 1157 ND_UTC 0;
BA_ "GenSigSwitchedByIgnition" SG_ 1157 ND_UTC 0;
BA_ "GenSigSendType" SG_ 1157 NP_Altitude 0;
BA_ "GenSigStartValue" SG_ 1157 NP_Altitude 4094;
BA_ "GenSigSwitchedByIgnition" SG_ 1157 NP_Altitude 0;
BA_ "Fehlerwert" SG_ 1157 NP_Altitude 4095;
BA_ "GenSigSendType" SG_ 1157 POS_Guete_horizontal 0;
BA_ "GenSigStartValue" SG_ 1157 POS_Guete_horizontal 126;
BA_ "GenSigSwitchedByIgnition" SG_ 1157 POS_Guete_horizontal 0;
BA_ "Fehlerwert" SG_ 1157 POS_Guete_horizontal 127;
BA_ "GenSigSendType" SG_ 1157 POS_Guete_horizontal_verfuegbar 0;
BA_ "GenSigSwitchedByIgnition" SG_ 1157 POS_Guete_horizontal_verfuegbar 0;
BA_ "GenSigSendType" SG_ 2527679512 ND_Fuelstation_detected 0;
BA_ "GenSigStartValue" SG_ 2527679512 ND_Fuelstation_detected 3;
BA_ "GenSigSwitchedByIgnition" SG_ 2527679512 ND_Fuelstation_detected 0;
BA_ "GenSigSendType" SG_ 2527679512 ND_NrSameMeasure 0;
BA_ "GenSigSwitchedByIgnition" SG_ 2527679512 ND_NrSameMeasure 0;
BA_ "GenSigSendType" SG_ 2527679512 ND_RecDelay 0;
BA_ "GenSigStartValue" SG_ 2527679512 ND_RecDelay 4094;
BA_ "GenSigSwitchedByIgnition" SG_ 2527679512 ND_RecDelay 0;
BA_ "Fehlerwert" SG_ 2527679512 ND_RecDelay 4095;
BA_ "GenSigSendType" SG_ 2527679512 ND_RouteType 0;
BA_ "GenSigSwitchedByIgnition" SG_ 2527679512 ND_RouteType 0;
BA_ "GenSigSendType" SG_ 2527679512 ND_SendDelay 0;
BA_ "GenSigStartValue" SG_ 2527679512 ND_SendDelay 4094;
BA_ "GenSigSwitchedByIgnition" SG_ 2527679512 ND_SendDelay 0;
BA_ "Fehlerwert" SG_ 2527679512 ND_SendDelay 4095;
BA_ "GenSigSendType" SG_ 2527679512 ND_TimeOffset 0;
BA_ "GenSigSwitchedByIgnition" SG_ 2527679512 ND_TimeOffset 0;
BA_ "GenSigSendType" SG_ 2527679512 ND_TimeToDestination 0;
BA_ "GenSigStartValue" SG_ 2527679512 ND_TimeToDestination 511;
BA_ "GenSigSwitchedByIgnition" SG_ 2527679512 ND_TimeToDestination 0;
BA_ "Fehlerwert" SG_ 2527679512 ND_TimeToDestination 510;
BA_ "GenSigSendType" SG_ 2527679512 ND_Timezone_DaylightSavingOffset 0;
BA_ "GenSigSwitchedByIgnition" SG_ 2527679512 ND_Timezone_DaylightSavingOffset 0;
BA_ "GenSigSendType" SG_ 2527679512 ND_Timezone_Offset 0;
BA_ "GenSigStartValue" SG_ 2527679512 ND_Timezone_Offset 14;
BA_ "GenSigSwitchedByIgnition" SG_ 2527679512 ND_Timezone_Offset 0;
BA_ "Fehlerwert" SG_ 2527679512 ND_Timezone_Offset 15;
BA_ "GenSigSendType" SG_ 2527679512 ND_Timezone_SignBit 0;
BA_ "GenSigSwitchedByIgnition" SG_ 2527679512 ND_Timezone_SignBit 0;
BA_ "GenSigSendType" SG_ 2527679512 ND_Timezone_Validity 0;
BA_ "GenSigSwitchedByIgnition" SG_ 2527679512 ND_Timezone_Validity 0;
BA_ "GenSigSendType" SG_ 2527679512 ND_Velocity 0;
BA_ "GenSigStartValue" SG_ 2527679512 ND_Velocity 1022;
BA_ "GenSigSwitchedByIgnition" SG_ 2527679512 ND_Velocity 0;
BA_ "Fehlerwert" SG_ 2527679512 ND_Velocity 1023;
BA_ "GenSigSendType" SG_ 1158 NP_Fix 0;
BA_ "GenSigSwitchedByIgnition" SG_ 1158 NP_Fix 0;
BA_ "GenSigSendType" SG_ 1158 NP_LatDegree 0;
BA_ "GenSigStartValue" SG_ 1158 NP_LatDegree 134217726;
BA_ "GenSigSwitchedByIgnition" SG_ 1158 NP_LatDegree 0;
BA_ "Fehlerwert" SG_ 1158 NP_LatDegree 134217727;
BA_ "GenSigSendType" SG_ 1158 NP_LatDirection 0;
BA_ "GenSigStartValue" SG_ 1158 NP_LatDirection 1;
BA_ "GenSigSwitchedByIgnition" SG_ 1158 NP_LatDirection 0;
BA_ "GenSigSendType" SG_ 1158 NP_LongDegree 0;
BA_ "GenSigStartValue" SG_ 1158 NP_LongDegree 268435454;
BA_ "GenSigSwitchedByIgnition" SG_ 1158 NP_LongDegree 0;
BA_ "Fehlerwert" SG_ 1158 NP_LongDegree 268435455;
BA_ "GenSigSendType" SG_ 1158 NP_LongDirection 0;
BA_ "GenSigStartValue" SG_ 1158 NP_LongDirection 1;
BA_ "GenSigSwitchedByIgnition" SG_ 1158 NP_LongDirection 0;
BA_ "GenSigSendType" SG_ 1158 NP_Sat 0;
BA_ "GenSigStartValue" SG_ 1158 NP_Sat 30;
BA_ "GenSigSwitchedByIgnition" SG_ 1158 NP_Sat 0;
BA_ "Fehlerwert" SG_ 1158 NP_Sat 31;
BA_ "GenSigSwitchedByIgnition" SG_ 2589283496 POS_Heading 0;
BA_ "GenSigSwitchedByIgnition" SG_ 2589283496 POS_Heading_Trust 0;
BA_ "Fehlerwert" SG_ 2589283496 POS_Heading_Trust 3;
BA_ "GenSigSwitchedByIgnition" SG_ 2589283496 POS_Last_GPS_Sync 0;
BA_ "GenSigStartValue" SG_ 2589283496 POS_LatDegree 134217726;
BA_ "GenSigSwitchedByIgnition" SG_ 2589283496 POS_LatDegree 0;
BA_ "Fehlerwert" SG_ 2589283496 POS_LatDegree 134217727;
BA_ "GenSigSwitchedByIgnition" SG_ 2589283496 POS_LatDirection 0;
BA_ "GenSigStartValue" SG_ 2589283496 POS_LongDegree 268435454;
BA_ "GenSigSwitchedByIgnition" SG_ 2589283496 POS_LongDegree 0;
BA_ "Fehlerwert" SG_ 2589283496 POS_LongDegree 268435455;
BA_ "GenSigSwitchedByIgnition" SG_ 2589283496 POS_LongDirection 0;
BA_ "GenSigSendType" SG_ 2589283496 POS_MUX 0;
BA_ "GenSigStartValue" SG_ 2589283496 POS_MUX 3;
BA_ "GenSigSwitchedByIgnition" SG_ 2589283496 POS_MUX 0;
BA_ "GenSigSendType" SG_ 2589283496 POS_ODD_EVEN 0;
BA_ "GenSigSwitchedByIgnition" SG_ 2589283496 POS_ODD_EVEN 0;
BA_ "GenSigSwitchedByIgnition" SG_ 2589283496 POS_PosStati 0;
BA_ "GenSigSwitchedByIgnition" SG_ 2589283496 POS_UTC_REF 0;
BA_ "GenSigSendType" SG_ 2527679647 NFC_aktiv 0;
BA_ "GenSigSwitchedByIgnition" SG_ 2527679647 NFC_aktiv 0;
BA_ "GenSigSendType" SG_ 2527679647 NFC_ESM_aktivieren 0;
BA_ "GenSigSwitchedByIgnition" SG_ 2527679647 NFC_ESM_aktivieren 0;
BA_ "GenSigSendType" SG_ 2527679647 NFC_Front_Entr_Authorisiert 0;
BA_ "GenSigSwitchedByIgnition" SG_ 2527679647 NFC_Front_Entr_Authorisiert 0;
BA_ "GenSigSendType" SG_ 2527679647 NFC_Front_Verr_Authorisiert 0;
BA_ "GenSigSwitchedByIgnition" SG_ 2527679647 NFC_Front_Verr_Authorisiert 0;
BA_ "GenSigSendType" SG_ 2527679647 NFC_FT_Entriegelung_Authorisiert 0;
BA_ "GenSigSwitchedByIgnition" SG_ 2527679647 NFC_FT_Entriegelung_Authorisiert 0;
BA_ "GenSigSendType" SG_ 2527679647 NFC_FT_Verriegelung_Authorisiert 0;
BA_ "GenSigSwitchedByIgnition" SG_ 2527679647 NFC_FT_Verriegelung_Authorisiert 0;
BA_ "GenSigSendType" SG_ 2527679647 NFC_HD_Entriegelung_Authorisiert 0;
BA_ "GenSigSwitchedByIgnition" SG_ 2527679647 NFC_HD_Entriegelung_Authorisiert 0;
BA_ "GenSigSendType" SG_ 2527679647 NFC_HD_Verriegelung_Authorisiert 0;
BA_ "GenSigSwitchedByIgnition" SG_ 2527679647 NFC_HD_Verriegelung_Authorisiert 0;
BA_ "GenSigSendType" SG_ 2527679647 NFC_Laden_unterbrechen 0;
BA_ "GenSigSwitchedByIgnition" SG_ 2527679647 NFC_Laden_unterbrechen 0;
BA_ "GenSigSendType" SG_ 2527679647 Stellgliedtest_NFC 0;
BA_ "GenSigSwitchedByIgnition" SG_ 2527679647 Stellgliedtest_NFC 0;
BA_ "GenSigSendType" SG_ 2527679647 ZV_auf_NFC 0;
BA_ "GenSigSwitchedByIgnition" SG_ 2527679647 ZV_auf_NFC 0;
BA_ "GenSigSendType" SG_ 2527679647 ZV_zu_NFC 0;
BA_ "GenSigSwitchedByIgnition" SG_ 2527679647 ZV_zu_NFC 0;
BA_ "GenSigSendType" SG_ 1696 NV_Akt_Status_MMI 3;
BA_ "GenSigStartValue" SG_ 1696 NV_Akt_Status_MMI 3;
BA_ "GenSigSendType" SG_ 1696 NV_aktiv 3;
BA_ "GenSigSendType" SG_ 1696 NV_Akustik_deaktiviert_Icon 3;
BA_ "GenSigSendType" SG_ 1696 NV_Anf_Prefill 3;
BA_ "GenSigSendType" SG_ 1696 NV_AnforderungBildaufschaltung 3;
BA_ "GenSigSendType" SG_ 1696 NV_FAS_Fkt_Status 0;
BA_ "Fehlerwert" SG_ 1696 NV_FAS_Fkt_Status 3;
BA_ "GenSigSendType" SG_ 1696 NV_FGM_deaktiviert_Icon 3;
BA_ "GenSigSendType" SG_ 1696 NV_Gong 3;
BA_ "GenSigSendType" SG_ 1696 NV_HBA_Parameter 3;
BA_ "GenSigSendType" SG_ 1696 NV_Hinweise 3;
BA_ "GenSigSendType" SG_ 1696 NV_LED_Leiste 3;
BA_ "GenSigSendType" SG_ 1696 NV_Markierungslicht_links 3;
BA_ "GenSigSendType" SG_ 1696 NV_Markierungslicht_rechts 3;
BA_ "GenSigSendType" SG_ 1696 NV_Piktogramm_aktiv 3;
BA_ "GenSigSendType" SG_ 1696 NV_PreSense_Modus_System 3;
BA_ "GenSigSendType" SG_ 1696 NV_PreSense_Modus_Warnung 3;
BA_ "GenSigSendType" SG_ 1696 NV_PreSense_Status 3;
BA_ "GenSigSendType" SG_ 1696 NV_Symbol 3;
BA_ "GenSigSendType" SG_ 1696 NV_Symbol_Tierwarnung 3;
BA_ "GenSigSendType" SG_ 1696 NV_Texte 3;
BA_ "GenSigActiveRepetitions" SG_ 2600468494 NM_BCM1_CAB 3;
BA_ "GenSigSendType" SG_ 2600468494 NM_BCM1_CAB 4;
BA_ "GenSigFuncType" SG_ 2600468494 NM_BCM1_CAB 16;
BA_ "GenSigSwitchedByIgnition" SG_ 2600468494 NM_BCM1_CAB 0;
BA_ "GenSigSendType" SG_ 2600468494 NM_BCM1_Car_Wakeup 3;
BA_ "GenSigSwitchedByIgnition" SG_ 2600468494 NM_BCM1_Car_Wakeup 0;
BA_ "GenSigSwitchedByIgnition" SG_ 2600468494 NM_BCM1_CBV_AWB 0;
BA_ "GenSigSwitchedByIgnition" SG_ 2600468494 NM_BCM1_CBV_CRI 0;
BA_ "GenSigSwitchedByIgnition" SG_ 2600468494 NM_BCM1_NM_aktiv_Aussenlicht 0;
BA_ "GenSigSwitchedByIgnition" SG_ 2600468494 NM_BCM1_NM_aktiv_ComingHome 0;
BA_ "GenSigSwitchedByIgnition" SG_ 2600468494 NM_BCM1_NM_aktiv_Diagnose 0;
BA_ "GenSigSwitchedByIgnition" SG_ 2600468494 NM_BCM1_NM_aktiv_Innenlicht_Dim 0;
BA_ "GenSigSwitchedByIgnition" SG_ 2600468494 NM_BCM1_NM_aktiv_KL15 0;
BA_ "GenSigSwitchedByIgnition" SG_ 2600468494 NM_BCM1_NM_aktiv_Klimatisierung 0;
BA_ "GenSigSwitchedByIgnition" SG_ 2600468494 NM_BCM1_NM_aktiv_LeavingHome 0;
BA_ "GenSigSwitchedByIgnition" SG_ 2600468494 NM_BCM1_NM_aktiv_LIM 0;
BA_ "GenSigSwitchedByIgnition" SG_ 2600468494 NM_BCM1_NM_aktiv_Notlaufblinken 0;
BA_ "GenSigSwitchedByIgnition" SG_ 2600468494 NM_BCM1_NM_aktiv_Taster_Schalter 0;
BA_ "GenSigSwitchedByIgnition" SG_ 2600468494 NM_BCM1_NM_aktiv_Tmin 0;
BA_ "GenSigSwitchedByIgnition" SG_ 2600468494 NM_BCM1_NM_State 0;
BA_ "GenSigStartValue" SG_ 2600468494 NM_BCM1_SNI 14;
BA_ "GenSigSwitchedByIgnition" SG_ 2600468494 NM_BCM1_SNI 0;
BA_ "GenSigSwitchedByIgnition" SG_ 2600468494 NM_BCM1_UDS_CC 0;
BA_ "GenSigActiveRepetitions" SG_ 2600468496 NM_Gateway_CAB 3;
BA_ "GenSigSendType" SG_ 2600468496 NM_Gateway_CAB 4;
BA_ "GenSigFuncType" SG_ 2600468496 NM_Gateway_CAB 16;
BA_ "GenSigSwitchedByIgnition" SG_ 2600468496 NM_Gateway_CAB 0;
BA_ "GenSigSendType" SG_ 2600468496 NM_Gateway_Car_Wakeup 3;
BA_ "GenSigSwitchedByIgnition" SG_ 2600468496 NM_Gateway_Car_Wakeup 0;
BA_ "GenSigSwitchedByIgnition" SG_ 2600468496 NM_Gateway_CBV_AWB 0;
BA_ "GenSigSwitchedByIgnition" SG_ 2600468496 NM_Gateway_CBV_CRI 0;
BA_ "GenSigSwitchedByIgnition" SG_ 2600468496 NM_Gateway_NM_aktiv_Buskopplung 0;
BA_ "GenSigSwitchedByIgnition" SG_ 2600468496 NM_Gateway_NM_aktiv_Connect 0;
BA_ "GenSigSwitchedByIgnition" SG_ 2600468496 NM_Gateway_NM_aktiv_CWU 0;
BA_ "GenSigSwitchedByIgnition" SG_ 2600468496 NM_Gateway_NM_aktiv_Diagnose 0;
BA_ "GenSigSwitchedByIgnition" SG_ 2600468496 NM_Gateway_NM_aktiv_EM 0;
BA_ "GenSigSwitchedByIgnition" SG_ 2600468496 NM_Gateway_NM_aktiv_FC 0;
BA_ "GenSigSwitchedByIgnition" SG_ 2600468496 NM_Gateway_NM_aktiv_Fremdladung 0;
BA_ "GenSigSwitchedByIgnition" SG_ 2600468496 NM_Gateway_NM_aktiv_KL15 0;
BA_ "GenSigSwitchedByIgnition" SG_ 2600468496 NM_Gateway_NM_aktiv_LIN2 0;
BA_ "GenSigSwitchedByIgnition" SG_ 2600468496 NM_Gateway_NM_aktiv_OBDC 0;
BA_ "GenSigSwitchedByIgnition" SG_ 2600468496 NM_Gateway_NM_aktiv_Tmin 0;
BA_ "GenSigSwitchedByIgnition" SG_ 2600468496 NM_Gateway_NM_State 0;
BA_ "GenSigStartValue" SG_ 2600468496 NM_Gateway_SNI 16;
BA_ "GenSigSwitchedByIgnition" SG_ 2600468496 NM_Gateway_SNI 0;
BA_ "GenSigSwitchedByIgnition" SG_ 2600468496 NM_Gateway_UDS_CC 0;
BA_ "GenSigActiveRepetitions" SG_ 2600468550 NM_Klima_CAB 3;
BA_ "GenSigSendType" SG_ 2600468550 NM_Klima_CAB 4;
BA_ "GenSigSwitchedByIgnition" SG_ 2600468550 NM_Klima_CAB 0;
BA_ "GenSigSendType" SG_ 2600468550 NM_Klima_Car_Wakeup 3;
BA_ "GenSigSwitchedByIgnition" SG_ 2600468550 NM_Klima_Car_Wakeup 0;
BA_ "GenSigSwitchedByIgnition" SG_ 2600468550 NM_Klima_CBV_AWB 0;
BA_ "GenSigFuncType" SG_ 2600468550 NM_Klima_CBV_CRI 8;
BA_ "GenSigSwitchedByIgnition" SG_ 2600468550 NM_Klima_CBV_CRI 0;
BA_ "GenSigSwitchedByIgnition" SG_ 2600468550 NM_Klima_NM_aktiv_Abstellzstd 0;
BA_ "GenSigSwitchedByIgnition" SG_ 2600468550 NM_Klima_NM_aktiv_Diagnose 0;
BA_ "GenSigSwitchedByIgnition" SG_ 2600468550 NM_Klima_NM_aktiv_KL15 0;
BA_ "GenSigSwitchedByIgnition" SG_ 2600468550 NM_Klima_NM_aktiv_Tmin 0;
BA_ "GenSigSwitchedByIgnition" SG_ 2600468550 NM_Klima_NM_State 0;
BA_ "GenSigStartValue" SG_ 2600468550 NM_Klima_SNI 70;
BA_ "GenSigSwitchedByIgnition" SG_ 2600468550 NM_Klima_SNI 0;
BA_ "GenSigSwitchedByIgnition" SG_ 2600468550 NM_Klima_UDS_CC 0;
BA_ "GenSigActiveRepetitions" SG_ 2600468569 NM_Lift_VA_CAB 3;
BA_ "GenSigSendType" SG_ 2600468569 NM_Lift_VA_CAB 4;
BA_ "GenSigFuncType" SG_ 2600468569 NM_Lift_VA_CAB 16;
BA_ "GenSigSwitchedByIgnition" SG_ 2600468569 NM_Lift_VA_CAB 0;
BA_ "GenSigSendType" SG_ 2600468569 NM_Lift_VA_Car_Wakeup 3;
BA_ "GenSigSwitchedByIgnition" SG_ 2600468569 NM_Lift_VA_Car_Wakeup 0;
BA_ "GenSigSwitchedByIgnition" SG_ 2600468569 NM_Lift_VA_CBV_AWB 0;
BA_ "GenSigSwitchedByIgnition" SG_ 2600468569 NM_Lift_VA_CBV_CRI 0;
BA_ "GenSigSwitchedByIgnition" SG_ 2600468569 NM_Lift_VA_NM_aktiv_Diag 0;
BA_ "GenSigSwitchedByIgnition" SG_ 2600468569 NM_Lift_VA_NM_aktiv_KL15 0;
BA_ "GenSigSwitchedByIgnition" SG_ 2600468569 NM_Lift_VA_NM_aktiv_Tmin 0;
BA_ "GenSigSwitchedByIgnition" SG_ 2600468569 NM_Lift_VA_NM_State 0;
BA_ "GenSigStartValue" SG_ 2600468569 NM_Lift_VA_SNI 89;
BA_ "GenSigSwitchedByIgnition" SG_ 2600468569 NM_Lift_VA_SNI 0;
BA_ "GenSigSwitchedByIgnition" SG_ 2600468569 NM_Lift_VA_UDS_CC 0;
BA_ "GenSigActiveRepetitions" SG_ 2600468676 NM_VAS_L_CAB 3;
BA_ "GenSigSendType" SG_ 2600468676 NM_VAS_L_CAB 4;
BA_ "GenSigSwitchedByIgnition" SG_ 2600468676 NM_VAS_L_CAB 0;
BA_ "GenSigSendType" SG_ 2600468676 NM_VAS_L_Car_Wakeup 3;
BA_ "GenSigSwitchedByIgnition" SG_ 2600468676 NM_VAS_L_Car_Wakeup 0;
BA_ "GenSigSwitchedByIgnition" SG_ 2600468676 NM_VAS_L_CBV_AWB 0;
BA_ "GenSigSwitchedByIgnition" SG_ 2600468676 NM_VAS_L_CBV_CRI 0;
BA_ "GenSigSwitchedByIgnition" SG_ 2600468676 NM_VAS_L_NM_aktiv_Diagnose 0;
BA_ "GenSigSwitchedByIgnition" SG_ 2600468676 NM_VAS_L_NM_aktiv_KL15 0;
BA_ "GenSigSwitchedByIgnition" SG_ 2600468676 NM_VAS_L_NM_aktiv_Tmin 0;
BA_ "GenSigSwitchedByIgnition" SG_ 2600468676 NM_VAS_L_NM_aktiv_Verstellung 0;
BA_ "GenSigSwitchedByIgnition" SG_ 2600468676 NM_VAS_L_NM_State 0;
BA_ "GenSigStartValue" SG_ 2600468676 NM_VAS_L_SNI 196;
BA_ "GenSigSwitchedByIgnition" SG_ 2600468676 NM_VAS_L_SNI 0;
BA_ "GenSigSwitchedByIgnition" SG_ 2600468676 NM_VAS_L_UDS_CC 0;
BA_ "GenSigActiveRepetitions" SG_ 2600468677 NM_VAS_R_CAB 3;
BA_ "GenSigSendType" SG_ 2600468677 NM_VAS_R_CAB 4;
BA_ "GenSigSwitchedByIgnition" SG_ 2600468677 NM_VAS_R_CAB 0;
BA_ "GenSigSendType" SG_ 2600468677 NM_VAS_R_Car_Wakeup 3;
BA_ "GenSigSwitchedByIgnition" SG_ 2600468677 NM_VAS_R_Car_Wakeup 0;
BA_ "GenSigSwitchedByIgnition" SG_ 2600468677 NM_VAS_R_CBV_AWB 0;
BA_ "GenSigSwitchedByIgnition" SG_ 2600468677 NM_VAS_R_CBV_CRI 0;
BA_ "GenSigSwitchedByIgnition" SG_ 2600468677 NM_VAS_R_NM_aktiv_Diagnose 0;
BA_ "GenSigSwitchedByIgnition" SG_ 2600468677 NM_VAS_R_NM_aktiv_KL15 0;
BA_ "GenSigSwitchedByIgnition" SG_ 2600468677 NM_VAS_R_NM_aktiv_Tmin 0;
BA_ "GenSigSwitchedByIgnition" SG_ 2600468677 NM_VAS_R_NM_aktiv_Verstellung 0;
BA_ "GenSigSwitchedByIgnition" SG_ 2600468677 NM_VAS_R_NM_State 0;
BA_ "GenSigStartValue" SG_ 2600468677 NM_VAS_R_SNI 197;
BA_ "GenSigSwitchedByIgnition" SG_ 2600468677 NM_VAS_R_SNI 0;
BA_ "GenSigSwitchedByIgnition" SG_ 2600468677 NM_VAS_R_UDS_CC 0;
BA_ "GenSigSendType" SG_ 1377 NV_MessZeitpunkt 0;
BA_ "GenSigStartValue" SG_ 1377 NV_MessZeitpunkt 8191;
BA_ "GenSigSendType" SG_ 1377 NV_NichtVerfuegbar 0;
BA_ "GenSigStartValue" SG_ 1377 NV_NichtVerfuegbar 1;
BA_ "GenSigSendType" SG_ 1377 NV_Obj_01_InvTTCBildebStdA 0;
BA_ "GenSigStartValue" SG_ 1377 NV_Obj_01_InvTTCBildebStdA 127;
BA_ "GenSigSendType" SG_ 1377 NV_Obj_01_Klasse 3;
BA_ "GenSigStartValue" SG_ 1377 NV_Obj_01_Klasse 15;
BA_ "GenSigSendType" SG_ 1377 NV_Obj_Links 3;
BA_ "GenSigSendType" SG_ 1377 NV_Obj_Rechts 3;
BA_ "GenSigSendType" SG_ 1377 NV_Obj_Warnung_Fussgaenger 3;
BA_ "GenSigSendType" SG_ 1377 NV_Sensor_PositionX 0;
BA_ "GenSigStartValue" SG_ 1377 NV_Sensor_PositionX 4095;
BA_ "GenSigSendType" SG_ 1377 NV_Sensor_PositionY 0;
BA_ "GenSigStartValue" SG_ 1377 NV_Sensor_PositionY 2047;
BA_ "GenSigSendType" SG_ 1377 NV_Sensor_PositionZ 0;
BA_ "GenSigStartValue" SG_ 1377 NV_Sensor_PositionZ 2047;
BA_ "GenSigSendType" SG_ 1635 BEM_02_Abschaltstufen 0;
BA_ "GenSigSwitchedByIgnition" SG_ 1635 BEM_02_Abschaltstufen 0;
BA_ "GenSigSendType" SG_ 1635 BEM_Anf_KL15_schalten 0;
BA_ "GenSigSwitchedByIgnition" SG_ 1635 BEM_Anf_KL15_schalten 0;
BA_ "GenSigSendType" SG_ 1635 BEM_Batteriediagnose 0;
BA_ "GenSigSwitchedByIgnition" SG_ 1635 BEM_Batteriediagnose 0;
BA_ "Fehlerwert" SG_ 1635 BEM_Batteriediagnose 7;
BA_ "GenSigSendType" SG_ 1635 BEM_Generatordiagnose 0;
BA_ "GenSigSwitchedByIgnition" SG_ 1635 BEM_Generatordiagnose 0;
BA_ "GenSigSendType" SG_ 1635 BEM_HL_Regelung_Status 0;
BA_ "GenSigSwitchedByIgnition" SG_ 1635 BEM_HL_Regelung_Status 0;
BA_ "GenSigSendType" SG_ 1635 BEM_Ladezustand 0;
BA_ "GenSigStartValue" SG_ 1635 BEM_Ladezustand 14;
BA_ "GenSigSwitchedByIgnition" SG_ 1635 BEM_Ladezustand 0;
BA_ "Fehlerwert" SG_ 1635 BEM_Ladezustand 15;
BA_ "GenSigSendType" SG_ 1635 BEM_MMI_Vorwarnung 0;
BA_ "GenSigSwitchedByIgnition" SG_ 1635 BEM_MMI_Vorwarnung 0;
BA_ "GenSigSendType" SG_ 1635 BEM_Red_Innengeblaese 0;
BA_ "GenSigSwitchedByIgnition" SG_ 1635 BEM_Red_Innengeblaese 0;
BA_ "GenSigSendType" SG_ 1635 BEM_REK_aktiv 0;
BA_ "GenSigSwitchedByIgnition" SG_ 1635 BEM_REK_aktiv 0;
BA_ "GenSigSendType" SG_ 1635 BEM_STH_Einschaltverbot 0;
BA_ "GenSigSwitchedByIgnition" SG_ 1635 BEM_STH_Einschaltverbot 0;
BA_ "GenSigSendType" SG_ 1635 BEM_STH_Zielzeit 0;
BA_ "GenSigStartValue" SG_ 1635 BEM_STH_Zielzeit 14;
BA_ "GenSigSwitchedByIgnition" SG_ 1635 BEM_STH_Zielzeit 0;
BA_ "Fehlerwert" SG_ 1635 BEM_STH_Zielzeit 15;
BA_ "GenSigSendType" SG_ 1635 BEM_UBDM 0;
BA_ "GenSigSwitchedByIgnition" SG_ 1635 BEM_UBDM 0;
BA_ "Fehlerwert" SG_ 1635 BEM_UBDM 255;
BA_ "GenSigSendType" SG_ 1635 BEM_UGenSoll 0;
BA_ "GenSigSwitchedByIgnition" SG_ 1635 BEM_UGenSoll 0;
BA_ "GenSigSendType" SG_ 1635 MIB_Stromsparmodus 0;
BA_ "GenSigSwitchedByIgnition" SG_ 1635 MIB_Stromsparmodus 0;
BA_ "GenSigSendType" SG_ 1635 NVEM_Anf_SD_schalten 0;
BA_ "GenSigSwitchedByIgnition" SG_ 1635 NVEM_Anf_SD_schalten 0;
BA_ "GenSigSendType" SG_ 1635 NVEM_Batterie_Service 0;
BA_ "GenSigSwitchedByIgnition" SG_ 1635 NVEM_Batterie_Service 0;
BA_ "GenSigSendType" SG_ 1635 NVEM_Freigabe_OnlineUpdate 0;
BA_ "GenSigSwitchedByIgnition" SG_ 1635 NVEM_Freigabe_OnlineUpdate 0;
BA_ "GenSigSendType" SG_ 1635 NVEM_Freigabe_ORU4 0;
BA_ "GenSigSwitchedByIgnition" SG_ 1635 NVEM_Freigabe_ORU4 0;
BA_ "GenSigSendType" SG_ 1635 NVEM_Last_Anf 0;
BA_ "GenSigSwitchedByIgnition" SG_ 1635 NVEM_Last_Anf 0;
BA_ "GenSigSendType" SG_ 2527679508 NVEM_06_BZ 0;
BA_ "GenSigFuncType" SG_ 2527679508 NVEM_06_BZ 1;
BA_ "GenSigSwitchedByIgnition" SG_ 2527679508 NVEM_06_BZ 0;
BA_ "GenSigSendType" SG_ 2527679508 NVEM_06_CRC 0;
BA_ "GenSigFuncType" SG_ 2527679508 NVEM_06_CRC 2;
BA_ "GenSigSwitchedByIgnition" SG_ 2527679508 NVEM_06_CRC 0;
BA_ "GenSigSendType" SG_ 2527679508 NVEM_Bordnetzdiagnose 0;
BA_ "GenSigSwitchedByIgnition" SG_ 2527679508 NVEM_Bordnetzdiagnose 0;
BA_ "GenSigSendType" SG_ 2527679508 NVEM_Energie_Klima_Vorgabe 0;
BA_ "GenSigStartValue" SG_ 2527679508 NVEM_Energie_Klima_Vorgabe 254;
BA_ "GenSigSwitchedByIgnition" SG_ 2527679508 NVEM_Energie_Klima_Vorgabe 0;
BA_ "Fehlerwert" SG_ 2527679508 NVEM_Energie_Klima_Vorgabe 255;
BA_ "GenSigSendType" SG_ 2527679508 NVEM_Max_Rampenzeit 0;
BA_ "GenSigStartValue" SG_ 2527679508 NVEM_Max_Rampenzeit 6;
BA_ "GenSigSwitchedByIgnition" SG_ 2527679508 NVEM_Max_Rampenzeit 0;
BA_ "GenSigSendType" SG_ 2527679508 NVEM_Max_Spannung 0;
BA_ "GenSigStartValue" SG_ 2527679508 NVEM_Max_Spannung 126;
BA_ "GenSigSwitchedByIgnition" SG_ 2527679508 NVEM_Max_Spannung 0;
BA_ "Fehlerwert" SG_ 2527679508 NVEM_Max_Spannung 127;
BA_ "GenSigSendType" SG_ 2527679508 NVEM_Min_Spannung 0;
BA_ "GenSigStartValue" SG_ 2527679508 NVEM_Min_Spannung 126;
BA_ "GenSigSwitchedByIgnition" SG_ 2527679508 NVEM_Min_Spannung 0;
BA_ "Fehlerwert" SG_ 2527679508 NVEM_Min_Spannung 127;
BA_ "GenSigSendType" SG_ 2527679508 NVEM_Min_Spannung_Start 3;
BA_ "GenSigStartValue" SG_ 2527679508 NVEM_Min_Spannung_Start 62;
BA_ "GenSigSwitchedByIgnition" SG_ 2527679508 NVEM_Min_Spannung_Start 0;
BA_ "Fehlerwert" SG_ 2527679508 NVEM_Min_Spannung_Start 63;
BA_ "GenSigSendType" SG_ 2527679508 NVEM_MV_DC_uMinLV 0;
BA_ "GenSigStartValue" SG_ 2527679508 NVEM_MV_DC_uMinLV 126;
BA_ "GenSigSwitchedByIgnition" SG_ 2527679508 NVEM_MV_DC_uMinLV 0;
BA_ "Fehlerwert" SG_ 2527679508 NVEM_MV_DC_uMinLV 127;
BA_ "GenSigSendType" SG_ 2527679508 NVEM_MV_DC_uSollLV 0;
BA_ "GenSigStartValue" SG_ 2527679508 NVEM_MV_DC_uSollLV 126;
BA_ "GenSigSwitchedByIgnition" SG_ 2527679508 NVEM_MV_DC_uSollLV 0;
BA_ "Fehlerwert" SG_ 2527679508 NVEM_MV_DC_uSollLV 127;
BA_ "GenSigSendType" SG_ 913 MO_QBit_Aussen_Temp 0;
BA_ "GenSigStartValue" SG_ 913 MO_QBit_Aussen_Temp 1;
BA_ "GenSigSwitchedByIgnition" SG_ 913 MO_QBit_Aussen_Temp 0;
BA_ "GenSigSendType" SG_ 913 MO_Servicemodus 0;
BA_ "GenSigSwitchedByIgnition" SG_ 913 MO_Servicemodus 0;
BA_ "GenSigSendType" SG_ 913 OBD_Abs_Load_Val 0;
BA_ "GenSigStartValue" SG_ 913 OBD_Abs_Load_Val 65535;
BA_ "GenSigSwitchedByIgnition" SG_ 913 OBD_Abs_Load_Val 0;
BA_ "GenSigSendType" SG_ 913 OBD_Abs_Pedal_Pos 0;
BA_ "GenSigStartValue" SG_ 913 OBD_Abs_Pedal_Pos 255;
BA_ "GenSigSwitchedByIgnition" SG_ 913 OBD_Abs_Pedal_Pos 0;
BA_ "GenSigSendType" SG_ 913 OBD_Abs_Throttle_Pos 0;
BA_ "GenSigStartValue" SG_ 913 OBD_Abs_Throttle_Pos 255;
BA_ "GenSigSwitchedByIgnition" SG_ 913 OBD_Abs_Throttle_Pos 0;
BA_ "GenSigSendType" SG_ 913 OBD_Calc_Load_Val 0;
BA_ "GenSigStartValue" SG_ 913 OBD_Calc_Load_Val 255;
BA_ "GenSigSwitchedByIgnition" SG_ 913 OBD_Calc_Load_Val 0;
BA_ "GenSigSendType" SG_ 913 OBD_ClearMem_Inhibit 0;
BA_ "GenSigSwitchedByIgnition" SG_ 913 OBD_ClearMem_Inhibit 0;
BA_ "GenSigSendType" SG_ 913 OBD_Driving_Cycle 0;
BA_ "GenSigSwitchedByIgnition" SG_ 913 OBD_Driving_Cycle 0;
BA_ "GenSigSendType" SG_ 913 OBD_Eng_Cool_Temp 0;
BA_ "GenSigStartValue" SG_ 913 OBD_Eng_Cool_Temp 255;
BA_ "GenSigSwitchedByIgnition" SG_ 913 OBD_Eng_Cool_Temp 0;
BA_ "GenSigSendType" SG_ 913 OBD_Kaltstart_Denominator 0;
BA_ "GenSigSwitchedByIgnition" SG_ 913 OBD_Kaltstart_Denominator 0;
BA_ "GenSigSendType" SG_ 913 OBD_Minimum_Trip 0;
BA_ "GenSigSwitchedByIgnition" SG_ 913 OBD_Minimum_Trip 0;
BA_ "GenSigSendType" SG_ 913 OBD_Normed_Trip 0;
BA_ "GenSigSwitchedByIgnition" SG_ 913 OBD_Normed_Trip 0;
BA_ "GenSigSendType" SG_ 913 OBD_Sperrung_IUMPR 0;
BA_ "GenSigSwitchedByIgnition" SG_ 913 OBD_Sperrung_IUMPR 0;
BA_ "GenSigSendType" SG_ 913 OBD_Sperrung_Kaltstart_Denom 0;
BA_ "GenSigSwitchedByIgnition" SG_ 913 OBD_Sperrung_Kaltstart_Denom 0;
BA_ "GenSigSendType" SG_ 913 OBD_Warm_Up_Cycle 0;
BA_ "GenSigSwitchedByIgnition" SG_ 913 OBD_Warm_Up_Cycle 0;
BA_ "GenSigSendType" SG_ 2549875214 OBDC_BCM1_Req_Data 3;
BA_ "GenSigFuncType" SG_ 2549875214 OBDC_BCM1_Req_Data 9;
BA_ "GenSigSwitchedByIgnition" SG_ 2549875214 OBDC_BCM1_Req_Data 0;
BA_ "GenSigSendType" SG_ 2550006286 OBDC_BCM1_Resp_Data 3;
BA_ "GenSigFuncType" SG_ 2550006286 OBDC_BCM1_Resp_Data 9;
BA_ "GenSigSwitchedByIgnition" SG_ 2550006286 OBDC_BCM1_Resp_Data 0;
BA_ "GenSigSendType" SG_ 2549875352 OBDC_DMD_L_Req_Data 3;
BA_ "GenSigFuncType" SG_ 2549875352 OBDC_DMD_L_Req_Data 9;
BA_ "GenSigSwitchedByIgnition" SG_ 2549875352 OBDC_DMD_L_Req_Data 0;
BA_ "GenSigSendType" SG_ 2550006424 OBDC_DMD_L_Resp_Data 3;
BA_ "GenSigFuncType" SG_ 2550006424 OBDC_DMD_L_Resp_Data 9;
BA_ "GenSigSwitchedByIgnition" SG_ 2550006424 OBDC_DMD_L_Resp_Data 0;
BA_ "GenSigSendType" SG_ 2549875353 OBDC_DMD_R_Req_Data 3;
BA_ "GenSigFuncType" SG_ 2549875353 OBDC_DMD_R_Req_Data 9;
BA_ "GenSigSwitchedByIgnition" SG_ 2549875353 OBDC_DMD_R_Req_Data 0;
BA_ "GenSigSendType" SG_ 2550006425 OBDC_DMD_R_Resp_Data 3;
BA_ "GenSigFuncType" SG_ 2550006425 OBDC_DMD_R_Resp_Data 9;
BA_ "GenSigSwitchedByIgnition" SG_ 2550006425 OBDC_DMD_R_Resp_Data 0;
BA_ "GenSigSendType" SG_ 2549940736 OBDC_Funktionaler_Req_All_Data 3;
BA_ "GenSigFuncType" SG_ 2549940736 OBDC_Funktionaler_Req_All_Data 9;
BA_ "GenSigSwitchedByIgnition" SG_ 2549940736 OBDC_Funktionaler_Req_All_Data 0;
BA_ "GenSigSendType" SG_ 2549875270 OBDC_Klima_Req_Data 3;
BA_ "GenSigFuncType" SG_ 2549875270 OBDC_Klima_Req_Data 9;
BA_ "GenSigSwitchedByIgnition" SG_ 2549875270 OBDC_Klima_Req_Data 0;
BA_ "GenSigSendType" SG_ 2550006342 OBDC_Klima_Resp_Data 3;
BA_ "GenSigFuncType" SG_ 2550006342 OBDC_Klima_Resp_Data 9;
BA_ "GenSigSwitchedByIgnition" SG_ 2550006342 OBDC_Klima_Resp_Data 0;
BA_ "GenSigSendType" SG_ 2549875330 OBDC_LCM_L_Req_Data 3;
BA_ "GenSigFuncType" SG_ 2549875330 OBDC_LCM_L_Req_Data 9;
BA_ "GenSigSwitchedByIgnition" SG_ 2549875330 OBDC_LCM_L_Req_Data 0;
BA_ "GenSigSendType" SG_ 2550006402 OBDC_LCM_L_Resp_Data 3;
BA_ "GenSigFuncType" SG_ 2550006402 OBDC_LCM_L_Resp_Data 9;
BA_ "GenSigSwitchedByIgnition" SG_ 2550006402 OBDC_LCM_L_Resp_Data 0;
BA_ "GenSigSendType" SG_ 2549875331 OBDC_LCM_R_Req_Data 3;
BA_ "GenSigFuncType" SG_ 2549875331 OBDC_LCM_R_Req_Data 9;
BA_ "GenSigSwitchedByIgnition" SG_ 2549875331 OBDC_LCM_R_Req_Data 0;
BA_ "GenSigSendType" SG_ 2550006403 OBDC_LCM_R_Resp_Data 3;
BA_ "GenSigFuncType" SG_ 2550006403 OBDC_LCM_R_Resp_Data 9;
BA_ "GenSigSwitchedByIgnition" SG_ 2550006403 OBDC_LCM_R_Resp_Data 0;
BA_REL_ "GenSigTimeoutTime" BU_SG_REL_ BCM1 SG_ 1635 BEM_02_Abschaltstufen 1000;
BA_REL_ "GenSigTimeoutTime" BU_SG_REL_ BCM1 SG_ 1635 BEM_STH_Zielzeit 1000;
BA_REL_ "GenSigTimeoutTime" BU_SG_REL_ BCM1 SG_ 1635 NVEM_Anf_SD_schalten 1000;
BA_REL_ "GenSigTimeoutTime" BU_SG_REL_ BCM1 SG_ 1635 BEM_Red_Innengeblaese 1000;
BA_REL_ "GenSigTimeoutTime" BU_SG_REL_ BCM1 SG_ 1635 BEM_STH_Einschaltverbot 1000;
BA_REL_ "GenSigTimeoutTime" BU_SG_REL_ BCM1 SG_ 1635 BEM_HL_Regelung_Status 1000;
BA_REL_ "GenSigTimeoutTime" BU_SG_REL_ BCM1 SG_ 1648 MO_Abstellzeit 5000;
BA_REL_ "GenSigTimeoutTime" BU_SG_REL_ BCM1 SG_ 1648 MO_Abstellzeit_Status 5000;
BA_REL_ "GenSigTimeoutTime" BU_SG_REL_ BCM1 SG_ 1648 MO_Hybrid_StartStopp_LED 5000;
BA_REL_ "GenSigTimeoutTime" BU_SG_REL_ BCM1 SG_ 289 MO_Fahrpedalrohwert_01 500;
BA_REL_ "GenSigTimeoutTime" BU_SG_REL_ BCM1 SG_ 1423 MO_ITM_Status 3200;
BA_REL_ "GenSigTimeoutTime" BU_SG_REL_ BCM1 SG_ 1423 MO_FSA_Sensorheizung 3200;
BA_REL_ "GenSigTimeoutTime" BU_SG_REL_ BCM1 SG_ 1423 FSA_Fehlerpfade_Initialisieren 3200;
BA_REL_ "GenSigTimeoutTime" BU_SG_REL_ BCM1 SG_ 967 MO_Kuehlerluefter_MUX 800;
BA_REL_ "GenSigTimeoutTime" BU_SG_REL_ BCM1 SG_ 967 MO_Kuehlerluefter_1 800;
BA_REL_ "GenSigTimeoutTime" BU_SG_REL_ BCM1 SG_ 967 MO_Kuehlerluefter_2 800;
BA_REL_ "GenSigTimeoutTime" BU_SG_REL_ BCM1 SG_ 340 MO_Drehzahl_VM 2000;
BA_REL_ "GenSigTimeoutTime" BU_SG_REL_ BCM1 SG_ 283 MO_Fahrbereitschaft 5000;
BA_REL_ "GenSigTimeoutTime" BU_SG_REL_ BCM1 SG_ 1601 Motor_Code_01_CRC 5000;
BA_REL_ "GenSigTimeoutTime" BU_SG_REL_ BCM1 SG_ 1601 Motor_Code_01_BZ 5000;
BA_REL_ "GenSigTimeoutTime" BU_SG_REL_ BCM1 SG_ 1601 MO_Faktor_Momente_02 5000;
BA_REL_ "GenSigTimeoutTime" BU_SG_REL_ BCM1 SG_ 1601 MO_Hybridfahrzeug 5000;
BA_REL_ "GenSigTimeoutTime" BU_SG_REL_ BCM1 SG_ 1601 MO_Code 5000;
BA_REL_ "GenSigTimeoutTime" BU_SG_REL_ BCM1 SG_ 1601 MO_Getriebe_Code 5000;
BA_REL_ "GenSigTimeoutTime" BU_SG_REL_ BCM1 SG_ 1601 MO_Kraftstoffart 5000;
BA_REL_ "GenSigTimeoutTime" BU_SG_REL_ BCM1 SG_ 1601 MO_OBD_Typ 5000;
BA_REL_ "GenSigTimeoutTime" BU_SG_REL_ BCM1 SG_ 394 MO_Start_Art 2000;
BA_REL_ "GenSigTimeoutTime" BU_SG_REL_ BCM1 SG_ 1156 ND_Heading 5000;
BA_REL_ "GenSigTimeoutTime" BU_SG_REL_ BCM1 SG_ 1156 ND_Init 5000;
BA_REL_ "GenSigTimeoutTime" BU_SG_REL_ BCM1 SG_ 1157 NP_Altitude 5000;
BA_REL_ "GenSigTimeoutTime" BU_SG_REL_ BCM1 SG_ 1157 ND_UTC 5000;
BA_REL_ "GenSigTimeoutTime" BU_SG_REL_ BCM1 SG_ 1158 NP_LatDegree 5000;
BA_REL_ "GenSigTimeoutTime" BU_SG_REL_ BCM1 SG_ 1158 NP_LongDegree 5000;
BA_REL_ "GenSigTimeoutTime" BU_SG_REL_ BCM1 SG_ 1158 NP_LatDirection 5000;
BA_REL_ "GenSigTimeoutTime" BU_SG_REL_ BCM1 SG_ 1158 NP_LongDirection 5000;
BA_REL_ "GenSigTimeoutTime" BU_SG_REL_ BCM1 SG_ 2527679647 ZV_auf_NFC 2000;
BA_REL_ "GenSigTimeoutTime" BU_SG_REL_ BCM1 SG_ 2527679647 ZV_zu_NFC 2000;
BA_REL_ "GenSigTimeoutTime" BU_SG_REL_ BCM1 SG_ 2527679647 NFC_Front_Verr_Authorisiert 2000;
BA_REL_ "GenSigTimeoutTime" BU_SG_REL_ BCM1 SG_ 2527679647 NFC_Front_Entr_Authorisiert 2000;
BA_REL_ "GenSigTimeoutTime" BU_SG_REL_ BCM1 SG_ 1696 NV_Symbol 2000;
BA_REL_ "GenSigTimeoutTime" BU_SG_REL_ BCM1 SG_ 1696 NV_Symbol_Tierwarnung 2000;
BA_REL_ "GenSigTimeoutTime" BU_SG_REL_ BCM1 SG_ 2600468496 NM_Gateway_SNI 2000;
BA_REL_ "GenSigTimeoutTime" BU_SG_REL_ BCM1 SG_ 2600468496 NM_Gateway_CBV_CRI 2000;
BA_REL_ "GenSigTimeoutTime" BU_SG_REL_ BCM1 SG_ 2600468496 NM_Gateway_CAB 2000;
BA_REL_ "GenSigTimeoutTime" BU_SG_REL_ BCM1 SG_ 2600468550 NM_Klima_SNI 2000;
BA_REL_ "GenSigTimeoutTime" BU_SG_REL_ BCM1 SG_ 2600468550 NM_Klima_CBV_CRI 2000;
BA_REL_ "GenSigTimeoutTime" BU_SG_REL_ BCM1 SG_ 2600468550 NM_Klima_CAB 2000;
BA_REL_ "GenSigTimeoutTime" BU_SG_REL_ BCM1 SG_ 2600468569 NM_Lift_VA_SNI 2000;
BA_REL_ "GenSigTimeoutTime" BU_SG_REL_ BCM1 SG_ 2600468569 NM_Lift_VA_CBV_CRI 2000;
BA_REL_ "GenSigTimeoutTime" BU_SG_REL_ BCM1 SG_ 2600468569 NM_Lift_VA_CAB 2000;
BA_REL_ "GenSigTimeoutTime" BU_SG_REL_ BCM1 SG_ 2600468676 NM_VAS_L_SNI 2000;
BA_REL_ "GenSigTimeoutTime" BU_SG_REL_ BCM1 SG_ 2600468676 NM_VAS_L_CBV_CRI 2000;
BA_REL_ "GenSigTimeoutTime" BU_SG_REL_ BCM1 SG_ 2600468676 NM_VAS_L_CAB 2000;
BA_REL_ "GenSigTimeoutTime" BU_SG_REL_ BCM1 SG_ 2600468677 NM_VAS_R_SNI 2000;
BA_REL_ "GenSigTimeoutTime" BU_SG_REL_ BCM1 SG_ 2600468677 NM_VAS_R_CBV_CRI 2000;
BA_REL_ "GenSigTimeoutTime" BU_SG_REL_ BCM1 SG_ 2600468677 NM_VAS_R_CAB 2000;
BA_REL_ "GenSigTimeoutTime" BU_SG_REL_ BCM1 SG_ 1377 NV_Obj_Rechts 2000;
BA_REL_ "GenSigTimeoutTime" BU_SG_REL_ BCM1 SG_ 1377 NV_Obj_Links 2000;
BA_REL_ "GenSigTimeoutTime" BU_SG_REL_ BCM1 SG_ 1377 NV_Obj_01_Klasse 2000;
BA_REL_ "GenSigTimeoutTime" BU_SG_REL_ BCM1 SG_ 2527679508 NVEM_Energie_Klima_Vorgabe 1000;
BA_REL_ "GenSigTimeoutTime" BU_SG_REL_ Gateway SG_ 2600468494 NM_BCM1_SNI 2000;
BA_REL_ "GenSigTimeoutTime" BU_SG_REL_ Gateway SG_ 2600468494 NM_BCM1_CBV_AWB 2000;
BA_REL_ "GenSigTimeoutTime" BU_SG_REL_ Gateway SG_ 2600468494 NM_BCM1_CBV_CRI 2000;
BA_REL_ "GenSigTimeoutTime" BU_SG_REL_ Gateway SG_ 2600468494 NM_BCM1_Car_Wakeup 2000;
BA_REL_ "GenSigTimeoutTime" BU_SG_REL_ Gateway SG_ 2600468494 NM_BCM1_CAB 2000;
BA_REL_ "GenSigTimeoutTime" BU_SG_REL_ Gateway SG_ 2600468550 NM_Klima_SNI 2000;
BA_REL_ "GenSigTimeoutTime" BU_SG_REL_ Gateway SG_ 2600468550 NM_Klima_CBV_AWB 2000;
BA_REL_ "GenSigTimeoutTime" BU_SG_REL_ Gateway SG_ 2600468550 NM_Klima_CBV_CRI 2000;
BA_REL_ "GenSigTimeoutTime" BU_SG_REL_ Gateway SG_ 2600468550 NM_Klima_Car_Wakeup 2000;
BA_REL_ "GenSigTimeoutTime" BU_SG_REL_ Gateway SG_ 2600468550 NM_Klima_CAB 2000;
BA_REL_ "GenSigTimeoutTime" BU_SG_REL_ Gateway SG_ 2600468569 NM_Lift_VA_SNI 2000;
BA_REL_ "GenSigTimeoutTime" BU_SG_REL_ Gateway SG_ 2600468569 NM_Lift_VA_CBV_CRI 2000;
BA_REL_ "GenSigTimeoutTime" BU_SG_REL_ Gateway SG_ 2600468569 NM_Lift_VA_CAB 2000;
BA_REL_ "GenSigTimeoutTime" BU_SG_REL_ Gateway SG_ 2600468676 NM_VAS_L_SNI 2000;
BA_REL_ "GenSigTimeoutTime" BU_SG_REL_ Gateway SG_ 2600468676 NM_VAS_L_CBV_AWB 2000;
BA_REL_ "GenSigTimeoutTime" BU_SG_REL_ Gateway SG_ 2600468676 NM_VAS_L_CBV_CRI 2000;
BA_REL_ "GenSigTimeoutTime" BU_SG_REL_ Gateway SG_ 2600468676 NM_VAS_L_Car_Wakeup 2000;
BA_REL_ "GenSigTimeoutTime" BU_SG_REL_ Gateway SG_ 2600468676 NM_VAS_L_CAB 2000;
BA_REL_ "GenSigTimeoutTime" BU_SG_REL_ Gateway SG_ 2600468677 NM_VAS_R_SNI 2000;
BA_REL_ "GenSigTimeoutTime" BU_SG_REL_ Gateway SG_ 2600468677 NM_VAS_R_CBV_AWB 2000;
BA_REL_ "GenSigTimeoutTime" BU_SG_REL_ Gateway SG_ 2600468677 NM_VAS_R_CBV_CRI 2000;
BA_REL_ "GenSigTimeoutTime" BU_SG_REL_ Gateway SG_ 2600468677 NM_VAS_R_Car_Wakeup 2000;
BA_REL_ "GenSigTimeoutTime" BU_SG_REL_ Gateway SG_ 2600468677 NM_VAS_R_CAB 2000;
BA_REL_ "GenSigTimeoutTime" BU_SG_REL_ Gateway_PAG SG_ 2600468494 NM_BCM1_SNI 2000;
BA_REL_ "GenSigTimeoutTime" BU_SG_REL_ Gateway_PAG SG_ 2600468494 NM_BCM1_CBV_AWB 2000;
BA_REL_ "GenSigTimeoutTime" BU_SG_REL_ Gateway_PAG SG_ 2600468494 NM_BCM1_CBV_CRI 2000;
BA_REL_ "GenSigTimeoutTime" BU_SG_REL_ Gateway_PAG SG_ 2600468494 NM_BCM1_Car_Wakeup 2000;
BA_REL_ "GenSigTimeoutTime" BU_SG_REL_ Gateway_PAG SG_ 2600468494 NM_BCM1_CAB 2000;
BA_REL_ "GenSigTimeoutTime" BU_SG_REL_ Gateway_PAG SG_ 2600468550 NM_Klima_SNI 2000;
BA_REL_ "GenSigTimeoutTime" BU_SG_REL_ Gateway_PAG SG_ 2600468550 NM_Klima_CBV_AWB 2000;
BA_REL_ "GenSigTimeoutTime" BU_SG_REL_ Gateway_PAG SG_ 2600468550 NM_Klima_CBV_CRI 2000;
BA_REL_ "GenSigTimeoutTime" BU_SG_REL_ Gateway_PAG SG_ 2600468550 NM_Klima_Car_Wakeup 2000;
BA_REL_ "GenSigTimeoutTime" BU_SG_REL_ Gateway_PAG SG_ 2600468550 NM_Klima_CAB 2000;
BA_REL_ "GenSigTimeoutTime" BU_SG_REL_ Gateway_PAG SG_ 2600468569 NM_Lift_VA_SNI 2000;
BA_REL_ "GenSigTimeoutTime" BU_SG_REL_ Gateway_PAG SG_ 2600468569 NM_Lift_VA_CBV_CRI 2000;
BA_REL_ "GenSigTimeoutTime" BU_SG_REL_ Gateway_PAG SG_ 2600468569 NM_Lift_VA_CAB 2000;
BA_REL_ "GenSigTimeoutTime" BU_SG_REL_ Gateway_PAG SG_ 2600468676 NM_VAS_L_SNI 2000;
BA_REL_ "GenSigTimeoutTime" BU_SG_REL_ Gateway_PAG SG_ 2600468676 NM_VAS_L_CBV_AWB 2000;
BA_REL_ "GenSigTimeoutTime" BU_SG_REL_ Gateway_PAG SG_ 2600468676 NM_VAS_L_CBV_CRI 2000;
BA_REL_ "GenSigTimeoutTime" BU_SG_REL_ Gateway_PAG SG_ 2600468676 NM_VAS_L_Car_Wakeup 2000;
BA_REL_ "GenSigTimeoutTime" BU_SG_REL_ Gateway_PAG SG_ 2600468676 NM_VAS_L_CAB 2000;
BA_REL_ "GenSigTimeoutTime" BU_SG_REL_ Gateway_PAG SG_ 2600468677 NM_VAS_R_SNI 2000;
BA_REL_ "GenSigTimeoutTime" BU_SG_REL_ Gateway_PAG SG_ 2600468677 NM_VAS_R_CBV_AWB 2000;
BA_REL_ "GenSigTimeoutTime" BU_SG_REL_ Gateway_PAG SG_ 2600468677 NM_VAS_R_CBV_CRI 2000;
BA_REL_ "GenSigTimeoutTime" BU_SG_REL_ Gateway_PAG SG_ 2600468677 NM_VAS_R_Car_Wakeup 2000;
BA_REL_ "GenSigTimeoutTime" BU_SG_REL_ Gateway_PAG SG_ 2600468677 NM_VAS_R_CAB 2000;
BA_REL_ "GenSigTimeoutTime" BU_SG_REL_ Klima_MSB SG_ 1635 BEM_02_Abschaltstufen 1000;
BA_REL_ "GenSigTimeoutTime" BU_SG_REL_ Klima_MSB SG_ 1635 BEM_STH_Zielzeit 1000;
BA_REL_ "GenSigTimeoutTime" BU_SG_REL_ Klima_MSB SG_ 1635 BEM_Red_Innengeblaese 1000;
BA_REL_ "GenSigTimeoutTime" BU_SG_REL_ Klima_MSB SG_ 1635 BEM_STH_Einschaltverbot 1000;
BA_REL_ "GenSigTimeoutTime" BU_SG_REL_ Klima_MSB SG_ 1635 BEM_HL_Regelung_Status 1000;
BA_REL_ "GenSigTimeoutTime" BU_SG_REL_ Klima_MSB SG_ 1635 BEM_UBDM 1000;
BA_REL_ "GenSigTimeoutTime" BU_SG_REL_ Klima_MSB SG_ 1648 MO_Abstellzeit 5000;
BA_REL_ "GenSigTimeoutTime" BU_SG_REL_ Klima_MSB SG_ 1648 MO_Abstellzeit_Status 5000;
BA_REL_ "GenSigTimeoutTime" BU_SG_REL_ Klima_MSB SG_ 1423 MO_ITM_Status 3200;
BA_REL_ "GenSigTimeoutTime" BU_SG_REL_ Klima_MSB SG_ 1423 MO_MMTR_Status 3200;
BA_REL_ "GenSigTimeoutTime" BU_SG_REL_ Klima_MSB SG_ 967 MO_Kuehlerluefter_MUX 800;
BA_REL_ "GenSigTimeoutTime" BU_SG_REL_ Klima_MSB SG_ 967 MO_Kuehlerluefter_1 800;
BA_REL_ "GenSigTimeoutTime" BU_SG_REL_ Klima_MSB SG_ 967 MO_Kuehlerluefter_2 800;
BA_REL_ "GenSigTimeoutTime" BU_SG_REL_ Klima_MSB SG_ 340 MO_Drehzahl_VM 2000;
BA_REL_ "GenSigTimeoutTime" BU_SG_REL_ Klima_MSB SG_ 1601 MO_Code 5000;
BA_REL_ "GenSigTimeoutTime" BU_SG_REL_ Klima_MSB SG_ 1601 MO_Getriebe_Code 5000;
BA_REL_ "GenSigTimeoutTime" BU_SG_REL_ Klima_MSB SG_ 394 MO_Start_Art 2000;
BA_REL_ "GenSigTimeoutTime" BU_SG_REL_ Klima_MSB SG_ 1156 ND_Heading 5000;
BA_REL_ "GenSigTimeoutTime" BU_SG_REL_ Klima_MSB SG_ 1157 NP_Altitude 5000;
BA_REL_ "GenSigTimeoutTime" BU_SG_REL_ Klima_MSB SG_ 2527679512 ND_Timezone_Offset 5000;
BA_REL_ "GenSigTimeoutTime" BU_SG_REL_ Klima_MSB SG_ 2527679512 ND_Timezone_DaylightSavingOffset 5000;
BA_REL_ "GenSigTimeoutTime" BU_SG_REL_ Klima_MSB SG_ 2527679512 ND_Timezone_SignBit 5000;
BA_REL_ "GenSigTimeoutTime" BU_SG_REL_ Klima_MSB SG_ 2527679512 ND_Timezone_Validity 5000;
BA_REL_ "GenSigTimeoutTime" BU_SG_REL_ Klima_MSB SG_ 1158 NP_LatDegree 5000;
BA_REL_ "GenSigTimeoutTime" BU_SG_REL_ Klima_MSB SG_ 1158 NP_LongDegree 5000;
BA_REL_ "GenSigTimeoutTime" BU_SG_REL_ Klima_MSB SG_ 1158 NP_LatDirection 5000;
BA_REL_ "GenSigTimeoutTime" BU_SG_REL_ Klima_MSB SG_ 1158 NP_LongDirection 5000;
BA_REL_ "GenSigTimeoutTime" BU_SG_REL_ Klima_MSB SG_ 2589283496 POS_MUX 5000;
BA_REL_ "GenSigTimeoutTime" BU_SG_REL_ Klima_MSB SG_ 2589283496 POS_PosStati 5000;
BA_REL_ "GenSigTimeoutTime" BU_SG_REL_ Klima_MSB SG_ 2589283496 POS_Heading 5000;
BA_REL_ "GenSigTimeoutTime" BU_SG_REL_ Klima_MSB SG_ 2589283496 POS_LatDirection 5000;
BA_REL_ "GenSigTimeoutTime" BU_SG_REL_ Klima_MSB SG_ 2589283496 POS_LatDegree 5000;
BA_REL_ "GenSigTimeoutTime" BU_SG_REL_ Klima_MSB SG_ 2589283496 POS_Heading_Trust 5000;
BA_REL_ "GenSigTimeoutTime" BU_SG_REL_ Klima_MSB SG_ 2589283496 POS_UTC_REF 5000;
BA_REL_ "GenSigTimeoutTime" BU_SG_REL_ Klima_MSB SG_ 2589283496 POS_LongDirection 5000;
BA_REL_ "GenSigTimeoutTime" BU_SG_REL_ Klima_MSB SG_ 2589283496 POS_LongDegree 5000;
BA_REL_ "GenSigTimeoutTime" BU_SG_REL_ Klima_MSB SG_ 2600468494 NM_BCM1_SNI 2000;
BA_REL_ "GenSigTimeoutTime" BU_SG_REL_ Klima_MSB SG_ 2600468494 NM_BCM1_CBV_CRI 2000;
BA_REL_ "GenSigTimeoutTime" BU_SG_REL_ Klima_MSB SG_ 2600468494 NM_BCM1_CAB 2000;
BA_REL_ "GenSigTimeoutTime" BU_SG_REL_ Klima_MSB SG_ 2600468496 NM_Gateway_SNI 2000;
BA_REL_ "GenSigTimeoutTime" BU_SG_REL_ Klima_MSB SG_ 2600468496 NM_Gateway_CBV_CRI 2000;
BA_REL_ "GenSigTimeoutTime" BU_SG_REL_ Klima_MSB SG_ 2600468496 NM_Gateway_CAB 2000;
BA_REL_ "GenSigTimeoutTime" BU_SG_REL_ Klima_MSB SG_ 2600468550 NM_Klima_SNI 2000;
BA_REL_ "GenSigTimeoutTime" BU_SG_REL_ Klima_MSB SG_ 2600468550 NM_Klima_CBV_CRI 2000;
BA_REL_ "GenSigTimeoutTime" BU_SG_REL_ Klima_MSB SG_ 2600468550 NM_Klima_CAB 2000;
BA_REL_ "GenSigTimeoutTime" BU_SG_REL_ Klima_MSB SG_ 2600468569 NM_Lift_VA_SNI 2000;
BA_REL_ "GenSigTimeoutTime" BU_SG_REL_ Klima_MSB SG_ 2600468569 NM_Lift_VA_CBV_CRI 2000;
BA_REL_ "GenSigTimeoutTime" BU_SG_REL_ Klima_MSB SG_ 2600468569 NM_Lift_VA_CAB 2000;
BA_REL_ "GenSigTimeoutTime" BU_SG_REL_ Klima_MSB SG_ 2600468676 NM_VAS_L_SNI 2000;
BA_REL_ "GenSigTimeoutTime" BU_SG_REL_ Klima_MSB SG_ 2600468676 NM_VAS_L_CBV_CRI 2000;
BA_REL_ "GenSigTimeoutTime" BU_SG_REL_ Klima_MSB SG_ 2600468676 NM_VAS_L_CAB 2000;
BA_REL_ "GenSigTimeoutTime" BU_SG_REL_ Klima_MSB SG_ 2600468677 NM_VAS_R_SNI 2000;
BA_REL_ "GenSigTimeoutTime" BU_SG_REL_ Klima_MSB SG_ 2600468677 NM_VAS_R_CBV_CRI 2000;
BA_REL_ "GenSigTimeoutTime" BU_SG_REL_ Klima_MSB SG_ 2600468677 NM_VAS_R_CAB 2000;
BA_REL_ "GenSigTimeoutTime" BU_SG_REL_ Klima_MSB SG_ 2527679508 NVEM_Energie_Klima_Vorgabe 1000;
BA_REL_ "GenSigTimeoutTime" BU_SG_REL_ Lift_VA SG_ 1635 BEM_02_Abschaltstufen 1000;
BA_REL_ "GenSigTimeoutTime" BU_SG_REL_ Lift_VA SG_ 1635 BEM_HL_Regelung_Status 1000;
BA_REL_ "GenSigTimeoutTime" BU_SG_REL_ Lift_VA SG_ 1601 MO_StartStopp_Codiert 5000;
BA_REL_ "GenSigTimeoutTime" BU_SG_REL_ Lift_VA SG_ 2600468494 NM_BCM1_SNI 2000;
BA_REL_ "GenSigTimeoutTime" BU_SG_REL_ Lift_VA SG_ 2600468494 NM_BCM1_CBV_CRI 2000;
BA_REL_ "GenSigTimeoutTime" BU_SG_REL_ Lift_VA SG_ 2600468494 NM_BCM1_CAB 2000;
BA_REL_ "GenSigTimeoutTime" BU_SG_REL_ Lift_VA SG_ 2600468496 NM_Gateway_SNI 2000;
BA_REL_ "GenSigTimeoutTime" BU_SG_REL_ Lift_VA SG_ 2600468496 NM_Gateway_CBV_CRI 2000;
BA_REL_ "GenSigTimeoutTime" BU_SG_REL_ Lift_VA SG_ 2600468496 NM_Gateway_CAB 2000;
BA_REL_ "GenSigTimeoutTime" BU_SG_REL_ Lift_VA SG_ 2600468550 NM_Klima_SNI 2000;
BA_REL_ "GenSigTimeoutTime" BU_SG_REL_ Lift_VA SG_ 2600468550 NM_Klima_CBV_CRI 2000;
BA_REL_ "GenSigTimeoutTime" BU_SG_REL_ Lift_VA SG_ 2600468550 NM_Klima_CAB 2000;
BA_REL_ "GenSigTimeoutTime" BU_SG_REL_ Lift_VA SG_ 2600468676 NM_VAS_L_SNI 2000;
BA_REL_ "GenSigTimeoutTime" BU_SG_REL_ Lift_VA SG_ 2600468676 NM_VAS_L_CBV_CRI 2000;
BA_REL_ "GenSigTimeoutTime" BU_SG_REL_ Lift_VA SG_ 2600468676 NM_VAS_L_CAB 2000;
BA_REL_ "GenSigTimeoutTime" BU_SG_REL_ Lift_VA SG_ 2600468677 NM_VAS_R_SNI 2000;
BA_REL_ "GenSigTimeoutTime" BU_SG_REL_ Lift_VA SG_ 2600468677 NM_VAS_R_CBV_CRI 2000;
BA_REL_ "GenSigTimeoutTime" BU_SG_REL_ Lift_VA SG_ 2600468677 NM_VAS_R_CAB 2000;
BA_REL_ "GenSigTimeoutTime" BU_SG_REL_ Lift_VA SG_ 913 OBD_Warm_Up_Cycle 800;
BA_REL_ "GenSigTimeoutTime" BU_SG_REL_ VAS_L SG_ 1635 BEM_02_Abschaltstufen 1000;
BA_REL_ "GenSigTimeoutTime" BU_SG_REL_ VAS_L SG_ 2600468494 NM_BCM1_SNI 2000;
BA_REL_ "GenSigTimeoutTime" BU_SG_REL_ VAS_L SG_ 2600468494 NM_BCM1_CBV_CRI 2000;
BA_REL_ "GenSigTimeoutTime" BU_SG_REL_ VAS_L SG_ 2600468494 NM_BCM1_CAB 2000;
BA_REL_ "GenSigTimeoutTime" BU_SG_REL_ VAS_L SG_ 2600468496 NM_Gateway_SNI 2000;
BA_REL_ "GenSigTimeoutTime" BU_SG_REL_ VAS_L SG_ 2600468496 NM_Gateway_CBV_CRI 2000;
BA_REL_ "GenSigTimeoutTime" BU_SG_REL_ VAS_L SG_ 2600468496 NM_Gateway_CAB 2000;
BA_REL_ "GenSigTimeoutTime" BU_SG_REL_ VAS_L SG_ 2600468550 NM_Klima_SNI 2000;
BA_REL_ "GenSigTimeoutTime" BU_SG_REL_ VAS_L SG_ 2600468550 NM_Klima_CBV_CRI 2000;
BA_REL_ "GenSigTimeoutTime" BU_SG_REL_ VAS_L SG_ 2600468550 NM_Klima_CAB 2000;
BA_REL_ "GenSigTimeoutTime" BU_SG_REL_ VAS_L SG_ 2600468569 NM_Lift_VA_SNI 2000;
BA_REL_ "GenSigTimeoutTime" BU_SG_REL_ VAS_L SG_ 2600468569 NM_Lift_VA_CBV_CRI 2000;
BA_REL_ "GenSigTimeoutTime" BU_SG_REL_ VAS_L SG_ 2600468569 NM_Lift_VA_CAB 2000;
BA_REL_ "GenSigTimeoutTime" BU_SG_REL_ VAS_L SG_ 2600468677 NM_VAS_R_SNI 2000;
BA_REL_ "GenSigTimeoutTime" BU_SG_REL_ VAS_L SG_ 2600468677 NM_VAS_R_CBV_CRI 2000;
BA_REL_ "GenSigTimeoutTime" BU_SG_REL_ VAS_L SG_ 2600468677 NM_VAS_R_CAB 2000;
BA_REL_ "GenSigTimeoutTime" BU_SG_REL_ VAS_R SG_ 1635 BEM_02_Abschaltstufen 1000;
BA_REL_ "GenSigTimeoutTime" BU_SG_REL_ VAS_R SG_ 2600468494 NM_BCM1_SNI 2000;
BA_REL_ "GenSigTimeoutTime" BU_SG_REL_ VAS_R SG_ 2600468494 NM_BCM1_CBV_CRI 2000;
BA_REL_ "GenSigTimeoutTime" BU_SG_REL_ VAS_R SG_ 2600468494 NM_BCM1_CAB 2000;
BA_REL_ "GenSigTimeoutTime" BU_SG_REL_ VAS_R SG_ 2600468496 NM_Gateway_SNI 2000;
BA_REL_ "GenSigTimeoutTime" BU_SG_REL_ VAS_R SG_ 2600468496 NM_Gateway_CBV_CRI 2000;
BA_REL_ "GenSigTimeoutTime" BU_SG_REL_ VAS_R SG_ 2600468496 NM_Gateway_CAB 2000;
BA_REL_ "GenSigTimeoutTime" BU_SG_REL_ VAS_R SG_ 2600468550 NM_Klima_SNI 2000;
BA_REL_ "GenSigTimeoutTime" BU_SG_REL_ VAS_R SG_ 2600468550 NM_Klima_CBV_CRI 2000;
BA_REL_ "GenSigTimeoutTime" BU_SG_REL_ VAS_R SG_ 2600468550 NM_Klima_CAB 2000;
BA_REL_ "GenSigTimeoutTime" BU_SG_REL_ VAS_R SG_ 2600468569 NM_Lift_VA_SNI 2000;
BA_REL_ "GenSigTimeoutTime" BU_SG_REL_ VAS_R SG_ 2600468569 NM_Lift_VA_CBV_CRI 2000;
BA_REL_ "GenSigTimeoutTime" BU_SG_REL_ VAS_R SG_ 2600468569 NM_Lift_VA_CAB 2000;
BA_REL_ "GenSigTimeoutTime" BU_SG_REL_ VAS_R SG_ 2600468676 NM_VAS_L_SNI 2000;
BA_REL_ "GenSigTimeoutTime" BU_SG_REL_ VAS_R SG_ 2600468676 NM_VAS_L_CBV_CRI 2000;
BA_REL_ "GenSigTimeoutTime" BU_SG_REL_ VAS_R SG_ 2600468676 NM_VAS_L_CAB 2000;
VAL_ 1648 MO_ANC_Kennfeld_Anf 0 "Kennfeld_1" 1 "Uebergang_Kennfeld_2_nach_1" 2 "Uebergang_Kennfeld_1_nach_2" 3 "Kennfeld_2" ;
VAL_ 1648 MO_Bremslicht_Reku 0 "Aus" 1 "Ein" ;
VAL_ 1648 MO_StartStopp_PopUp 0 "Statuswechsel_ohne_Taster (Init)" 1 "StSt_per_Taster_deaktiviert" 2 "StSt_per_Taster_aktiviert" 3 "nicht verwendet" ;
VAL_ 1648 MO1_Sperr_Info_WFS 0 "nicht_gesperrt" 1 "gesperrt" ;
VAL_ 1648 MO1_Freigabe_Info_WFS 0 "ungueltig" 1 "gueltig" ;
VAL_ 1648 MO_EPCL 0 "EPCL_aus_kein_Text" 1 "EPCL_gelb_Stoerung" 2 "EPCL_gelb_Leistungsbeschraenkung" 3 "EPCL_rot_Fzg_sicher_abstellen" ;
VAL_ 1648 MO_Zylabsch_Texte_02 0 "ein_ZAS_generell_keine_ZAS_Anzeigen" 1 "ZAS_im_VMB" 2 "ZAS_im_ASB_1_Zyl_aktiv" 3 "ZAS_im_ASB_2_Zyl_aktiv" 4 "ZAS_im_ASB_3_Zyl_aktiv" 5 "ZAS_im_ASB_4_Zyl_aktiv" 6 "ZAS_im_ASB_5_Zyl_aktiv" 7 "ZAS_im_ASB_6_Zyl_aktiv" 8 "ZAS_im_ASB_8_Zyl_aktiv" 9 "ZAS_im_ASB_12_Zyl_aktiv" 13 "Uebergangsbetrieb" 14 "keine_ZAS_Anzeige_ggf_Stopp_Schub_Betrieb" 15 "ZAS_Stoerungs_Anzeige" ;
VAL_ 1648 MO_Fahrzeugtyp 0 "Verbrenner_Fahrzeug" 1 "Hybrid" 2 "E_Fahrzeug" 3 "E_Fahrzeug_mit_Range_Extender" 4 "Brennstoffzellenfahrzeug" 5 "tbd" 6 "tbd" 7 "tbd" ;
VAL_ 1648 MO_Abstellzeit 254 "Init" 255 "reserviert" ;
VAL_ 1648 MO_Abstellzeit_Status 0 "Abstellzeit_nicht_berechnet" 1 "Abstellzeit_berechnet" 2 "Abstellzeit_Minimalwert" 3 "Abstellzeit_ungueltig" ;
VAL_ 1648 MO1_Freigabe_Verfallsinfo_WFS 0 "verfaellt_nicht" 1 "verfaellt" ;
VAL_ 1648 MO_Hybrid_StartStopp_LED 0 "LED_aus_und_Blinken_aus" 1 "LED_ein_und_Blinken_aus" 2 "LED_ein_und_Blinken_ein_50_percent" 3 "reserviert" ;
VAL_ 1648 MO_Fehler_Zylabsch 0 "kein_Fehler" 1 "Notlauf_Vollmotorbetrieb" 2 "Notlauf_mindestens_einem_abgesch_Zylinder" ;
VAL_ 1648 MO_Anzahl_Abgesch_Zyl 0 "Vollmotorbetrieb" 1 "1_Zylinder_abgeschaltet" 2 "2_Zylinder_abgeschaltet" 3 "3_Zylinder_abgeschaltet" 4 "4_Zylinder_abgeschaltet" 5 "5_Zylinder_abgeschaltet" 6 "6_Zylinder_abgeschaltet" 7 "8_Zylinder_abgeschaltet" ;
VAL_ 1648 MO_Zylabsch_Texte 0 "keine_Texte" 1 "Zylinderabschaltung_deaktivieren" 2 "Zylinderabschaltung_aktivieren" 3 "Zylinderabschaltung_unruhig" ;
VAL_ 1648 MO_Ethanol_BS_Texte 0 "kein_Text" 1 "E85_Warm_Up" 2 "FlexFuel_Warnung_Stufe_3" 3 "Warmfahrempfehlung_MQB__FlexFuel_Warnung_Stufe_1" 4 "FlexFuel_Warnung_Stufe_2" 5 "FlexFuel_Warnung_Stufe_4" 6 "E25_Warm_Up" ;
VAL_ 1648 MO_Drehzahl_Warnung 0 "keinen_Warnhinweis_anzeigen" 1 "Warnhinweis_anzeigen" ;
VAL_ 1648 MO_obere_Drehzahlgrenze 0 "Init" ;
VAL_ 289 MO_Fahrpedalrohwert_01 255 "Fehler" ;
VAL_ 289 MO_QBit_Fahrpedalwerte_01 0 "gueltiger_Wert" 1 "Ersatz_Init_oder_Fehlerwert" ;
VAL_ 289 MO_Fahrpedalgradient 255 "Fehler" ;
VAL_ 289 MO_Sig_Fahrpedalgradient 0 "Fahrpedalgradient positiv" 1 "Fahrpedalgradient negativ" ;
VAL_ 289 MO_rel_Saugrohrdruck 0 "Init_Ueberdruck" 63 "Fehler" ;
VAL_ 289 MO_rel_Saugrohrdruck_gem_err 0 "errechnet" 1 "gemessen" ;
VAL_ 289 MO_Moment_im_Leerlauf 0 "kein_Leergas" 1 "Leergas" ;
VAL_ 289 MO_Schubabschaltung 0 "keine_Schubabschaltung" 1 "Schubabschaltung_aktiv" ;
VAL_ 289 MO_StartStopp_StoppVorbereitung 0 "Motorstopp_nicht_in_Vorbereitung" 1 "Motorstopp_in_Vorbereitung" ;
VAL_ 289 MO_Entkopplung_Sollschlupf 125 "Notoeffnen_Anfahrelement" 126 "Init" ;
VAL_ 289 MO_temporaere_Fahrerabwesenheit 0 "nicht_erkannt" 1 "erkannt" ;
VAL_ 289 TSK_a_Soll_gradientenbegrenzt 127 "Init_oder_nicht_aktiv" ;
VAL_ 1423 MO_ITM_Status 0 "stehendes_Wasser" 1 "kein_stehendes_Wasser" 2 "Entnahmegrenze_20_Grad_Celsius" 3 "Entnahmegrenze_30_Grad_Celsius" 4 "Entnahmegrenze_40_Grad_Celsius" 5 "Entnahmegrenze_50_Grad_Celsius" 6 "Entnahmegrenze_60_Grad_Celsius" 7 "keine_Entahme_erlaubt" 14 "Init" 15 "Fehler" ;
VAL_ 1423 MO_Tankdruck 254 "Init" 255 "Fehler" ;
VAL_ 1423 MO_Kuehlmittel_Temp_Rohwert 254 "Init" 255 "Fehler" ;
VAL_ 1423 MO_Oel_Temp_Radsatz 254 "Initialwert" 255 "Fehler" ;
VAL_ 1423 MO_KJS_LLK_Pos_Summe 14 "Init" 15 "Pos_Frontendverschl_ungenau" ;
VAL_ 1423 MO_FSA_Sensorheizung 0 "inaktiv" 1 "aktiv" ;
VAL_ 1423 FSA_Fehlerpfade_Initialisieren 0 "inaktiv" 1 "aktiv" ;
VAL_ 1423 MO_SABody_PosLe 0 "Init_nicht_verbaut" 7 "Pos_ungenau" ;
VAL_ 1423 MO_SABody_PosRi 0 "Init_nicht_verbaut" 7 "Pos_ungenau" ;
VAL_ 1423 MO_MMTR_Status 0 "Nicht_verfuegbar" 1 "Inaktiv" 2 "Aktiv_TrackSession" 3 "Aktiv_Endurance" 4 "Aktiv_HotLap" 5 "Nicht_verfuegbar_HotLap" 14 "Init" 15 "Fehler" ;
VAL_ 967 MO_Kuehlerluefter_MUX 0 "Kuehlerluefter_1" 1 "Kuehlerluefter_2" ;
VAL_ 967 MO_Kuehlerluefter_1 126 "Init" 127 "Fehler" ;
VAL_ 967 MO_Kuehlerluefter_2 126 "Init" 127 "Fehler" ;
VAL_ 967 MO_EFLEX_Lampe 0 "Lampe_aus" 1 "Lampe_ein" 2 "Lampe_blinkend" 3 "Lampe_blinkend_mit_Akustik" ;
VAL_ 967 MO_KJS_nicht_bereit 0 "kein_Fehler" 1 "Fehler" ;
VAL_ 967 MO_ITM_Warnung_Pumpe 0 "keine_Warnung" 1 "ITM_Warnung" ;
VAL_ 967 WIV_Anzeige_aktiv 0 "Anzeige aus" 1 "WIV Anzeige aktiv" ;
VAL_ 967 WIV_Oelmin_Warn 0 "in_Ordnung" 1 "Warnung" ;
VAL_ 967 WIV_Sensorfehler 0 "in_Ordnung" 1 "Sensor_defekt" ;
VAL_ 967 WIV_Schieflage 0 "Fahrzeug_gerade" 1 "Fahrzeug_in_Schieflage" ;
VAL_ 967 MO_Zustand_HWP 0 "HWP_nicht_schaltbar" 1 "HWP_foerdert_nicht" 2 "HWP_foerdert" 3 "reserviert" ;
VAL_ 967 OLEV_Systemstoerung 0 "Ölsystem i.O." 1 "Systemstörung Ölsystem" ;
VAL_ 967 MO_Oelwarnung_max 0 "keine_Warnung" 1 "Warnfall_aktiv" ;
VAL_ 967 WIV_Oelsystem_aktiv 0 "Anzeige_aus" 1 "Anzeige_aktiv" ;
VAL_ 967 WIV_nicht_betriebswarm 0 "Motor_warm" 1 "Motor_nicht_betriebswarm" ;
VAL_ 967 WIV_Ueberfuell_Warn 0 "in_Ordnung" 1 "Ueberfuellwarnung" ;
VAL_ 967 WIV_laufender_Motor 0 "Messung_moeglich" 1 "Messung_nicht_moeglich" ;
VAL_ 967 MO_E_Warnungen 0 "keine_Anzeige" 1 "Fehler_Elektrosystem_Anhalten" 2 "Fehler_Elektrosystem_Werkstatt" 3 "Elektrosystem_ueberhitzt_Stopp" 4 "Fehler_Hybridsystem_Anhalten" 5 "Fehler_Hybridsystem_Werkstatt" 6 "Fehler_Wasserstoffsystem_Anhalte" 7 "Fehler_Wasserstoffsystem_Werksta" 8 "reserviert_keine_Anzeige" 9 "reserviert_keine_Anzeige" 10 "reserviert_keine_Anzeige" 11 "reserviert_keine_Anzeige" 12 "reserviert_keine_Anzeige" 13 "reserviert_keine_Anzeige" 14 "reserviert_keine_Anzeige" 15 "reserviert_keine_Anzeige" ;
VAL_ 967 MO_Text_Motorstart 0 "keine_Anzeige" 1 "Motor_im_Stoppbetrieb" 2 "StartStopp_sicherheitsbedingt_deaktiviert" 3 "System_fordert_Wiederstart" 4 "Aufforderung_Motorstart" 5 "Motorlauf_noetig" 6 "Motorlaufwarnung" 9 "Unerwuenschter_Motorstillstand" 10 "Motorstart_nicht_moeglich" 11 "Fehler_Kupplungsschalter" 12 "Motor_startet" 13 "Kupplung_betaetigen" 14 "Waehlhebel_in_PN_Position" 15 "Bremse_treten" ;
VAL_ 967 MO_E_Texte 0 "keine_Anzeige" 1 "Batterie_fast_leer" 2 "Ladestecker_nicht_fahrbereit" 3 "VM_Betrieb_erforderlich" 4 "Batterie_laedt_Nicht_ausschalten" 5 "Bitte_Bremse_treten" 6 "manueller_Neustart_erforderlich" 7 "Stopp_Fahrzeug_nicht_abschleppen" 8 "kein_Neustart_Haube_nicht_oeffnen" 9 "Motorstart_im_naechsten_Zyklus" 10 "VM_erforderlich_EVMode_abwaehlen" 11 "laengerer_VMBetrieb_Bordbuch" 12 "Tank_leer_VM_nicht_verfuegbar" 13 "Bitte_warten_Motor_startet" 14 "kein_Start_Batterietemperatur" 15 "Ende_elektrische_Reichweite_erreicht" ;
VAL_ 967 WIV_Oeldyn_avl 0 "Oeldyn_nicht_vorhanden" 1 "Oeldyn_vorhanden" ;
VAL_ 967 OLEV_Oelstand_nicht_vorhanden 0 "Ölstand vorhanden" 1 "Ölstand nicht vorhanden" ;
VAL_ 967 MO_Systemlampe 0 "Lampe aus" 1 "Lampe ein" ;
VAL_ 967 MO_OBD2_Lampe 0 "Lampe aus" 1 "Lampe ein" ;
VAL_ 967 MO_Heissleuchte 0 "Lampe aus" 1 "Lampe ein" ;
VAL_ 967 MO_Partikel_Lampe 0 "Lampe aus" 1 "Lampe ein" ;
VAL_ 967 MO_RedFahrleistung_Lampe 0 "Lampe_aus" 1 "Lampe_ein" ;
VAL_ 967 WIV_Oelstand_nicht_vorhanden 0 "Ölstand vorhanden" 1 "Ölstand nicht vorhanden" ;
VAL_ 967 WIV_nachfuellanzeige_ein 0 "keine_Nachfuellanzeige" 1 "Nachfuellanzeige" ;
VAL_ 967 WIV_Ueberfuell_deaktiv 0 "Ueberfuellwarnung_am_Kombi_aktiv" 1 "Ueberfuellwarnung_am_Kombi_deaktiv" ;
VAL_ 967 WIV_Unterfuell_Warn 0 "in_Ordnung" 1 "Unterfuellwarnung" ;
VAL_ 967 MO_Tankdeckel_Lampe 0 "Lampe aus" 1 "Lampe ein" ;
VAL_ 967 MO_Text_Tankdeckelwarn 0 "kein_Text" 1 "Anzeige_Text_Tankdeckelwarnung_im_Kombi" ;
VAL_ 967 MO_Vorglueh_Lampe 0 "Lampe_aus" 1 "Lampe_ein" ;
VAL_ 967 WIV_Oeldr_Warn_Motor 0 "keine_Warnung" 1 "niedrige_Oeldruckstufe_nicht_erreicht" ;
VAL_ 967 MO_E_Mode 0 "keine_Anzeige" 1 "E_Mode_passiv" 2 "E_Mode_aktiv" 3 "E_Mode_inaktiv_nicht_verfuegbar" 4 "E_Mode_aktiv_nicht_verfuegbar" 5 "reserviert_keine_Anzeige" 6 "reserviert_keine_Anzeige" 7 "reserviert_keine_Anzeige" ;
VAL_ 340 MO_IstMoment_VKM 1022 "Init" ;
VAL_ 340 MO_Mom_Begr_Schalt 1022 "Init" ;
VAL_ 340 MO_Mom_Begr_Schalt_Min 1022 "Init" ;
VAL_ 340 MO_Fehlerstatus_Antrieb_FDR 0 "FDR_Normalbetrieb" 1 "FDR_abschalten" 2 "FDR_Regelung_beenden" 3 "FDR_abschalten_temporaer" 4 "FDR_Regelung_temporaer_beenden" ;
VAL_ 340 MO_Primaerachse_Anforderung 0 "Init_Freilaufsteuerung_MSG" 1 "Anforderung_Abkoppeln" 2 "Anforderung_Ankoppeln" 3 "Anforderung_Abkoppeln_Katheizen" ;
VAL_ 283 MO_Fahrbereitschaft 0 "Fahrzykl_inaktiv__kein_Antrieb" 1 "Fahrzykl_aktiv__kein_Antrieb" 2 "Fahrzykl_aktiv__Antrieb_moeglich" ;
VAL_ 283 MO_Freilauf_Info 0 "Freilauf_freigegeben" 1 "Weiches_Veto_uebertippbar" 2 "Hartes_Veto_Abbruch" 3 "Freilauf_Anforderung" ;
VAL_ 283 MO_Krit_Heckobjekt 0 "Init_kein_relevantes_Objekt" 1 "Entfernung_grosser_Abstand" 2 "Annaeherung_grosser_Abstand" 3 "Entfernung_geringer_Abstand" 4 "Annaeherung_geringer_Abstand" 7 "Fehler" ;
VAL_ 283 MO_NGS_Gangpos 0 "nicht_bedient" 1 "1_3_oder_5" 2 "2_4_6_oder_R" 3 "R" 4 "Neutralposition" 5 "Zwischenposition" 6 "Sensor_temp_nicht_verfuegbar" 7 "Fehler" ;
VAL_ 283 MO_Freilauf_Status 0 "Freilauf_inaktiv_aber_moeglich" 1 "Freilauf_aktiv" 2 "Freilauf_nicht_moegl_1Verhinderer" 3 "Freilauf_nicht_moegl_gr_1Verhinderer" 7 "Fehler" ;
VAL_ 283 MO_EBoost_verf_praed 0 "Init_oder_nicht_verfuegbar" 1 "EBoost_kurzzeit_verfuegbar" 2 "EBoost_langzeit_verfuegbar" ;
VAL_ 283 MO_Heckspoiler_Anf 0 "nicht_angefordert" 1 "angefordert" ;
VAL_ 283 MO_eLaunch_verf 0 "Init" 1 "nicht_verfuegbar" 2 "verfuegbar" ;
VAL_ 283 MO_Positionierung_aktiv 0 "keine_Positionierung_aktiv" 1 "Positionierung_aktiv" ;
VAL_ 283 MO_Parken_WFS_Status 0 "Limitierung_Inaktiv" 1 "Limitierung_Aktiv" 2 "Abbruch" ;
VAL_ 283 MO_Status_Katheizen 0 "Katheizen_nicht_aktiv" 1 "Katheizen_aktiv" ;
VAL_ 283 MO_Status_MIN_Wunschdrehzahl 0 "keine_OBD_oder_CSERS_Anforderung" 1 "CSERS_Anforderung" 2 "OBD_Anforderung_ausserhalb_CSERS" 3 "reserviert" ;
VAL_ 283 MO_Rennstart_verf 0 "nicht_verfuegbar" 1 "verfuegbar" ;
VAL_ 283 MO_AIAD_MaxLeistung 255 "Init" ;
VAL_ 1601 MO_Faktor_Momente_02 0 "nicht_belegt" ;
VAL_ 1601 MO_Hybridfahrzeug 0 "kein_Hybridfahrzeug" 1 "Mild_Hybrid" 2 "Full_Hybrid" 3 "PlugIn_Hybrid" ;
VAL_ 1601 MO_Getriebe_Code 0 "Init" 2 "DL501" 3 "DL800" 4 "VL381" 5 "DL382_Front" 6 "DL382_Allrad" 7 "DL702" 8 "AL552_Allrad" 9 "AL552_Front" 10 "AL651" 11 "AL551__AL951__AL1000_8A" 12 "PDK_PAG" 13 "AL551_Hybrid" 15 "Handschalter_konventionell" 16 "AQ250_160" 17 "AQ450" 18 "DQ200" 19 "DQ250" 20 "DQ500" 21 "SQ100" 22 "SQ200" 23 "DQ400E" 24 "DQ381" 25 "AL550" 26 "AQ300" 31 "DL800E" 32 "Single_Gear__ohne_GSG_WH_am_MSG" 33 "EQ550_2P" ;
VAL_ 1601 MO_StartStopp_Codiert 0 "Start_Stopp_nicht_verbaut" 1 "Start_Stopp_verbaut" ;
VAL_ 1601 MO_Anzeige_StSt_gueltig 0 "MO_Text_Motorstart_gueltig" 1 "Signale_MO_Anzeige_StSt_gueltig" ;
VAL_ 1601 MO_Anzahl_Zyl 0 "kein_Zylinder" 1 "1_Zylinder" 2 "2_Zylinder" 3 "3_Zylinder" 4 "4_Zylinder" 5 "5_Zylinder" 6 "6_Zylinder" 7 "7_Zylinder" 8 "8_Zylinder" 9 "9_Zylinder" 10 "10_Zylinder" 11 "11_Zylinder" 12 "12_Zylinder" 13 "15_Zylinder" 14 "16_Zylinder" 15 "18_Zylinder" ;
VAL_ 1601 MO_Kraftstoffart 0 "Diesel" 1 "Benzin_inkl_E25_E85" 2 "CNG" 3 "LPG" 4 "Wasserstoff" 5 "E100_Ethanol" 15 "kein_Verbrennungskraftstoff" ;
VAL_ 1601 MO_Ansaugsystem 0 "Turbo" 1 "Sauger" ;
VAL_ 1601 MO_OBD_Typ 0 "NoOBD_RdW" 1 "EOBD" 2 "US_OBD" 3 "reserviert" ;
VAL_ 1601 MO_DPF_verbaut 0 "kein_DPF_verbaut" 1 "DPF_verbaut" ;
VAL_ 1601 TSK_Codierung 0 "kein_Fahrgeschwindigkeitsregler" 1 "GRA" 2 "GRA_Plus" 3 "Basis_ACC" 4 "ACC_Follow_to_Stop" 5 "ACC_Stop_and_Go" 7 "Codierung_in_Plausibilisierungsphase" ;
VAL_ 394 MO_Ablaufstatus 0 "keine_Aktion" 1 "Aktion_regulaerer_Uebergang" 2 "Aktion_regulaerer_Uebergang" 3 "Aktion_regulaerer_Uebergang" 4 "Aktion_regulaerer_Uebergang" 5 "Aktion_regulaerer_Uebergang" 6 "Aktion_regulaerer_Uebergang" 7 "Aktion_regulaerer_Uebergang" 8 "regulaerer_Uebergang_fertig" 9 "Aktion_Abbruch_Uebergang" 10 "Aktion_Abbruch_Uebergang" 11 "Aktion_Abbruch_Uebergang" 12 "Aktion_Abbruch_Uebergang" 13 "Aktion_Abbruch_Uebergang" 14 "Abbruch_Uebergang_fertig" 15 "Fehler" ;
VAL_ 394 MO_Ablaufstrg_Betriebszustand 0 "Init_Nicht_Betriebsbereit" 1 "Betriebsbereitschaft" 2 "Fahrbetrieb" 7 "Fehler" ;
VAL_ 394 MO_Ablaufstrg_Zustand_VKM_Ist 0 "VKM_aus" 1 "VKM_ein" ;
VAL_ 394 MO_Ablaufstrg_Kraftschluss_Ist 0 "kein_Kraftschluss" 1 "Kraftschluss" ;
VAL_ 394 MO_Ablaufstrg_Zustand_K0_Ist 0 "K0_Kupplung_auf" 1 "K0_Kupplung_zu" ;
VAL_ 394 MO_Ablaufstrg_Kraftschluss2_Ist 0 "Sekundärachse abgekoppelt" 1 "Sekundärachse angekoppelt" ;
VAL_ 394 MO_HYB_LowSpeedModus 0 "LowSpeed_mit_LLDZ" 1 "LowSpeed_ohne_LLDZ" ;
VAL_ 394 MO_Ablaufstrg_Zustand_VKM_Ziel 0 "VKM_aus" 1 "VKM_ein" ;
VAL_ 394 MO_Ablaufstrg_Kraftschluss_Ziel 0 "kein_Kraftschluss" 1 "Kraftschluss" ;
VAL_ 394 MO_Ablaufstrg_Zustand_K0_Ziel 0 "K0_Kupplung_auf" 1 "K0_Kupplung_zu" ;
VAL_ 394 MO_Ablaufstrg_Kraftschluss2_Ziel 0 "Anforderung Sekundaerachse abkoppeln" 1 "Anforderung Sekundaerachse ankoppeln" ;
VAL_ 394 MO_HYB_Stoppmodus 0 "Softstopp" 1 "Dynamikstopp" ;
VAL_ 394 MO_Auth_Aufforderung_WFS 0 "Aus" 1 "Ein" ;
VAL_ 394 MO_Start_Dynamik 0 "Kein_Start" 1 "VKM_IDLE_Start" 2 "Softstart_Schubankoppeln_unbefeu" 3 "Komfortstart_befeuert" 4 "Dynamikstart_befeuert" 5 "Sportstart_befeuert" 6 "plausibilisierter_Schleppstart" 7 "Notstart" ;
VAL_ 394 MO_Start_Art 0 "Init" 1 "Zustarteinrichtung" 2 "Schlupfstart" 3 "Schleppstart" ;
VAL_ 394 MO_Abstellposition_02 255 "Abstellposition_ungenau" ;
VAL_ 394 MO_Mom_Freiheit_Sekundaerachse 0 "Sekundaerachse ist nicht momentenfrei" 1 "Sekundaerachse ist momentenfrei" ;
VAL_ 394 MO_Tankklappensteuerung 0 "Init_nicht_verbaut" 1 "Tankklappe_soll_entriegeln" 2 "Tankklappe_soll_verriegeln" 3 "keine_Aktion" ;
VAL_ 394 MO_HYB_E_Faktor 0 "null" 1 "plus_1" 2 "plus_2" 3 "plus_3" 4 "plus_4" 5 "plus_5" 6 "plus_6" 7 "plus_7" 8 "minus_8" 9 "minus_7" 10 "minus_6" 11 "minus_5" 12 "minus_4" 13 "minus_3" 14 "minus_2" 15 "minus_1" ;
VAL_ 394 MO_HYB_EMode_Info 0 "Normal_Mode" 1 "Depleting_Mode" 2 "Charge_Mode" 3 "Sonder_Schaltprogramm" ;
VAL_ 394 MO_HYB_Adaption_aktiv 0 "Keine_Adaption_aktiv" 1 "Adaption_aktiv" ;
VAL_ 1156 ND_VDOP 1022 "Init" 1023 "Fehler" ;
VAL_ 1156 ND_TDOP 1022 "Init" 1023 "Fehler" ;
VAL_ 1156 ND_HDOP 1022 "Init" 1023 "Fehler" ;
VAL_ 1156 ND_GDOP 1022 "Init" 1023 "Fehler" ;
VAL_ 1156 ND_PDOP 1022 "Init" 1023 "Fehler" ;
VAL_ 1156 ND_Heading 4094 "Init" 4095 "Fehler" ;
VAL_ 1156 ND_Init 0 "nicht_Initialisiert" 1 "Initialisiert" ;
VAL_ 1157 ND_SatInUse 30 "Init" 31 "Fehler" ;
VAL_ 1157 POS_Guete_horizontal_verfuegbar 0 "nicht_verfuegbar" 1 "verfuegbar" ;
VAL_ 1157 ND_SatInView 30 "Init" 31 "Fehler" ;
VAL_ 1157 POS_Guete_horizontal 124 "von_248m_bis_400m" 125 "mehr_als_400m" 126 "Init" 127 "Fehler" ;
VAL_ 1157 NP_Altitude 4094 "Init" 4095 "Fehler" ;
VAL_ 2527679512 ND_Timezone_Offset 14 "Init" 15 "Fehler" ;
VAL_ 2527679512 ND_Timezone_SignBit 0 "PLUS_Vorzeichen" 1 "MINUS_Vorzeichen" ;
VAL_ 2527679512 ND_Timezone_Validity 0 "invalid" 1 "valid" ;
VAL_ 2527679512 ND_TimeToDestination 510 "Fehler" 511 "Init" ;
VAL_ 2527679512 ND_RouteType 0 "keine_Zielfuehrung_oder_MPR_aktiv" 1 "MPR_aktiv" 2 "Zielfuehrung_aktiv" 3 "reserviert" ;
VAL_ 2527679512 ND_TimeOffset 0 "Ziel_in_gleicher_Zeitzone" 1 "Ziel_in_Zeitzone_plus_1" 2 "Ziel_in_Zeitzone_minus_1" 3 "Zielzeitzone_groesser_plus_minus_1" ;
VAL_ 2527679512 ND_Fuelstation_detected 0 "nicht_verbaut" 1 "Tankstelle_nicht_erkannt" 2 "Tankstelle_erkannt" 3 "Init" ;
VAL_ 2527679512 ND_Velocity 1022 "Init" 1023 "Fehler" ;
VAL_ 2527679512 ND_RecDelay 4094 "Init" 4095 "Fehler" ;
VAL_ 2527679512 ND_SendDelay 4094 "Init" 4095 "Fehler" ;
VAL_ 1158 NP_LatDegree 134217726 "Init" 134217727 "Fehler" ;
VAL_ 1158 NP_LongDegree 268435454 "Init" 268435455 "Fehler" ;
VAL_ 1158 NP_LatDirection 0 "Nord" 1 "Sued" ;
VAL_ 1158 NP_LongDirection 0 "Ost" 1 "West" ;
VAL_ 1158 NP_Sat 30 "Init" 31 "Fehler" ;
VAL_ 1158 NP_Fix 0 "Init" 1 "No_Fix" 2 "2D_Fix" 3 "3D_Fix" ;
VAL_ 2589283496 POS_MUX 0 "MUX_0" 1 "MUX_1" 2 "reserved" 3 "Init" ;
VAL_ 2589283496 POS_ODD_EVEN 0 "ODD" 1 "EVEN" ;
VAL_ 2589283496 POS_PosStati 0 "Init" 1 "NoNavAvailable" 2 "NoMapAvailable" 3 "NavBooting" 4 "NavError" 5 "NavCalibrating" 6 "NavNoGpsResyncSince1h" 7 "NavOffroadParkgarageRampOffset2" 8 "DeadReckoningWithoutGps" 9 "DeadReckoningWithGps" 10 "MapMatchedLowConfidence" 11 "MapMatchedLimitedConfidence" 12 "OffroadHighConfidence" 13 "MapMatchedHighConfidence" 14 "PosInSyncWithGpsAndMAP" ;
VAL_ 2589283496 POS_LatDirection 0 "North" 1 "South" ;
VAL_ 2589283496 POS_LatDegree 134217726 "Init" 134217727 "Fehler" ;
VAL_ 2589283496 POS_Heading_Trust 0 "Init" 1 "TrustLevel01" 2 "TrustLevel02" 3 "Fehler" ;
VAL_ 2589283496 POS_LongDirection 0 "East" 1 "West" ;
VAL_ 2589283496 POS_LongDegree 268435454 "Init" 268435455 "Fehler" ;
VAL_ 2527679647 Stellgliedtest_NFC 0 "Init_kein_Stellgliedtest" 1 "Stellgliedtest_angefordert" ;
VAL_ 2527679647 NFC_ESM_aktivieren 0 "Init_kein_ESM" 1 "ESM_aktivieren" ;
VAL_ 2527679647 ZV_auf_NFC 0 "Init_keine_Meldung" 1 "ZV_auf_NFC" ;
VAL_ 2527679647 ZV_zu_NFC 0 "Init_keine_Meldung" 1 "ZV_zu_NFC" ;
VAL_ 2527679647 NFC_Front_Verr_Authorisiert 0 "kein_NFC_Handy_erkannt" 1 "NFC_Handy_erkannt_und_authorisiert" ;
VAL_ 2527679647 NFC_Front_Entr_Authorisiert 0 "kein_NFC_Handy_erkannt" 1 "NFC_Handy_erkannt_und_authorisiert" ;
VAL_ 2527679647 NFC_HD_Verriegelung_Authorisiert 0 "kein_NFC_Handy_erkannt" 1 "NFC_Handy_erkannt_und_authorisiert" ;
VAL_ 2527679647 NFC_HD_Entriegelung_Authorisiert 0 "kein_NFC_Handy_erkannt" 1 "NFC_Handy_erkannt_und_authorisiert" ;
VAL_ 2527679647 NFC_aktiv 0 "NFC_nicht_aktiv" 1 "NFC_Kommunikation_aktiv" ;
VAL_ 2527679647 NFC_Laden_unterbrechen 0 "Laden_nicht_unterbrechen" 1 "Laden_unterbrechen" ;
VAL_ 2527679647 NFC_FT_Entriegelung_Authorisiert 0 "kein_NFC_Handy_erkannt" 1 "NFC_Handy_erkannt_und_authorisie" ;
VAL_ 2527679647 NFC_FT_Verriegelung_Authorisiert 0 "kein_NFC_Handy_erkannt" 1 "NFC_Handy_erkannt_und_authorisiert" ;
VAL_ 1696 NV_aktiv 0 "NV nicht aktiv" 1 "NV aktiv" ;
VAL_ 1696 NV_Texte 0 "Init" 1 "Abblendlicht_einschalten" 2 "Fussgaengermarkierung_n_v" 3 "zur_Zeit_nicht_verfuegbar" 4 "Systemfehler" 5 "Fussgaengermarkierung_deakt" 6 "Blindheit_erkannt" 7 "kein_Text" ;
VAL_ 1696 NV_Gong 0 "kein_Gong" 1 "Gong_leise" 2 "Gong_mittel" 3 "Gong_laut" ;
VAL_ 1696 NV_Symbol 0 "kein_Symbol_anzeigen" 1 "Symbol_fuer_erkanntes_Objekt_anzeigen" ;
VAL_ 1696 NV_Hinweise 0 "keine_Anzeige" 1 "Disclaimer" 2 "Fussgaenger_Markierung_nicht_verfuegbar" 3 "Nachtsichtsystem_wird_initialisiert" ;
VAL_ 1696 NV_Piktogramm_aktiv 0 "keine_Anzeigenprioritaet" 1 "Anzeigenprioritaet" ;
VAL_ 1696 NV_Akustik_deaktiviert_Icon 0 "aus" 1 "ein" ;
VAL_ 1696 NV_FGM_deaktiviert_Icon 0 "aus" 1 "ein" ;
VAL_ 1696 NV_Markierungslicht_links 0 "Aus" 1 "Ein" ;
VAL_ 1696 NV_Markierungslicht_rechts 0 "Aus" 1 "Ein" ;
VAL_ 1696 NV_Symbol_Tierwarnung 0 "Aus" 1 "Ein" ;
VAL_ 1696 NV_Anf_Prefill 0 "nicht_angefordert" 1 "angefordert" ;
VAL_ 1696 NV_HBA_Parameter 0 "Defaultparametersatz" 1 "Parametersatz_mit_leicht_erhoehter_Empfindlichkeit" 2 "Parametersatz_mit_erhoehter_Empfindlichkeit" 3 "Parametersatz_mit_hoechster_Empfindlichkeit" ;
VAL_ 1696 NV_LED_Leiste 0 "AUS_keine_Anzeige" 1 "Stufe_1_glimmen" 2 "Stufe_2_leuchten" 3 "Stufe_3_blinken" ;
VAL_ 1696 NV_PreSense_Status 0 "Init" 1 "verfuegbar" 2 "nicht_verfuegbar" ;
VAL_ 1696 NV_PreSense_Modus_System 0 "deaktiviert" 1 "aktiviert" ;
VAL_ 1696 NV_PreSense_Modus_Warnung 0 "Aus" 1 "Setting_2" 2 "Setting_3" 3 "Setting_4" 4 "Setting_5" 5 "Ein" ;
VAL_ 1696 NV_FAS_Fkt_Status 0 "Init" 1 "Funktion_Ist_Ein" 2 "Funktion_Ist_Aus" 3 "Fehler" ;
VAL_ 1696 NV_Akt_Status_MMI 0 "deaktiviert" 1 "aktiviert" 3 "Init" ;
VAL_ 1696 NV_AnforderungBildaufschaltung 0 "KeineBildaufschaltung" 1 "Bildaufschaltung" ;
VAL_ 2600468494 NM_BCM1_SNI 14 "BCM1" ;
VAL_ 2600468494 NM_BCM1_CBV_AWB 0 "Passiver_WakeUp" 1 "Aktiver_WakeUp" ;
VAL_ 2600468494 NM_BCM1_CBV_CRI 0 "NM_ohne_Clusteranforderungen" 1 "NM_mit_Clusteranforderungen" ;
VAL_ 2600468494 NM_BCM1_NM_State 0 "Init" 1 "NM_RM_aus_BSM" 2 "NM_RM_aus_PBSM" 4 "NM_NO_aus_RM" 8 "NM_NO_aus_RS" 16 "reserved" 32 "reserved" ;
VAL_ 2600468494 NM_BCM1_Car_Wakeup 0 "Inaktiv" 1 "Car_Wakeup" ;
VAL_ 2600468494 NM_BCM1_UDS_CC 0 "Inaktiv" 1 "CC_aktiv" ;
VAL_ 2600468494 NM_BCM1_NM_aktiv_KL15 0 "Inaktiv" 1 "KL15_EIN" ;
VAL_ 2600468494 NM_BCM1_NM_aktiv_Diagnose 0 "Init" 1 "Diagnose_aktiv" ;
VAL_ 2600468494 NM_BCM1_NM_aktiv_Tmin 0 "Inaktiv" 1 "Mindestaktivzeit" ;
VAL_ 2600468494 NM_BCM1_NM_aktiv_Notlaufblinken 1 "Notlaufblinken_aktiv" ;
VAL_ 2600468494 NM_BCM1_NM_aktiv_ComingHome 1 "ComingHome_aktiv" ;
VAL_ 2600468494 NM_BCM1_NM_aktiv_LeavingHome 1 "LeavingHome_aktiv" ;
VAL_ 2600468494 NM_BCM1_NM_aktiv_Taster_Schalter 0 "inaktiv" 1 "Nachlauf_aktiv" ;
VAL_ 2600468494 NM_BCM1_NM_aktiv_LIM 0 "inaktiv" 1 "LIM_aktiv" ;
VAL_ 2600468494 NM_BCM1_NM_aktiv_Innenlicht_Dim 0 "inaktiv" 1 "Innenlicht_Dimmung_aktiv" ;
VAL_ 2600468494 NM_BCM1_NM_aktiv_Aussenlicht 0 "Init" 1 "Aussenlicht_aktiv" ;
VAL_ 2600468494 NM_BCM1_NM_aktiv_Klimatisierung 0 "inaktiv" 1 "Klimatisierung_aktiv" ;
VAL_ 2600468494 NM_BCM1_CAB 0 "inaktiv" 1 "CAB_01__Tueren" 2 "CAB_02__Anhaenger_KCAN" 4 "CAB_03__Nightvision" 8 "CAB_04__Sitzverstellung" 16 "CAB_05__Klappen" 32 "CAB_06__Infotainment" 64 "CAB_07__Sub_Infotainment" 128 "CAB_08__Anzeige" 256 "CAB_09__Laden_HCAN" 512 "CAB_10__Klima" 1024 "CAB_11__FlexRay" 262144 "CAB_19__VLAN_RemoteFC" 524288 "CAB_20__VLAN_Komfort" 1048576 "CAB_21__VLAN_Internet" 2097152 "CAB_22__VLAN_Connect" 4194304 "CAB_23__VLAN_Infotainment" 8388608 "CAB_24__VLAN_FAS" ;
VAL_ 2600468496 NM_Gateway_SNI 16 "Gateway" ;
VAL_ 2600468496 NM_Gateway_CBV_AWB 0 "Passiver_WakeUp" 1 "Aktiver_WakeUp" ;
VAL_ 2600468496 NM_Gateway_CBV_CRI 0 "NM_ohne_Clusteranforderungen" 1 "NM_mit_Clusteranforderungen" ;
VAL_ 2600468496 NM_Gateway_NM_State 0 "Init" 1 "NM_RM_aus_BSM" 2 "NM_RM_aus_PBSM" 4 "NM_NO_aus_RM" 8 "NM_NO_aus_RS" 16 "reserved" 32 "reserved" ;
VAL_ 2600468496 NM_Gateway_Car_Wakeup 0 "Inaktiv" 1 "Car_Wakeup" ;
VAL_ 2600468496 NM_Gateway_UDS_CC 0 "Inaktiv" 1 "CC_aktiv" ;
VAL_ 2600468496 NM_Gateway_NM_aktiv_KL15 0 "Inaktiv" 1 "KL15_EIN" ;
VAL_ 2600468496 NM_Gateway_NM_aktiv_Diagnose 0 "Init" 1 "Diagnose_aktiv" ;
VAL_ 2600468496 NM_Gateway_NM_aktiv_Tmin 0 "Inaktiv" 1 "Mindestaktivzeit" ;
VAL_ 2600468496 NM_Gateway_NM_aktiv_CWU 0 "kein_CWU_gesetzt" 1 "CWU_gesetzt" ;
VAL_ 2600468496 NM_Gateway_NM_aktiv_FC 0 "kein_FC_gesetzt" 1 "FC_gesetzt" ;
VAL_ 2600468496 NM_Gateway_NM_aktiv_Connect 0 "inaktiv" 1 "Nachlauf_aufgrund_Connect" ;
VAL_ 2600468496 NM_Gateway_NM_aktiv_EM 0 "inaktiv" 1 "Nachlauf_aufgrund_Energiemanagement" ;
VAL_ 2600468496 NM_Gateway_NM_aktiv_OBDC 0 "kein_Nachlauf" 1 "Nachlauf_aufgrund_OBDC" ;
VAL_ 2600468496 NM_Gateway_NM_aktiv_Buskopplung 0 "inaktiv" 1 "Nachlauf_aufgrund_Buskopplung" ;
VAL_ 2600468496 NM_Gateway_NM_aktiv_LIN2 0 "Inaktiv" 1 "LIN2_aktiv" ;
VAL_ 2600468496 NM_Gateway_NM_aktiv_Fremdladung 0 "inaktiv" 1 "Nachlauf_aufgrund_Connect" ;
VAL_ 2600468496 NM_Gateway_CAB 0 "inaktiv" 1 "CAB_01__Tueren" 2 "CAB_02__Anhaenger_KCAN" 4 "CAB_03__Nightvision" 8 "CAB_04__Sitzverstellung" 16 "CAB_05__Klappen" 32 "CAB_06__Infotainment" 64 "CAB_07__Sub_Infotainment" 128 "CAB_08__Anzeige" 256 "CAB_09__Laden_HCAN" 512 "CAB_10__Klima" 1024 "CAB_11__FlexRay" 262144 "CAB_19__VLAN_RemoteFC" 524288 "CAB_20__VLAN_Komfort" 1048576 "CAB_21__VLAN_Internet" 2097152 "CAB_22__VLAN_Connect" 4194304 "CAB_23__VLAN_Infotainment" 8388608 "CAB_24__VLAN_FAS" ;
VAL_ 2600468550 NM_Klima_SNI 70 "Klima" ;
VAL_ 2600468550 NM_Klima_CBV_AWB 0 "Passiver_WakeUp" 1 "Aktiver_WakeUp" ;
VAL_ 2600468550 NM_Klima_CBV_CRI 0 "Standard_Layout" 1 "TNB_Layout" ;
VAL_ 2600468550 NM_Klima_NM_State 0 "Init" 1 "NM_RM_aus_BSM" 2 "NM_RM_aus_PBSM" 4 "NM_NO_aus_RM" 8 "NM_NO_aus_RS" 16 "reserved" 32 "reserved" ;
VAL_ 2600468550 NM_Klima_Car_Wakeup 0 "Inaktiv" 1 "Car_Wakeup" ;
VAL_ 2600468550 NM_Klima_UDS_CC 0 "Init" 1 "CC_aktiv" ;
VAL_ 2600468550 NM_Klima_NM_aktiv_KL15 0 "Inaktiv" 1 "KL15_EIN" ;
VAL_ 2600468550 NM_Klima_NM_aktiv_Diagnose 0 "Init" 1 "Diagnose_aktiv" ;
VAL_ 2600468550 NM_Klima_NM_aktiv_Tmin 0 "Inaktiv" 1 "Mindestaktivzeit" ;
VAL_ 2600468550 NM_Klima_NM_aktiv_Abstellzstd 0 "inaktiv" 1 "Abstellzustand_aktiv" ;
VAL_ 2600468550 NM_Klima_CAB 0 "inaktiv" 1 "CAB_01__Tueren" 2 "CAB_02__Anhaenger_KCAN" 4 "CAB_03__Nightvision" 8 "CAB_04__Sitzverstellung" 16 "CAB_05__Klappen" 32 "CAB_06__Infotainment" 64 "CAB_07__Sub_Infotainment" 128 "CAB_08__Anzeige" 256 "CAB_09__Laden_HCAN" 512 "CAB_10__Klima" 1024 "CAB_11__FlexRay" 262144 "CAB_19__VLAN_RemoteFC" 524288 "CAB_20__VLAN_Komfort" 1048576 "CAB_21__VLAN_Internet" 2097152 "CAB_22__VLAN_Connect" 4194304 "CAB_23__VLAN_Infotainment" 8388608 "CAB_24__VLAN_FAS" ;
VAL_ 2600468569 NM_Lift_VA_SNI 89 "Lift_VA" ;
VAL_ 2600468569 NM_Lift_VA_CBV_AWB 0 "Passiver_WakeUp" 1 "Aktiver_WakeUp" ;
VAL_ 2600468569 NM_Lift_VA_CBV_CRI 0 "Standard_Layout" 1 "TNB_Layout" ;
VAL_ 2600468569 NM_Lift_VA_NM_State 1 "NM_RM_aus_BSM" 2 "NM_RM_aus_PBSM" 4 "NM_NO_aus_RM" 8 "NM_NO_aus_RS" ;
VAL_ 2600468569 NM_Lift_VA_Car_Wakeup 0 "Inaktiv" 1 "Car_Wakeup" ;
VAL_ 2600468569 NM_Lift_VA_UDS_CC 1 "CC_aktiv" ;
VAL_ 2600468569 NM_Lift_VA_NM_aktiv_KL15 0 "Inaktiv" 1 "KL15_EIN" ;
VAL_ 2600468569 NM_Lift_VA_NM_aktiv_Diag 0 "Inaktiv" 1 "Diagnose_aktiv" ;
VAL_ 2600468569 NM_Lift_VA_NM_aktiv_Tmin 0 "Inaktiv" 1 "Mindestaktivzeit" ;
VAL_ 2600468569 NM_Lift_VA_CAB 0 "inaktiv" 1 "CAB_01__Tueren" 2 "CAB_02__Anhaenger_KCAN" 4 "CAB_03__Nightvision" 8 "CAB_04__Sitzverstellung" 16 "CAB_05__Klappen" 32 "CAB_06__Infotainment" 64 "CAB_07__Sub_Infotainment" 128 "CAB_08__Anzeige" 256 "CAB_09__Laden_HCAN" 512 "CAB_10__Klima" 1024 "CAB_11__FlexRay" 262144 "CAB_19__VLAN_RemoteFC" 524288 "CAB_20__VLAN_Komfort" 1048576 "CAB_21__VLAN_Internet" 2097152 "CAB_22__VLAN_Connect" 4194304 "CAB_23__VLAN_Infotainment" 8388608 "CAB_24__VLAN_FAS" ;
VAL_ 2600468676 NM_VAS_L_SNI 196 "VAS_L" ;
VAL_ 2600468676 NM_VAS_L_CBV_AWB 0 "Passiver_WakeUp" 1 "Aktiver_WakeUp" ;
VAL_ 2600468676 NM_VAS_L_CBV_CRI 0 "NM_ohne_Clusteranforderungen" 1 "NM_mit_Clusteranforderungen" ;
VAL_ 2600468676 NM_VAS_L_NM_State 0 "Init" 1 "NM_RM_aus_BSM" 2 "NM_RM_aus_PBSM" 4 "NM_NO_aus_RM" 8 "NM_NO_aus_RS" 16 "reserved" 32 "reserved" ;
VAL_ 2600468676 NM_VAS_L_Car_Wakeup 0 "Inaktiv" 1 "Car_Wakeup" ;
VAL_ 2600468676 NM_VAS_L_UDS_CC 0 "Inaktiv" 1 "CC_aktiv" ;
VAL_ 2600468676 NM_VAS_L_NM_aktiv_KL15 0 "Inaktiv" 1 "KL15_EIN" ;
VAL_ 2600468676 NM_VAS_L_NM_aktiv_Diagnose 0 "Init" 1 "Diagnose_aktiv" ;
VAL_ 2600468676 NM_VAS_L_NM_aktiv_Tmin 0 "Inaktiv" 1 "Mindestaktivzeit" ;
VAL_ 2600468676 NM_VAS_L_NM_aktiv_Verstellung 0 "Inaktiv" 1 "Verstellung_aktiv" ;
VAL_ 2600468676 NM_VAS_L_CAB 0 "inaktiv" 1 "CAB_01__Tueren" 2 "CAB_02__Anhaenger_KCAN" 4 "CAB_03__Nightvision" 8 "CAB_04__Sitzverstellung" 16 "CAB_05__Klappen" 32 "CAB_06__Infotainment" 64 "CAB_07__Sub_Infotainment" 128 "CAB_08__Anzeige" 256 "CAB_09__Laden_HCAN" 512 "CAB_10__Klima" 1024 "CAB_11__FlexRay" 262144 "CAB_19__VLAN_RemoteFC" 524288 "CAB_20__VLAN_Komfort" 1048576 "CAB_21__VLAN_Internet" 2097152 "CAB_22__VLAN_Connect" 4194304 "CAB_23__VLAN_Infotainment" 8388608 "CAB_24__VLAN_FAS" ;
VAL_ 2600468677 NM_VAS_R_SNI 197 "VAS_R" ;
VAL_ 2600468677 NM_VAS_R_CBV_AWB 0 "Passiver_WakeUp" 1 "Aktiver_WakeUp" ;
VAL_ 2600468677 NM_VAS_R_CBV_CRI 0 "NM_ohne_Clusteranforderungen" 1 "NM_mit_Clusteranforderungen" ;
VAL_ 2600468677 NM_VAS_R_NM_State 0 "Init" 1 "NM_RM_aus_BSM" 2 "NM_RM_aus_PBSM" 4 "NM_NO_aus_RM" 8 "NM_NO_aus_RS" 16 "reserved" 32 "reserved" ;
VAL_ 2600468677 NM_VAS_R_Car_Wakeup 0 "Inaktiv" 1 "Car_Wakeup" ;
VAL_ 2600468677 NM_VAS_R_UDS_CC 0 "Inaktiv" 1 "CC_aktiv" ;
VAL_ 2600468677 NM_VAS_R_NM_aktiv_KL15 0 "Inaktiv" 1 "KL15_EIN" ;
VAL_ 2600468677 NM_VAS_R_NM_aktiv_Diagnose 0 "Init" 1 "Diagnose_aktiv" ;
VAL_ 2600468677 NM_VAS_R_NM_aktiv_Tmin 0 "Inaktiv" 1 "Mindestaktivzeit" ;
VAL_ 2600468677 NM_VAS_R_NM_aktiv_Verstellung 0 "Inaktiv" 1 "Verstellung_aktiv" ;
VAL_ 2600468677 NM_VAS_R_CAB 0 "inaktiv" 1 "CAB_01__Tueren" 2 "CAB_02__Anhaenger_KCAN" 4 "CAB_03__Nightvision" 8 "CAB_04__Sitzverstellung" 16 "CAB_05__Klappen" 32 "CAB_06__Infotainment" 64 "CAB_07__Sub_Infotainment" 128 "CAB_08__Anzeige" 256 "CAB_09__Laden_HCAN" 512 "CAB_10__Klima" 1024 "CAB_11__FlexRay" 262144 "CAB_19__VLAN_RemoteFC" 524288 "CAB_20__VLAN_Komfort" 1048576 "CAB_21__VLAN_Internet" 2097152 "CAB_22__VLAN_Connect" 4194304 "CAB_23__VLAN_Infotainment" 8388608 "CAB_24__VLAN_FAS" ;
VAL_ 1377 NV_Obj_01_InvTTCBildebStdA 127 "Init" ;
VAL_ 1377 NV_Obj_Warnung_Fussgaenger 0 "inaktiv" 1 "aktiv" ;
VAL_ 1377 NV_Obj_Rechts 0 "nicht_erkannt" 1 "erkannt" ;
VAL_ 1377 NV_Obj_Links 0 "nicht_erkannt" 1 "erkannt" ;
VAL_ 1377 NV_Obj_01_Klasse 0 "unbekannt" 1 "ueberfahrbar" 2 "unterfahrbar" 3 "Fussgaenger" 4 "Fussgaengergruppe" 5 "Fahrrad" 6 "Motorrad" 7 "PKW" 8 "Van" 9 "LKW" 10 "Randbebauung" 11 "Tier" 12 "Retroreflektor" 15 "Init" ;
VAL_ 1377 NV_MessZeitpunkt 8191 "Init" ;
VAL_ 1377 NV_Sensor_PositionY 2047 "Init" ;
VAL_ 1377 NV_Sensor_PositionX 4095 "Init" ;
VAL_ 1377 NV_Sensor_PositionZ 2047 "Init" ;
VAL_ 1377 NV_NichtVerfuegbar 0 "NV_verfuegbar" 1 "NV_nicht_verfuegbar" ;
VAL_ 1635 BEM_02_Abschaltstufen 0 "Stufe 0 (keine Einschraenkungen)" 1 "Stufe 1" 2 "Stufe 2" 3 "Stufe 3" 4 "Transportmodus" 7 "Ruhestrommessmodus" ;
VAL_ 1635 BEM_STH_Zielzeit 14 "Init" 15 "Fehler" ;
VAL_ 1635 BEM_MMI_Vorwarnung 0 "keine Anzeige" 1 "Anzeige MMI-Vorwarnung" ;
VAL_ 1635 NVEM_Anf_SD_schalten 0 "Anf_SD_Nachlauf_nicht_aktiv" 1 "Anf_SD_Nachlauf_aktiv" ;
VAL_ 1635 BEM_Generatordiagnose 0 "keine Anzeige" 1 "Ladekontrollanzeige ein (Vorhalt)" 2 "rotes Batteriesymbol und Text (Generator defekt)" 3 "Hybrid_DCDC_Wandler_defekt" ;
VAL_ 1635 BEM_Red_Innengeblaese 0 "keine Reduzierung" 1 "Reduzierung Stufe 1" 2 "Reduzierung Stufe 2" 3 "Reduzierung Stufe 2 und Abschaltung Kompressor" ;
VAL_ 1635 BEM_STH_Einschaltverbot 0 "volle Verfuegbarkeit Standheizung/-lueftung" 1 "Standheizung/-lueftung nicht aktivierbar" ;
VAL_ 1635 BEM_HL_Regelung_Status 0 "HL_Regelung_inaktiv_(vor_und_waehrend_Motorstart)" 1 "HL_Regelung_Stufe_1" 2 "HL_Regelung_Stufe_2" 3 "HL_Regelung_Stufe_3" 4 "Verbrauchernotabschaltung_(VNA)" 5 "HL_Regelung_Stufe_5" 7 "Default" ;
VAL_ 1635 BEM_Ladezustand 14 "Init" 15 "Fehler" ;
VAL_ 1635 BEM_Batteriediagnose 0 "keine_Anzeige" 1 "nicht_belegt" 2 "Anzeige_aberkannte_Batterie" 3 "Anzeige_schwache_Batterie" 4 "Anzeige_Batterie_OK" 5 "Anzeige_Batterie_Laden" 6 "Anzeige_Batterie_Pruefen" 7 "Fehler" ;
VAL_ 1635 MIB_Stromsparmodus 0 "inaktiv" 1 "aktiv" ;
VAL_ 1635 BEM_REK_aktiv 0 "keine_Rekuperationsfreigabe" 1 "Rekuperationsfreigabe" ;
VAL_ 1635 NVEM_Last_Anf 0 "keine Anforderung" 1 "Verbraucher_Anforderung_Stufe_1" 2 "Verbraucher_Anforderung_Stufe_2" 3 "Verbraucher_Anforderung_Stufe_3" ;
VAL_ 1635 BEM_UBDM 0 "Init" 255 "Fehler" ;
VAL_ 1635 BEM_Anf_KL15_schalten 0 "Keine_Einschraenkung_Kl15" 1 "Empfehlung_auto_Abschaltung_Kl15" 2 "Veto_auto_Abschaltung_Kl15" 3 "Veto_auto_Abschaltung_Fahrtbetrieb" ;
VAL_ 1635 NVEM_Batterie_Service 0 "kein_Service" 1 "Service_Information1" 2 "Service_Information2" 3 "Service_Information3" ;
VAL_ 1635 NVEM_Freigabe_OnlineUpdate 0 "keine_Freigabe" 1 "Freigabe" ;
VAL_ 1635 NVEM_Freigabe_ORU4 0 "Init" 1 "keine_Freigabe" 2 "Freigabe_erteilt" 3 "Veto_Freigabe" ;
VAL_ 2527679508 NVEM_Max_Rampenzeit 0 "No_LRC" 1 "250ms" 2 "500ms" 3 "750ms" 4 "1s" 5 "2s" 6 "3s" 7 "4s" 8 "5s" 9 "6s" 10 "7s" 11 "8s" 12 "9s" 13 "10s" 14 "12s" 15 "15s" ;
VAL_ 2527679508 NVEM_Min_Spannung 126 "Init" 127 "Fehler" ;
VAL_ 2527679508 NVEM_Min_Spannung_Start 62 "Init" 63 "Fehler" ;
VAL_ 2527679508 NVEM_Max_Spannung 126 "Init" 127 "Fehler" ;
VAL_ 2527679508 NVEM_Energie_Klima_Vorgabe 254 "Init" 255 "Fehler" ;
VAL_ 2527679508 NVEM_MV_DC_uMinLV 126 "Init" 127 "Fehler" ;
VAL_ 2527679508 NVEM_MV_DC_uSollLV 126 "Init" 127 "Fehler" ;
VAL_ 2527679508 NVEM_Bordnetzdiagnose 0 "kein_Fehler" 1 "Warnung_1" 2 "Warnung_2" 3 "Warnung_3" ;
VAL_ 913 MO_Servicemodus 0 "nicht_aktiv" 1 "Service_Mode_1" 2 "Service_Mode_2" 3 "Service_Mode_3" 4 "Service_Mode_4" 5 "Service_Mode_5" 6 "Service_Mode_6" 7 "Service_Mode_7" 8 "Service_Mode_8" 9 "Service_Mode_9" 10 "Service_Mode_10" 11 "Service_Mode_11" 12 "Service_Mode_12" 13 "Service_Mode_13" 14 "Service_Mode_14" 15 "Service_Mode_15" ;
VAL_ 913 OBD_ClearMem_Inhibit 0 "FSP_Loeschen_zulaessig" 1 "FSP_Loeschen_nicht_zulaessig" ;
VAL_ 913 OBD_Sperrung_Kaltstart_Denom 0 "EVAP_Berechnung_freigegeben" 1 "EVAP_Berechnung_gesperrt" ;
VAL_ 913 MO_QBit_Aussen_Temp 0 "gueltiger_Wert" 1 "Ersatz_Init_oder_Fehlerwert" ;
VAL_ 913 OBD_Sperrung_IUMPR 0 "IUMPR_Berechnung_freigegeben" 1 "IUMPR_Berechnung_gesperrt" ;
VAL_ 913 OBD_Kaltstart_Denominator 0 "Denominator_nicht_hochzaehlen" 1 "Bedingungen_zum_Inkr_des_Kaltstart_Denom_erf" ;
VAL_ 913 OBD_Minimum_Trip 0 "kein_Min_Normed_Trip" 1 "Min_Normed_Trip" ;
VAL_ 913 OBD_Driving_Cycle 0 "kein_Driving_Cycle_erkannt" 1 "Driving_Cycle_erkannt" ;
VAL_ 913 OBD_Warm_Up_Cycle 0 "kein_Warm_Up_Cycle_erkannt" 1 "Warm_Up_Cycle_erkannt" ;
VAL_ 913 OBD_Normed_Trip 0 "kein_Normed_Trip" 1 "Normed_Trip" ;
